VERSION ""

NS_ :

BS_:

BU_: BCMB_AUXM FCIM MRCMA_RSCM SCMJ BCMB_ALCM SCMB_PSM SCMD SCMC HVAC_RCCM MRCMB MRCMA DASM GFM_FTRM BCMB_CAPM DCMH SFMB SFMA SOBDMD_AHCM_FOH TRM GWM _delete BCMB_ABM SODL SCMF RTM RHVAC PDM DCMG DCMF DCME SCMH SCMG HSWM RSM SODR DDM RBM RGTM DSM SCME GENERIC TSTR

BO_ 839 FuelOpHeater_Stat: 8 SOBDMD_AHCM_FOH
 SG_ FohStop_B_Stat : 49|2@0+ (1,0) [0|3] "SED"  GWM
 SG_ FohMsgTxt_D_Rq : 4|3@0+ (1,0) [0|7] "SED"  GWM
 SG_ FohKeyOff_B_Rq : 6|1@0+ (1,0) [0|1] "SED"  GWM
 SG_ FohEnbl_B_Rq : 7|1@0+ (1,0) [0|1] "SED"  GWM
 SG_ FohTAllEnable_B_Stat : 17|2@0+ (1,0) [0|3] "SED"  GWM
 SG_ FohT2Mnte_T_Stat : 55|6@0+ (1,0) [0|63] "minute"  GWM
 SG_ FohT2Hr_T_Stat : 47|5@0+ (1,0) [0|31] "hour"  GWM
 SG_ FohT2Enable_B_Stat : 63|1@0+ (1,0) [0|1] "SED"  GWM
 SG_ FohT1Mnte_T_Stat : 39|6@0+ (1,0) [0|63] "minute"  GWM
 SG_ FohT1Hr_T_Stat : 31|5@0+ (1,0) [0|31] "hour"  GWM
 SG_ FohT1Enable_B_Stat : 0|1@0+ (1,0) [0|1] "SED"  GWM
 SG_ FohStrtMnte_T_Stat : 23|6@0+ (1,0) [0|63] "minute"  GWM
 SG_ FohStrtHr_T_Stat : 15|5@0+ (1,0) [0|31] "hour"  GWM
 SG_ FohStrtEnable_B_Stat : 1|1@0+ (1,0) [0|1] "SED"  GWM
 SG_ FohContOn_B_Stat : 33|2@0+ (1,0) [0|3] "SED"  GWM
 SG_ FohStrtDay_T_Stat : 10|3@0+ (1,0) [0|7] "SED"  GWM
 SG_ FohT2Wednesday_T_Stat : 56|1@0+ (1,0) [0|1] "SED"  GWM
 SG_ FohT2Tuesday_T_Stat : 57|1@0+ (1,0) [0|1] "SED"  GWM
 SG_ FohT2Thursday_T_Stat : 58|1@0+ (1,0) [0|1] "SED"  GWM
 SG_ FohT2Sunday_T_Stat : 59|1@0+ (1,0) [0|1] "SED"  GWM
 SG_ FohT2Saturday_T_Stat : 60|1@0+ (1,0) [0|1] "SED"  GWM
 SG_ FohT2Monday_T_Stat : 61|1@0+ (1,0) [0|1] "SED"  GWM
 SG_ FohT2Friday_T_Stat : 62|1@0+ (1,0) [0|1] "SED"  GWM
 SG_ FohT1Wednesday_T_Stat : 40|1@0+ (1,0) [0|1] "SED"  GWM
 SG_ FohT1Tuesday_T_Stat : 41|1@0+ (1,0) [0|1] "SED"  GWM
 SG_ FohT1Thursday_T_Stat : 42|1@0+ (1,0) [0|1] "SED"  GWM
 SG_ FohT1Sunday_T_Stat : 24|1@0+ (1,0) [0|1] "SED"  GWM
 SG_ FohT1Saturday_T_Stat : 25|1@0+ (1,0) [0|1] "SED"  GWM
 SG_ FohT1Monday_T_Stat : 26|1@0+ (1,0) [0|1] "SED"  GWM
 SG_ FohT1Friday_T_Stat : 5|1@0+ (1,0) [0|1] "SED"  GWM

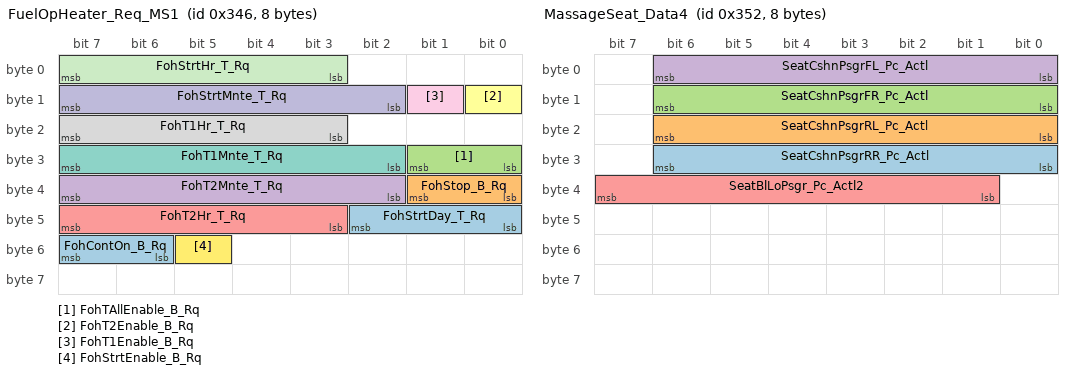
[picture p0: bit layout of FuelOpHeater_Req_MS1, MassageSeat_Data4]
BO_ 838 FuelOpHeater_Req_MS1: 8 GWM
 SG_ FohStrtDay_T_Rq : 42|3@0+ (1,0) [0|7] "SED"  SOBDMD_AHCM_FOH
 SG_ FohStop_B_Rq : 33|2@0+ (1,0) [0|3] "SED"  SOBDMD_AHCM_FOH
 SG_ FohTAllEnable_B_Rq : 25|2@0+ (1,0) [0|3] "SED"  SOBDMD_AHCM_FOH
 SG_ FohT2Mnte_T_Rq : 39|6@0+ (1,0) [0|63] "minute"  SOBDMD_AHCM_FOH
 SG_ FohT2Hr_T_Rq : 47|5@0+ (1,0) [0|31] "hour"  SOBDMD_AHCM_FOH
 SG_ FohT2Enable_B_Rq : 8|1@0+ (1,0) [0|1] "SED"  SOBDMD_AHCM_FOH
 SG_ FohT1Mnte_T_Rq : 31|6@0+ (1,0) [0|63] "minute"  SOBDMD_AHCM_FOH
 SG_ FohT1Hr_T_Rq : 23|5@0+ (1,0) [0|31] "hour"  SOBDMD_AHCM_FOH
 SG_ FohT1Enable_B_Rq : 9|1@0+ (1,0) [0|1] "SED"  SOBDMD_AHCM_FOH
 SG_ FohStrtMnte_T_Rq : 15|6@0+ (1,0) [0|63] "minute"  SOBDMD_AHCM_FOH
 SG_ FohStrtHr_T_Rq : 7|5@0+ (1,0) [0|31] "hour"  SOBDMD_AHCM_FOH
 SG_ FohStrtEnable_B_Rq : 53|1@0+ (1,0) [0|1] "SED"  SOBDMD_AHCM_FOH
 SG_ FohContOn_B_Rq : 55|2@0+ (1,0) [0|3] "SED"  SOBDMD_AHCM_FOH

BO_ 850 MassageSeat_Data4: 8 SCMH
 SG_ SeatCshnPsgrRR_Pc_Actl : 30|7@0+ (1,0) [0|126] "Percent"  GWM
 SG_ SeatCshnPsgrRL_Pc_Actl : 22|7@0+ (1,0) [0|126] "Percent"  GWM
 SG_ SeatCshnPsgrFR_Pc_Actl : 14|7@0+ (1,0) [0|126] "Percent"  GWM
 SG_ SeatCshnPsgrFL_Pc_Actl : 6|7@0+ (1,0) [0|126] "Percent"  GWM
 SG_ SeatBlLoPsgr_Pc_Actl2 : 39|7@0+ (1,0) [0|126] "Percent"  GWM

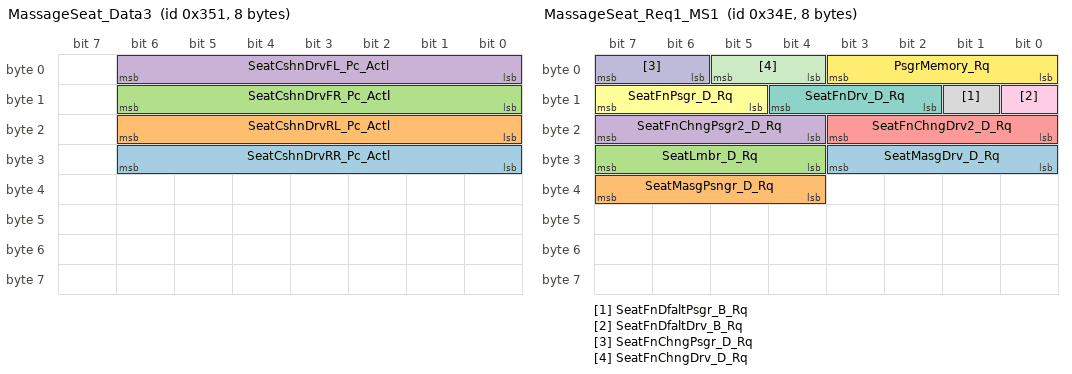
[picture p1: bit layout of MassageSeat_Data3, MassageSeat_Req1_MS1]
BO_ 849 MassageSeat_Data3: 8 SCMG
 SG_ SeatCshnDrvRR_Pc_Actl : 30|7@0+ (1,0) [0|126] "Percent"  GWM
 SG_ SeatCshnDrvRL_Pc_Actl : 22|7@0+ (1,0) [0|126] "Percent"  GWM
 SG_ SeatCshnDrvFR_Pc_Actl : 14|7@0+ (1,0) [0|126] "Percent"  GWM
 SG_ SeatCshnDrvFL_Pc_Actl : 6|7@0+ (1,0) [0|126] "Percent"  GWM

BO_ 846 MassageSeat_Req1_MS1: 8 GWM
 SG_ SeatMasgDrv_D_Rq : 27|4@0+ (1,0) [0|15] "SED"  SCMG
 SG_ SeatMasgPsngr_D_Rq : 39|4@0+ (1,0) [0|15] "SED"  SCMH
 SG_ SeatLmbr_D_Rq : 31|4@0+ (1,0) [0|15] "SED"  DSM,SCMB_PSM
 SG_ SeatFnChngPsgr2_D_Rq : 23|4@0+ (1,0) [0|15] "SED"  SCMG,SCMH
 SG_ SeatFnChngDrv2_D_Rq : 19|4@0+ (1,0) [0|15] "SED"  SCMG,SCMH
 SG_ SeatFnPsgr_D_Rq : 15|3@0+ (1,0) [0|7] "SED"  SCMH,SCMG
 SG_ SeatFnDrv_D_Rq : 12|3@0+ (1,0) [0|7] "SED"  SCMH,SCMG
 SG_ SeatFnDfaltPsgr_B_Rq : 9|1@0+ (1,0) [0|1] "SED"  SCMH,SCMG
 SG_ SeatFnDfaltDrv_B_Rq : 8|1@0+ (1,0) [0|1] "SED"  SCMH,SCMG
 SG_ SeatFnChngPsgr_D_Rq : 7|2@0+ (1,0) [0|3] "SED"  SCMH,SCMG
 SG_ SeatFnChngDrv_D_Rq : 5|2@0+ (1,0) [0|3] "SED"  SCMH,SCMG
 SG_ PsgrMemory_Rq : 3|4@0+ (1,0) [0|15] "SED"  SCMH,SCMG

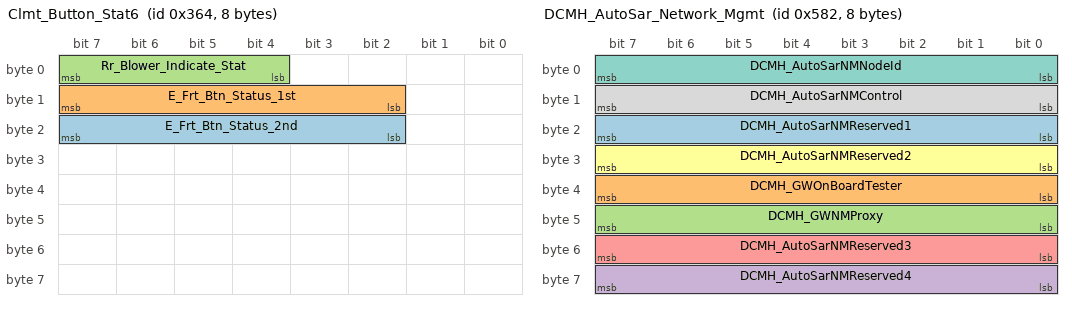
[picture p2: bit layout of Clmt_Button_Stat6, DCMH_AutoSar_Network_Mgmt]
BO_ 868 Clmt_Button_Stat6: 8 HVAC_RCCM
 SG_ E_Frt_Btn_Status_2nd : 23|6@0+ (1,0) [0|63] "SED"  GWM
 SG_ E_Frt_Btn_Status_1st : 15|6@0+ (1,0) [0|63] "SED"  GWM
 SG_ Rr_Blower_Indicate_Stat : 7|4@0+ (1,0) [0|15] "SED"  RHVAC

BO_ 1962 TesterPhysicalResDCME: 8 DCME
 SG_ TesterPhysicalResDCME : 7|64@0+ (1,0) [0|1.84467E+019] "unitless"  TSTR

BO_ 1410 DCMH_AutoSar_Network_Mgmt: 8 DCMH
 SG_ DCMH_AutoSarNMReserved1 : 23|8@0+ (1,0) [0|255] "unitless"  GWM
 SG_ DCMH_GWOnBoardTester : 39|8@0+ (1,0) [0|255] "unitless"  GWM
 SG_ DCMH_GWNMProxy : 47|8@0+ (1,0) [0|255] "unitless"  GWM
 SG_ DCMH_AutoSarNMReserved4 : 63|8@0+ (1,0) [0|255] "unitless"  GWM
 SG_ DCMH_AutoSarNMReserved3 : 55|8@0+ (1,0) [0|255] "unitless"  GWM
 SG_ DCMH_AutoSarNMReserved2 : 31|8@0+ (1,0) [0|255] "unitless"  GWM
 SG_ DCMH_AutoSarNMNodeId : 7|8@0+ (1,0) [0|255] "unitless"  GWM
 SG_ DCMH_AutoSarNMControl : 15|8@0+ (1,0) [0|255] "unitless"  GWM

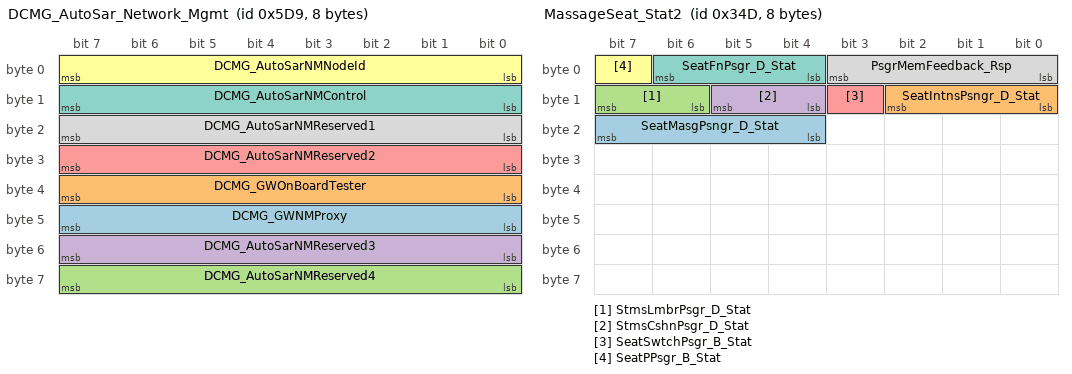
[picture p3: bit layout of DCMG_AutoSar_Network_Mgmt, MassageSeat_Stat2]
BO_ 1497 DCMG_AutoSar_Network_Mgmt: 8 DCMG
 SG_ DCMG_GWNMProxy : 47|8@0+ (1,0) [0|255] "unitless"  GWM
 SG_ DCMG_GWOnBoardTester : 39|8@0+ (1,0) [0|255] "unitless"  GWM
 SG_ DCMG_AutoSarNMReserved4 : 63|8@0+ (1,0) [0|255] "unitless"  GWM
 SG_ DCMG_AutoSarNMReserved3 : 55|8@0+ (1,0) [0|255] "unitless"  GWM
 SG_ DCMG_AutoSarNMReserved2 : 31|8@0+ (1,0) [0|255] "unitless"  GWM
 SG_ DCMG_AutoSarNMNodeId : 7|8@0+ (1,0) [0|255] "unitless"  GWM
 SG_ DCMG_AutoSarNMControl : 15|8@0+ (1,0) [0|255] "unitless"  GWM
 SG_ DCMG_AutoSarNMReserved1 : 23|8@0+ (1,0) [0|255] "unitless"  GWM

BO_ 1805 TesterPhysicalResSFMB: 8 SFMB
 SG_ TesterPhysicalResSFMB : 7|64@0+ (1,0) [0|1.84467E+019] "unitless"  TSTR

BO_ 845 MassageSeat_Stat2: 8 SCMH
 SG_ SeatMasgPsngr_D_Stat : 23|4@0+ (1,0) [0|15] "SED"  GWM
 SG_ SeatIntnsPsngr_D_Stat : 10|3@0+ (1,0) [0|7] "SED"  GWM
 SG_ StmsLmbrPsgr_D_Stat : 15|2@0+ (1,0) [0|3] "SED"  GWM
 SG_ StmsCshnPsgr_D_Stat : 13|2@0+ (1,0) [0|3] "SED"  GWM
 SG_ SeatSwtchPsgr_B_Stat : 11|1@0+ (1,0) [0|1] "SED"  GWM
 SG_ SeatPPsgr_B_Stat : 7|1@0+ (1,0) [0|1] "SED"  GWM
 SG_ SeatFnPsgr_D_Stat : 6|3@0+ (1,0) [0|7] "SED"  GWM
 SG_ PsgrMemFeedback_Rsp : 3|4@0+ (1,0) [0|15] "SED"  GWM

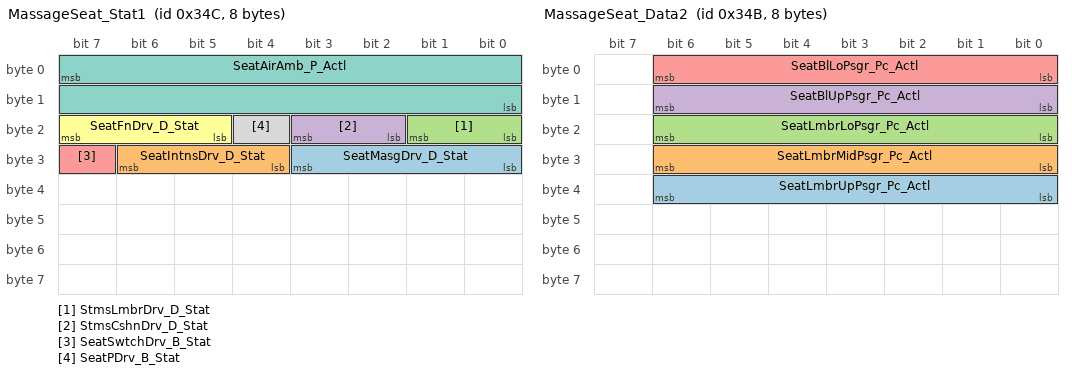
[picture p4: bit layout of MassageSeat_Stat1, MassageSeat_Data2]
BO_ 844 MassageSeat_Stat1: 8 SCMG
 SG_ SeatMasgDrv_D_Stat : 27|4@0+ (1,0) [0|15] "SED"  GWM
 SG_ SeatIntnsDrv_D_Stat : 30|3@0+ (1,0) [0|7] "SED"  GWM
 SG_ StmsLmbrDrv_D_Stat : 17|2@0+ (1,0) [0|3] "SED"  GWM
 SG_ StmsCshnDrv_D_Stat : 19|2@0+ (1,0) [0|3] "SED"  GWM
 SG_ SeatSwtchDrv_B_Stat : 31|1@0+ (1,0) [0|1] "SED"  GWM
 SG_ SeatFnDrv_D_Stat : 23|3@0+ (1,0) [0|7] "SED"  GWM
 SG_ SeatAirAmb_P_Actl : 7|16@0+ (0.01,0) [0|655.35] "KiloPascal"  GWM,SCMH
 SG_ SeatPDrv_B_Stat : 20|1@0+ (1,0) [0|1] "SED"  GWM

BO_ 843 MassageSeat_Data2: 8 SCMH
 SG_ SeatLmbrUpPsgr_Pc_Actl : 38|7@0+ (1,0) [0|127] "Percent"  GWM
 SG_ SeatLmbrMidPsgr_Pc_Actl : 30|7@0+ (1,0) [0|127] "Percent"  GWM
 SG_ SeatLmbrLoPsgr_Pc_Actl : 22|7@0+ (1,0) [0|127] "Percent"  GWM
 SG_ SeatBlUpPsgr_Pc_Actl : 14|7@0+ (1,0) [0|126] "Percent"  GWM
 SG_ SeatBlLoPsgr_Pc_Actl : 6|7@0+ (1,0) [0|126] "Percent"  GWM

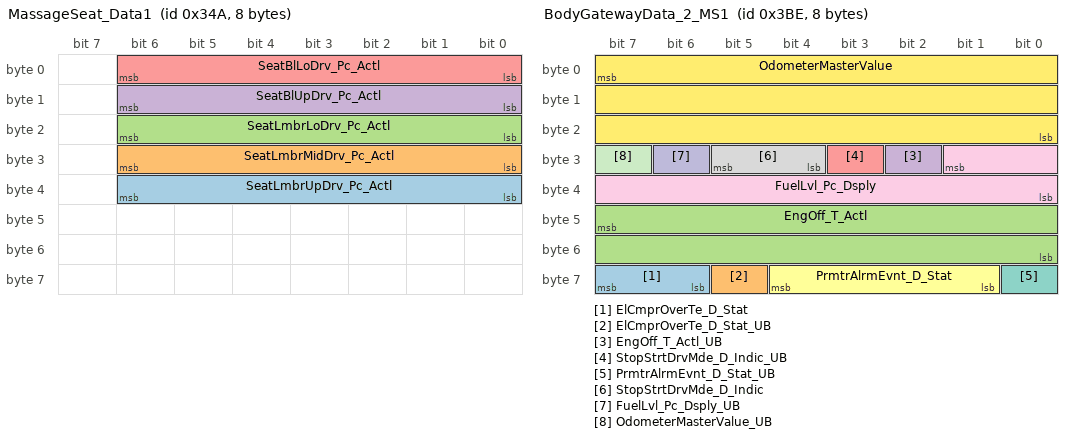
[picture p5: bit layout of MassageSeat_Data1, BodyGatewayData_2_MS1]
BO_ 842 MassageSeat_Data1: 8 SCMG
 SG_ SeatLmbrUpDrv_Pc_Actl : 38|7@0+ (1,0) [0|127] "Percent"  GWM
 SG_ SeatLmbrMidDrv_Pc_Actl : 30|7@0+ (1,0) [0|127] "Percent"  GWM
 SG_ SeatLmbrLoDrv_Pc_Actl : 22|7@0+ (1,0) [0|127] "Percent"  GWM
 SG_ SeatBlUpDrv_Pc_Actl : 14|7@0+ (1,0) [0|126] "Percent"  GWM
 SG_ SeatBlLoDrv_Pc_Actl : 6|7@0+ (1,0) [0|126] "Percent"  GWM

BO_ 1994 TesterPhysicalResRSM: 8 RSM
 SG_ TesterPhysicalResRSM : 7|64@0+ (1,0) [0|1.84467E+019] "unitless"  TSTR

BO_ 1986 TesterPhysicalReqRSM: 8 TSTR
 SG_ TesterPhysicalReqRSM : 7|64@0+ (1,0) [0|1.84467E+019] "unitless"  RSM

BO_ 958 BodyGatewayData_2_MS1: 8 GWM
 SG_ ElCmprOverTe_D_Stat : 63|2@0+ (1,0) [0|3] "SED"  FCIM,HVAC_RCCM
 SG_ ElCmprOverTe_D_Stat_UB : 61|1@0+ (1,0) [0|1] "SED"  FCIM,HVAC_RCCM
 SG_ EngOff_T_Actl : 47|16@0+ (1,0) [0|65534] "second^0.5"  FCIM,HVAC_RCCM
 SG_ EngOff_T_Actl_UB : 26|1@0+ (1,0) [0|1] "SED"  FCIM,HVAC_RCCM
 SG_ StopStrtDrvMde_D_Indic_UB : 27|1@0+ (1,0) [0|1] "SED"  FCIM,HVAC_RCCM
 SG_ PrmtrAlrmEvnt_D_Stat : 60|4@0+ (1,0) [0|15] "SED"  RSM
 SG_ PrmtrAlrmEvnt_D_Stat_UB : 56|1@0+ (1,0) [0|1] "SED"  RSM
 SG_ StopStrtDrvMde_D_Indic : 29|2@0+ (1,0) [0|3] "SED"  FCIM,HVAC_RCCM
 SG_ FuelLvl_Pc_Dsply : 25|10@0+ (0.108696,-5.217408) [-5.217408|105.9786] "Percent"  SOBDMD_AHCM_FOH
 SG_ FuelLvl_Pc_Dsply_UB : 30|1@0+ (1,0) [0|1] "SED"  SOBDMD_AHCM_FOH
 SG_ OdometerMasterValue_UB : 31|1@0+ (1,0) [0|1] "SED"  FCIM,DCMG,DCMH,HVAC_RCCM,SOBDMD_AHCM_FOH,RGTM
 SG_ OdometerMasterValue : 7|24@0+ (1,0) [0|16777214] "km"  FCIM,DCMG,DCMH,HVAC_RCCM,SOBDMD_AHCM_FOH,RGTM

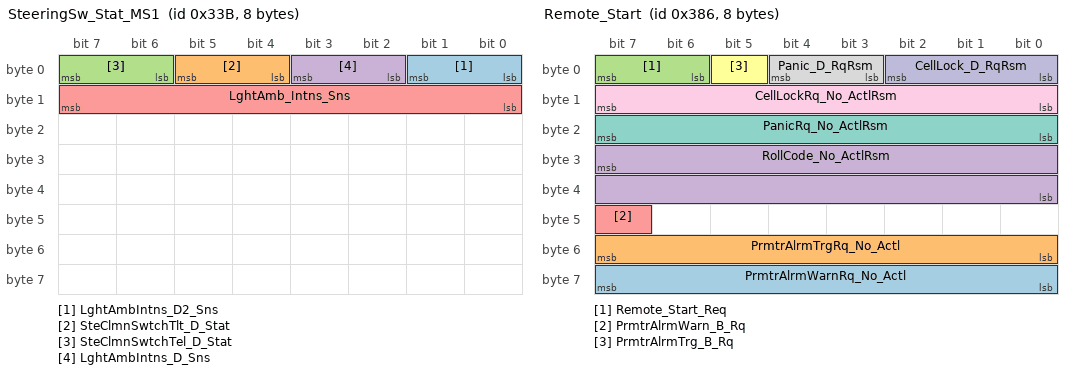
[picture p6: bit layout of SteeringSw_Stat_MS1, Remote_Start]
BO_ 827 SteeringSw_Stat_MS1: 8 GWM
 SG_ LghtAmbIntns_D2_Sns : 1|2@0+ (1,0) [0|3] "SED"  GENERIC
 SG_ SteClmnSwtchTlt_D_Stat : 5|2@0+ (1,0) [0|3] "SED"  BCMB_CAPM,DSM
 SG_ SteClmnSwtchTel_D_Stat : 7|2@0+ (1,0) [0|3] "SED"  BCMB_CAPM,DSM
 SG_ LghtAmbIntns_D_Sns : 3|2@0+ (1,0) [0|3] "SED"  GENERIC
 SG_ LghtAmb_Intns_Sns : 15|8@0+ (1,0) [0|255] "unitless"  GENERIC

BO_ 902 Remote_Start: 8 RSM
 SG_ PrmtrAlrmWarnRq_No_Actl : 63|8@0+ (1,0) [0|255] "unitless"  GWM
 SG_ PrmtrAlrmTrgRq_No_Actl : 55|8@0+ (1,0) [0|255] "unitless"  GWM
 SG_ Remote_Start_Req : 7|2@0+ (1,0) [0|3] "SED"  GWM
 SG_ RollCode_No_ActlRsm : 31|16@0+ (1,0) [0|65535] "unitless"  GWM
 SG_ PrmtrAlrmWarn_B_Rq : 47|1@0+ (1,0) [0|1] "SED"  GWM
 SG_ PrmtrAlrmTrg_B_Rq : 5|1@0+ (1,0) [0|1] "SED"  GWM
 SG_ PanicRq_No_ActlRsm : 23|8@0+ (1,0) [0|255] "unitless"  GWM
 SG_ Panic_D_RqRsm : 4|2@0+ (1,0) [0|3] "SED"  GWM
 SG_ CellLockRq_No_ActlRsm : 15|8@0+ (1,0) [0|255] "unitless"  GWM
 SG_ CellLock_D_RqRsm : 2|3@0+ (1,0) [0|7] "SED"  GWM

BO_ 765 GatewayData_MS1: 8 GWM
 SG_ CcStat_D_Actl_UB : 48|1@0+ (1,0) [0|1] "SED"  FCIM,HVAC_RCCM
 SG_ CcStat_D_Actl : 51|3@0+ (1,0) [0|7] "SED"  FCIM,HVAC_RCCM
 SG_ PrplTqMnSat_B_Actl_UB : 52|1@0+ (1,0) [0|1] "SED"  FCIM,HVAC_RCCM
 SG_ PrplTqMnSat_B_Actl : 53|1@0+ (1,0) [0|1] "SED"  FCIM,HVAC_RCCM
 SG_ ClimtBlwrLim_B_Rq : 61|1@0+ (1,0) [0|1] "SED"  FCIM,HVAC_RCCM
 SG_ ClimtBlwrLim_B_Rq_UB : 60|1@0+ (1,0) [0|1] "SED"  FCIM,HVAC_RCCM
 SG_ TrlrBrkActCnnct_B_Actl_UB : 62|1@0+ (1,0) [0|1] "SED"  SODR,SODL
 SG_ TrlrBrkActCnnct_B_Actl : 63|1@0+ (1,0) [0|1] "SED"  SODR,SODL
 SG_ EmPrflButtnAssoc_D_Rq : 17|2@0+ (1,0) [0|3] "SED"  DSM
 SG_ EmPrflButtnAssoc_D_Rq_UB : 56|1@0+ (1,0) [0|1] "SED"  DSM
 SG_ CamraFrntStat_D_Stat_UB : 32|1@0+ (1,0) [0|1] "SED"  FCIM,HVAC_RCCM
 SG_ CamraFrntStat_D_Stat : 34|2@0+ (1,0) [0|3] "SED"  FCIM,HVAC_RCCM
 SG_ AutoHoldSwMde_B_Ind_UB : 46|1@0+ (1,0) [0|1] "SED"  FCIM,HVAC_RCCM
 SG_ AutoHoldSwMde_B_Ind : 47|1@0+ (1,0) [0|1] "SED"  FCIM,HVAC_RCCM
 SG_ ValetMode_D_Stat_UB : 35|1@0+ (1,0) [0|1] "SED"  DSM
 SG_ ValetMode_D_Stat : 25|2@0+ (1,0) [0|3] "SED"  DSM
 SG_ SteWhlHeat_D_Stat : 39|4@0+ (1,0) [0|15] "SED"  FCIM,HVAC_RCCM
 SG_ Running_Board_Cmd_UB : 27|1@0+ (1,0) [0|1] "SED"  DSM,RBM
 SG_ Running_Board_Cmd : 29|2@0+ (1,0) [0|3] "SED"  DSM,RBM
 SG_ Bezel_Beeps_Rq_UB : 18|1@0+ (1,0) [0|1] "SED"  FCIM,HVAC_RCCM
 SG_ Bezel_Beeps_Rq : 20|2@0+ (1,0) [0|3] "SED"  FCIM,HVAC_RCCM
 SG_ Diagnostic_Operation_Rq_UB : 21|1@0+ (1,0) [0|1] "SED"  FCIM,HVAC_RCCM
 SG_ Bezel_Diag_State_Rq_UB : 23|1@0+ (1,0) [0|1] "SED"  FCIM,HVAC_RCCM
 SG_ Bezel_Diag_Module_Rq_UB : 22|1@0+ (1,0) [0|1] "SED"  FCIM,HVAC_RCCM
 SG_ Diagnostic_Operation_Rq : 11|4@0+ (1,0) [0|15] "SED"  FCIM,HVAC_RCCM
 SG_ Bezel_Diag_State_Rq : 1|2@0+ (1,0) [0|3] "SED"  FCIM,HVAC_RCCM
 SG_ Bezel_Diag_Module_Rq : 15|4@0+ (1,0) [0|15] "SED"  FCIM,HVAC_RCCM
 SG_ HMI_HMIMode_St_UB : 2|1@0+ (1,0) [0|1] "SED"  FCIM,DDM,PDM,DCME,DCMF,DCMG,DCMH,HVAC_RCCM,RGTM
 SG_ HMI_HMIMode_St : 5|3@0+ (1,0) [0|7] "SED"  FCIM,DDM,PDM,DCME,DCMF,DCMG,DCMH,HVAC_RCCM,RGTM
 SG_ Mc_VehUnitTempUsrSel_St_UB : 6|1@0+ (1,0) [0|1] "SED"  FCIM,HVAC_RCCM
 SG_ Mc_VehUnitTempUsrSel_St : 7|1@0+ (1,0) [0|1] "SED"  FCIM,HVAC_RCCM
 SG_ PsngrFrntDetct_D_Actl_UB : 40|1@0+ (1,0) [0|1] "SED"  FCIM,HVAC_RCCM
 SG_ PsngrFrntDetct_D_Actl : 55|2@0+ (1,0) [0|3] "SED"  FCIM,HVAC_RCCM
 SG_ SteWhlHeat_D_Stat_UB : 26|1@0+ (1,0) [0|1] "SED"  FCIM,HVAC_RCCM
 SG_ PrkAidLamp_D_Rq : 43|2@0+ (1,0) [0|3] "SED"  GENERIC
 SG_ PrkAidLamp_D_Rq_UB : 41|1@0+ (1,0) [0|1] "SED"  GENERIC
 SG_ ParkDetect_Stat_UB : 30|1@0+ (1,0) [0|1] "SED"  RSM
 SG_ ParkDetect_Stat : 31|1@0+ (1,0) [0|1] "SED"  RSM
 SG_ Voice_Blower_Limit : 45|1@0+ (1,0) [0|1] "SED"  FCIM,GENERIC,HVAC_RCCM
 SG_ Voice_Blower_Limit_UB : 44|1@0+ (1,0) [0|1] "SED"  FCIM,GENERIC,HVAC_RCCM
 SG_ PwStep_D_DrvInhbt_UB : 57|1@0+ (1,0) [0|1] "SED"  DSM,RBM
 SG_ PwStep_D_DrvInhbt : 59|2@0+ (1,0) [0|3] "SED"  DSM,RBM

BO_ 710 BEZEL_RDISP_WORD_Tx: 8 HVAC_RCCM
 SG_ BEZEL_RDISP_WORD_Tx : 7|64@0+ (1,0) [0|1.84467440737096E+019] "unitless"  GWM

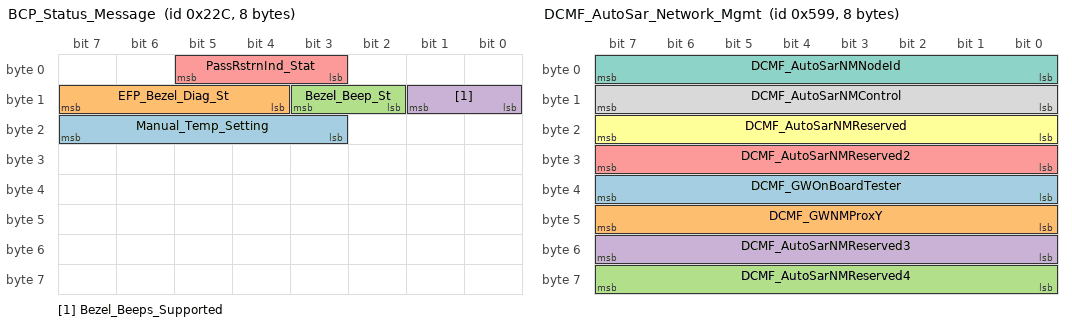
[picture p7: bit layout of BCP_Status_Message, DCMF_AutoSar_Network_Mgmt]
BO_ 556 BCP_Status_Message: 8 FCIM
 SG_ Manual_Temp_Setting : 23|5@0+ (1,0) [0|31] "SED"  GWM
 SG_ EFP_Bezel_Diag_St : 15|4@0+ (1,0) [0|15] "SED"  GWM
 SG_ Bezel_Beep_St : 11|2@0+ (1,0) [0|3] "SED"  GWM
 SG_ Bezel_Beeps_Supported : 9|2@0+ (1,0) [0|3] "SED"  GWM
 SG_ PassRstrnInd_Stat : 5|3@0+ (1,0) [0|7] "SED"  GWM

BO_ 1815 TesterPhysicalReqRLCMA: 8 TSTR
 SG_ TesterPhysicalReqRLCMA : 7|64@0+ (1,0) [0|1.84467E+019] "unitless"  GENERIC

BO_ 1433 DCMF_AutoSar_Network_Mgmt: 8 DCMF
 SG_ DCMF_GWOnBoardTester : 39|8@0+ (1,0) [0|255] "unitless"  GWM
 SG_ DCMF_GWNMProxY : 47|8@0+ (1,0) [0|255] "unitless"  GWM
 SG_ DCMF_AutoSarNMReserved4 : 63|8@0+ (1,0) [0|255] "unitless"  GWM
 SG_ DCMF_AutoSarNMReserved3 : 55|8@0+ (1,0) [0|255] "unitless"  GWM
 SG_ DCMF_AutoSarNMReserved2 : 31|8@0+ (1,0) [0|255] "unitless"  GWM
 SG_ DCMF_AutoSarNMReserved : 23|8@0+ (1,0) [0|255] "unitless"  GWM
 SG_ DCMF_AutoSarNMNodeId : 7|8@0+ (1,0) [0|255] "unitless"  GWM
 SG_ DCMF_AutoSarNMControl : 15|8@0+ (1,0) [0|255] "unitless"  GWM

BO_ 1983 TesterPhysicalResBCMB: 8 BCMB_ABM
 SG_ TesterPhysicalResBCMB : 7|64@0+ (1,0) [0|1.84467E+019] "unitless"  TSTR

BO_ 1975 TesterPhysicalReqBCMB: 8 TSTR
 SG_ TesterPhysicalReqBCMB : 7|64@0+ (1,0) [0|1.84467E+019] "unitless"  BCMB_AUXM,BCMB_CAPM,BCMB_ALCM,BCMB_ABM

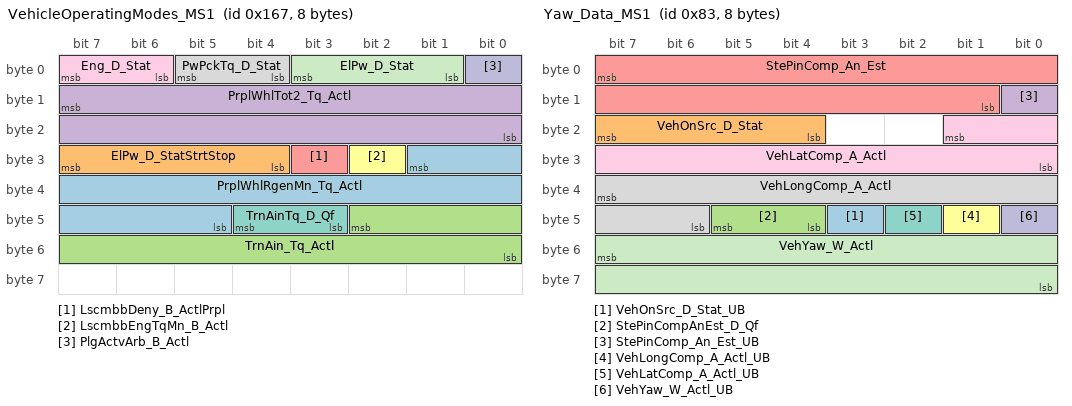
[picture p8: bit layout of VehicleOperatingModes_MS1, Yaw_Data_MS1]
BO_ 359 VehicleOperatingModes_MS1: 8 GWM
 SG_ PrplWhlRgenMn_Tq_Actl : 25|13@0+ (4,-16380) [-16380|16380] "Nm"  GENERIC
 SG_ ElPw_D_StatStrtStop : 31|4@0+ (1,0) [0|15] "SED"  GENERIC
 SG_ TrnAin_Tq_Actl : 42|11@0+ (1,-500) [-500|1547] "Nm"  GENERIC
 SG_ PrplWhlTot2_Tq_Actl : 15|16@0+ (4,-131072) [-131072|131060] "Nm"  GENERIC
 SG_ LscmbbDeny_B_ActlPrpl : 27|1@0+ (1,0) [0|1] "SED"  GENERIC
 SG_ LscmbbEngTqMn_B_Actl : 26|1@0+ (1,0) [0|1] "SED"  GENERIC
 SG_ TrnAinTq_D_Qf : 44|2@0+ (1,0) [0|3] "SED"  GENERIC
 SG_ PwPckTq_D_Stat : 5|2@0+ (1,0) [0|3] "SED"  FCIM,GFM_FTRM,MRCMA_RSCM,SCMB_PSM,SCME,HVAC_RCCM,MRCMA,MRCMB,DCME,DCMF,DCMG,DCMH,RSM,RHVAC,BCMB_CAPM,HSWM,TRM,SCMH,SCMG,SCMF,RTM,RGTM,RBM,PDM,DSM,DDM,SOBDMD_AHCM_FOH
 SG_ Eng_D_Stat : 7|2@0+ (1,0) [0|3] "SED"  TRM,FCIM,HVAC_RCCM,SOBDMD_AHCM_FOH
 SG_ PlgActvArb_B_Actl : 0|1@0+ (1,0) [0|1] "SED"  GENERIC
 SG_ ElPw_D_Stat : 3|3@0+ (1,0) [0|7] "SED"  FCIM,GFM_FTRM,SODR,MRCMA_RSCM,SODL,SCMB_PSM,SCME,HVAC_RCCM,MRCMA,MRCMB,DCME,DCMF,DCMG,DCMH,RHVAC,BCMB_CAPM,SCMG,SCMH,TRM,SOBDMD_AHCM_FOH,DDM,DSM,PDM,RBM,RGTM,RTM,SCMF

BO_ 131 Yaw_Data_MS1: 8 GWM
 SG_ VehOnSrc_D_Stat_UB : 43|1@0+ (1,0) [0|1] "SED"  GFM_FTRM,DSM,HVAC_RCCM,DDM,PDM
 SG_ VehOnSrc_D_Stat : 23|4@0+ (1,0) [0|15] "SED"  GFM_FTRM,DSM,HVAC_RCCM,DDM,PDM
 SG_ StePinCompAnEst_D_Qf : 45|2@0+ (1,0) [0|3] "SED"  GENERIC,SODR,SODL
 SG_ StePinComp_An_Est_UB : 8|1@0+ (1,0) [0|1] "SED"  GENERIC,SODR,SODL
 SG_ StePinComp_An_Est : 7|15@0+ (0.1,-1600) [-1600|1676.7] "degrees"  SODR,GENERIC,SODL
 SG_ VehLongComp_A_Actl_UB : 41|1@0+ (1,0) [0|1] "SED"  DCMG,DCMH,RGTM
 SG_ VehLatComp_A_Actl_UB : 42|1@0+ (1,0) [0|1] "SED"  RGTM
 SG_ VehLongComp_A_Actl : 39|10@0+ (0.035,-17.9) [-17.9|17.835] "m/s^2"  DCMG,DCMH,RGTM
 SG_ VehLatComp_A_Actl : 17|10@0+ (0.035,-17.9) [-17.9|17.835] "m/s^2"  RGTM
 SG_ VehYaw_W_Actl_UB : 40|1@0+ (1,0) [0|1] "SED"  GENERIC,SODR,SODL
 SG_ VehYaw_W_Actl : 55|16@0+ (0.0002,-6.5) [-6.5|6.6066] "rad/s"  GENERIC,SODR,SODL

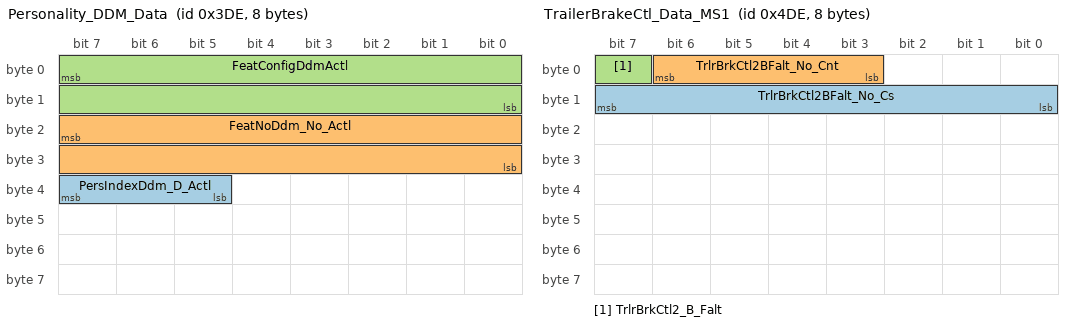
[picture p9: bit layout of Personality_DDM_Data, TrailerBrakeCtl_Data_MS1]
BO_ 990 Personality_DDM_Data: 8 DDM
 SG_ PersIndexDdm_D_Actl : 39|3@0+ (1,0) [0|7] "SED"  GWM
 SG_ FeatNoDdm_No_Actl : 23|16@0+ (1,0) [0|65535] "Number"  GWM
 SG_ FeatConfigDdmActl : 7|16@0+ (1,0) [0|65535] "Undefined"  GWM

BO_ 1246 TrailerBrakeCtl_Data_MS1: 8 TRM
 SG_ TrlrBrkCtl2BFalt_No_Cs : 15|8@0+ (1,0) [0|255] "Unitless"  GWM
 SG_ TrlrBrkCtl2BFalt_No_Cnt : 6|4@0+ (1,0) [0|15] "Unitless"  GWM
 SG_ TrlrBrkCtl2_B_Falt : 7|1@0+ (1,0) [0|1] "SED"  GWM

BO_ 1363 MRCMA_Network_MgmtM: 8 MRCMA
 SG_ MRCMA_Network_Mgmt : 7|64@0+ (1,0) [0|1.84467440737096E+019] "unitless"  GENERIC

BO_ 1899 TesterPhysicalResSCMD: 8 SCMD
 SG_ TesterPhysicalResSCMD : 7|64@0+ (1,0) [0|1.84467E+019] "unitless"  TSTR

BO_ 1003 Personality_BCM2_Data_MS1: 8 GWM
 SG_ TailLghtLoadMde_D_Stat : 60|3@0+ (1,0) [0|7] "SED"  GENERIC
 SG_ Pers4Key_D_Stat : 49|2@0+ (1,0) [0|3] "SED"  GENERIC
 SG_ Pers3Key_D_Stat : 41|2@0+ (1,0) [0|3] "SED"  GENERIC
 SG_ Pers2Key_D_Stat : 43|2@0+ (1,0) [0|3] "SED"  GENERIC
 SG_ Pers1Key_D_Stat : 12|2@0+ (1,0) [0|3] "SED"  GENERIC
 SG_ EmPrflNo_D_Stat : 52|3@0+ (1,0) [0|7] "SED"  GENERIC
 SG_ EmPrflKeyAssoc_D_Stat : 55|3@0+ (1,0) [0|7] "SED"  GENERIC
 SG_ PersRecallSrc_D_Actl : 63|3@0+ (1,0) [0|7] "SED"  BCMB_CAPM,DSM
 SG_ VehKeyActv_D_Stat : 47|4@0+ (1,0) [0|15] "SED"  GENERIC
 SG_ PersSetupRestr_D_Actl : 21|2@0+ (1,0) [0|3] "SED"  FCIM,GENERIC,HVAC_RCCM,PDM,BCMB_CAPM,DDM,DSM
 SG_ PersSetupAccessCtrl : 19|1@0+ (1,0) [0|1] "SED"  FCIM,GENERIC,HVAC_RCCM,BCMB_CAPM,DDM,DSM
 SG_ PersSetup_No_Actl : 31|16@0+ (1,0) [0|65535] "Number"  FCIM,GENERIC,HVAC_RCCM,PDM,BCMB_CAPM,DDM,DSM
 SG_ PersConflict_D_Actl : 22|1@0+ (1,0) [0|1] "SED"  GENERIC
 SG_ AssocConfirm_D_Actl : 15|3@0+ (1,0) [0|7] "SED"  GENERIC
 SG_ RecallEvent_No_Cnt : 7|8@0+ (1,0) [0|255] "Counts"  FCIM,GENERIC,HVAC_RCCM,BCMB_CAPM,SCMG,SCMH,DDM,DSM
 SG_ PersNo_D_Actl : 10|3@0+ (1,0) [0|7] "SED"  FCIM,GENERIC,HVAC_RCCM,BCMB_CAPM,DDM,DSM,SCMG,SCMH
 SG_ PersNoPos_D_Actl : 18|3@0+ (1,0) [0|7] "SED"  GENERIC,BCMB_CAPM,SCMG,SCMH,DSM

BO_ 1945 TesterPhysicalResTRM: 8 TRM
 SG_ TesterPhysicalResTRM : 7|64@0+ (1,0) [0|1.84467E+019] "unitless"  TSTR

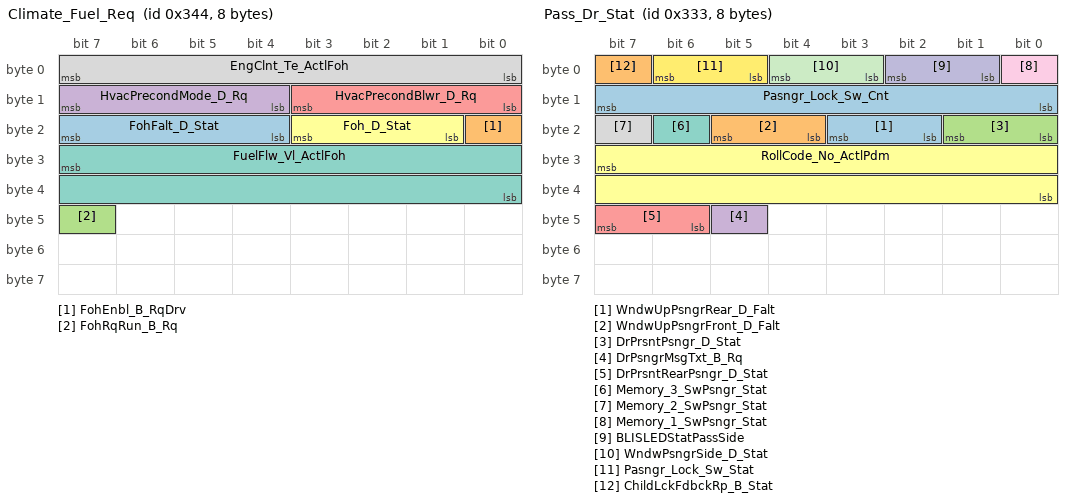
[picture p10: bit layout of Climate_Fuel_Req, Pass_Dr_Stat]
BO_ 836 Climate_Fuel_Req: 8 SOBDMD_AHCM_FOH
 SG_ FohFalt_D_Stat : 23|4@0+ (1,0) [0|15] "SED"  GWM
 SG_ FohEnbl_B_RqDrv : 16|1@0+ (1,0) [0|1] "SED"  GWM
 SG_ FohRqRun_B_Rq : 47|1@0+ (1,0) [0|1] "SED"  GWM
 SG_ HvacPrecondMode_D_Rq : 15|4@0+ (1,0) [0|15] "SED"  FCIM,HVAC_RCCM,GWM
 SG_ HvacPrecondBlwr_D_Rq : 11|4@0+ (1,0) [0|15] "SED"  FCIM,HVAC_RCCM,GWM
 SG_ Foh_D_Stat : 19|3@0+ (1,0) [0|7] "SED"  FCIM,HVAC_RCCM,GWM
 SG_ FuelFlw_Vl_ActlFoh : 31|16@0+ (25,0) [0|1638375] "microlitre"  GWM
 SG_ EngClnt_Te_ActlFoh : 7|8@0+ (1,-50) [-50|204] "degC"  FCIM,HVAC_RCCM,GWM

BO_ 819 Pass_Dr_Stat: 8 PDM
 SG_ WndwUpPsngrRear_D_Falt : 19|2@0+ (1,0) [0|3] "SED"  GWM,SODR,SODL
 SG_ WndwUpPsngrFront_D_Falt : 21|2@0+ (1,0) [0|3] "SED"  GWM,SODR,SODL
 SG_ DrPrsntPsngr_D_Stat : 17|2@0+ (1,0) [0|3] "SED"  GWM
 SG_ DrPsngrMsgTxt_B_Rq : 45|1@0+ (1,0) [0|1] "SED"  GWM
 SG_ DrPrsntRearPsngr_D_Stat : 47|2@0+ (1,0) [0|3] "SED"  GWM
 SG_ RollCode_No_ActlPdm : 31|16@0+ (1,0) [0|65535] "Unitless"  GWM
 SG_ Memory_3_SwPsngr_Stat : 22|1@0+ (1,0) [0|1] "SED"  SCMB_PSM,GWM
 SG_ Memory_2_SwPsngr_Stat : 23|1@0+ (1,0) [0|1] "SED"  SCMB_PSM,GWM
 SG_ Memory_1_SwPsngr_Stat : 0|1@0+ (1,0) [0|1] "SED"  SCMB_PSM,GWM
 SG_ BLISLEDStatPassSide : 2|2@0+ (1,0) [0|3] "SED"  SODR,SODL,GWM
 SG_ WndwPsngrSide_D_Stat : 4|2@0+ (1,0) [0|3] "SED"  GWM
 SG_ Pasngr_Lock_Sw_Stat : 6|2@0+ (1,0) [0|3] "SED"  GWM
 SG_ Pasngr_Lock_Sw_Cnt : 15|8@0+ (1,0) [0|255] "Cnt"  GWM
 SG_ ChildLckFdbckRp_B_Stat : 7|1@0+ (1,0) [0|1] "SED"  GWM

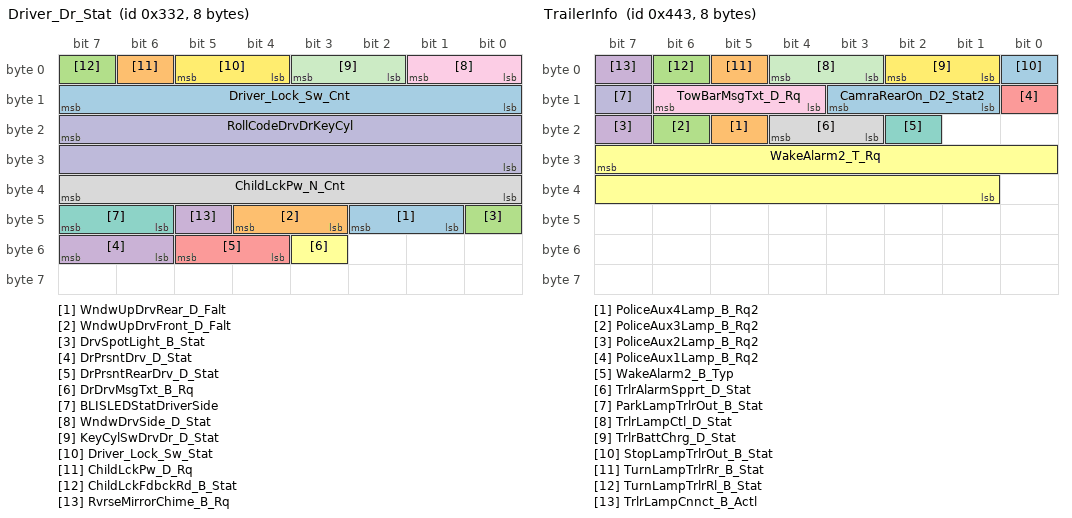
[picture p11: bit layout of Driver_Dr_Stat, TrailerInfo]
BO_ 818 Driver_Dr_Stat: 8 DDM
 SG_ WndwUpDrvRear_D_Falt : 42|2@0+ (1,0) [0|3] "SED"  GWM,SODR,SODL
 SG_ WndwUpDrvFront_D_Falt : 44|2@0+ (1,0) [0|3] "SED"  GWM,SODR,SODL
 SG_ DrvSpotLight_B_Stat : 40|1@0+ (1,0) [0|1] "SED"  PDM,GWM
 SG_ DrPrsntDrv_D_Stat : 55|2@0+ (1,0) [0|3] "SED"  GWM
 SG_ DrPrsntRearDrv_D_Stat : 53|2@0+ (1,0) [0|3] "SED"  GWM
 SG_ DrDrvMsgTxt_B_Rq : 51|1@0+ (1,0) [0|1] "SED"  GWM
 SG_ BLISLEDStatDriverSide : 47|2@0+ (1,0) [0|3] "SED"  SODR,GWM,SODL
 SG_ ChildLckPw_N_Cnt : 39|8@0+ (1,0) [0|255] "unitless"  GWM
 SG_ WndwDrvSide_D_Stat : 1|2@0+ (1,0) [0|3] "SED"  GWM
 SG_ RollCodeDrvDrKeyCyl : 23|16@0+ (1,0) [0|65535] "Unitless"  GWM
 SG_ KeyCylSwDrvDr_D_Stat : 3|2@0+ (1,0) [0|3] "SED"  GWM
 SG_ Driver_Lock_Sw_Stat : 5|2@0+ (1,0) [0|3] "SED"  GWM
 SG_ Driver_Lock_Sw_Cnt : 15|8@0+ (1,0) [0|255] "Cnt"  GWM
 SG_ ChildLckPw_D_Rq : 6|1@0+ (1,0) [0|1] "SED"  GWM
 SG_ ChildLckFdbckRd_B_Stat : 7|1@0+ (1,0) [0|1] "SED"  GWM
 SG_ RvrseMirrorChime_B_Rq : 45|1@0+ (1,0) [0|1] "SED"  DSM,GWM

BO_ 817 Locking_Systems_2_MS1: 8 GWM
 SG_ ChildLckMde_B_Stat : 56|1@0+ (1,0) [0|1] "SED"  DCME,DCMF,DCMG,DCMH
 SG_ VehLckInd_D_Rq : 58|2@0+ (1,0) [0|3] "SED"  DDM,PDM,DCME,DCMF,DCMG,DCMH
 SG_ DrTgateOpen_B_Rq : 59|1@0+ (1,0) [0|1] "SED"  RGTM
 SG_ DrTgateExtSwMde_B_Stat : 32|1@0+ (1,0) [0|1] "SED"  RGTM
 SG_ Remote_Device_Feedback : 50|3@0+ (1,0) [0|7] "SED"  RSM,RTM
 SG_ R_Pwr_Sliding_Dr_Rqst : 36|1@0+ (1,0) [0|1] "SED"  DCMG,DCMH,GENERIC
 SG_ Power_Liftgate_Rqst : 0|1@0+ (1,0) [0|1] "SED"  MRCMA_RSCM,RGTM
 SG_ Power_Decklid_Rqst : 1|1@0+ (1,0) [0|1] "SED"  RGTM
 SG_ L_Pwr_Sliding_Dr_Rqst : 3|1@0+ (1,0) [0|1] "SED"  DCMG,DCMH,GENERIC
 SG_ Keyfob_Pad_Msg_Count : 15|8@0+ (1,0) [0|255] "Counts"  DCMG,DCMH,MRCMA_RSCM,RGTM
 SG_ Veh_Lock_Requestor : 55|5@0+ (1,0) [0|31] "SED"  FCIM,DSM,HVAC_RCCM,DCME,DCMF,DCMG,DCMH,RSM,DDM,PDM
 SG_ Veh_Lock_EvNum : 47|8@0+ (1,0) [0|255] "unitless"  FCIM,DSM,HVAC_RCCM,DCME,DCMF,DCMG,DCMH,RSM,DDM,PDM
 SG_ Veh_Lock_Sub_Id : 63|4@0+ (1,0) [0|15] "SED"  RSM,DDM,PDM
 SG_ ChildLck_D_Dsply : 7|2@0+ (1,0) [0|3] "SED"  DCMG,DCMH,DDM
 SG_ WindowLockout_B_Stat : 35|1@0+ (1,0) [0|1] "SED"  SCMG,SCMJ,SCMH,SCMC,SCMD,DCME,DCMF,DCMG,DCMH,SCMB_PSM,DDM
 SG_ RollCodeUnlock : 23|16@0+ (1,0) [0|65535] "Unitless"  DCMG,DCMH,PDM,RSM,DDM
 SG_ Lockmsgtxt_D_Rq : 39|3@0+ (1,0) [0|7] "SED"  GENERIC
 SG_ LockInhibit : 2|1@0+ (1,0) [0|1] "SED"  DCMG,DCMH,RGTM
 SG_ Veh_Lock_Status : 34|2@0+ (1,0) [0|3] "SED"  FCIM,DSM,MRCMA_RSCM,HVAC_RCCM,RBM,DCME,DCMF,DCMG,DCMH,RSM,SCMJ,DDM,PDM,RGTM
 SG_ FobComm_D_Stat : 5|2@0+ (1,0) [0|3] "SED"  GENERIC,RTM

BO_ 1091 TrailerInfo: 8 TRM
 SG_ CamraRearOn_D2_Stat2 : 11|3@0+ (1,0) [0|7] "SED"  GWM
 SG_ PoliceAux4Lamp_B_Rq2 : 21|1@0+ (1,0) [0|1] "SED"  GWM
 SG_ PoliceAux3Lamp_B_Rq2 : 22|1@0+ (1,0) [0|1] "SED"  GWM
 SG_ PoliceAux2Lamp_B_Rq2 : 23|1@0+ (1,0) [0|1] "SED"  GWM
 SG_ PoliceAux1Lamp_B_Rq2 : 8|1@0+ (1,0) [0|1] "SED"  GWM
 SG_ WakeAlarm2_T_Rq : 31|15@0+ (1,0) [0|32767] "minute"  GENERIC
 SG_ WakeAlarm2_B_Typ : 18|1@0+ (1,0) [0|1] "SED"  GENERIC
 SG_ TrlrAlarmSpprt_D_Stat : 20|2@0+ (1,0) [0|3] "SED"  GWM
 SG_ TowBarMsgTxt_D_Rq : 14|3@0+ (1,0) [0|7] "SED"  GWM
 SG_ ParkLampTrlrOut_B_Stat : 15|1@0+ (1,0) [0|1] "SED"  GWM
 SG_ TrlrLampCtl_D_Stat : 4|2@0+ (1,0) [0|3] "SED"  GWM
 SG_ TrlrBattChrg_D_Stat : 2|2@0+ (1,0) [0|3] "SED"  GWM
 SG_ StopLampTrlrOut_B_Stat : 0|1@0+ (1,0) [0|1] "SED"  GWM
 SG_ TurnLampTrlrRr_B_Stat : 5|1@0+ (1,0) [0|1] "SED"  GWM
 SG_ TurnLampTrlrRl_B_Stat : 6|1@0+ (1,0) [0|1] "SED"  GWM
 SG_ TrlrLampCnnct_B_Actl : 7|1@0+ (1,0) [0|1] "SED"  SODR,SODL,GWM

BO_ 1865 TesterPhysicalResPDM: 8 PDM
 SG_ TesterPhysicalResPDM : 7|64@0+ (1,0) [0|1.84467E+019] "unitless"  TSTR

BO_ 1857 TesterPhysicalReqPDM: 8 TSTR
 SG_ TesterPhysicalReqPDM : 7|64@0+ (1,0) [0|1.84467E+019] "unitless"  PDM

BO_ 1819 TesterPhysicalResSCMH: 8 SCMH
 SG_ TesterPhysicalResSCMH : 7|64@0+ (1,0) [0|1.84467E+019] "unitless"  TSTR

BO_ 1818 TesterPhysicalResSCMG: 8 SCMG
 SG_ TesterPhysicalResSCMG : 7|64@0+ (1,0) [0|1.84467E+019] "unitless"  TSTR

BO_ 1811 TesterPhysicalReqSCMH: 8 TSTR
 SG_ TesterPhysicalReqSCMH : 7|64@0+ (1,0) [0|1.84467E+019] "unitless"  SCMH

BO_ 1810 TesterPhysicalReqSCMG: 8 TSTR
 SG_ TesterPhysicalReqSCMG : 7|64@0+ (1,0) [0|1.84467E+019] "unitless"  SCMG

BO_ 1310 GWM_Network_MgmtM_MS1: 8 GWM
 SG_ GWM_Network_Mgmt_MS1 : 7|64@0+ (1,0) [0|1.84467440737096E+019] "unitless"  BCMB_ABM,BCMB_ALCM,BCMB_CAPM,MRCMA,MRCMA_RSCM,MRCMB,RSM,GENERIC,RTM,HVAC_RCCM

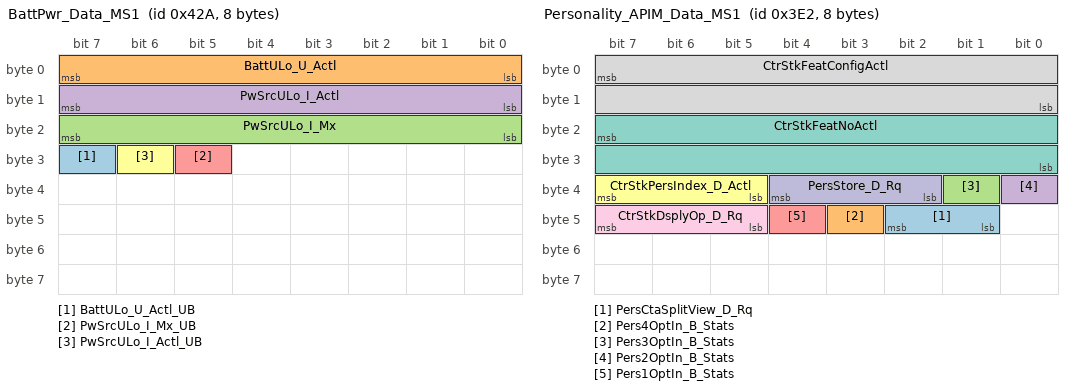
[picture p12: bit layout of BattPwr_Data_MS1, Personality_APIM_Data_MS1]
BO_ 1066 BattPwr_Data_MS1: 8 GWM
 SG_ BattULo_U_Actl_UB : 31|1@0+ (1,0) [0|1] "SED"  FCIM,HVAC_RCCM
 SG_ BattULo_U_Actl : 7|8@0+ (0.0625,0) [0|15.875] "volt"  FCIM,HVAC_RCCM
 SG_ PwSrcULo_I_Mx : 23|8@0+ (1,0) [0|254] "ampere"  FCIM,HVAC_RCCM
 SG_ PwSrcULo_I_Actl : 15|8@0+ (1,0) [0|254] "ampere"  FCIM,HVAC_RCCM
 SG_ PwSrcULo_I_Mx_UB : 29|1@0+ (1,0) [0|1] "SED"  FCIM,HVAC_RCCM
 SG_ PwSrcULo_I_Actl_UB : 30|1@0+ (1,0) [0|1] "SED"  FCIM,HVAC_RCCM

BO_ 994 Personality_APIM_Data_MS1: 8 GWM
 SG_ PersCtaSplitView_D_Rq : 42|2@0+ (1,0) [0|3] "SED"  GENERIC
 SG_ Pers4OptIn_B_Stats : 43|1@0+ (1,0) [0|1] "SED"  GENERIC
 SG_ Pers3OptIn_B_Stats : 33|1@0+ (1,0) [0|1] "SED"  GENERIC
 SG_ Pers2OptIn_B_Stats : 32|1@0+ (1,0) [0|1] "SED"  GENERIC
 SG_ Pers1OptIn_B_Stats : 44|1@0+ (1,0) [0|1] "SED"  GENERIC
 SG_ CtrStkPersIndex_D_Actl : 39|3@0+ (1,0) [0|7] "SED"  FCIM,HVAC_RCCM,PDM,BCMB_CAPM,DDM,DSM,SCMG,SCMH
 SG_ CtrStkFeatNoActl : 23|16@0+ (1,0) [0|65535] "Undefined"  FCIM,HVAC_RCCM,PDM,BCMB_CAPM,DDM,DSM
 SG_ CtrStkFeatConfigActl : 7|16@0+ (1,0) [0|65535] "Undefined"  FCIM,HVAC_RCCM,PDM,BCMB_CAPM,DDM,DSM
 SG_ CtrStkDsplyOp_D_Rq : 47|3@0+ (1,0) [0|7] "SED"  FCIM,HVAC_RCCM,PDM,BCMB_CAPM,DDM,DSM,SCMG,SCMH
 SG_ PersStore_D_Rq : 36|3@0+ (1,0) [0|7] "SED"  DDM,BCMB_CAPM,DSM

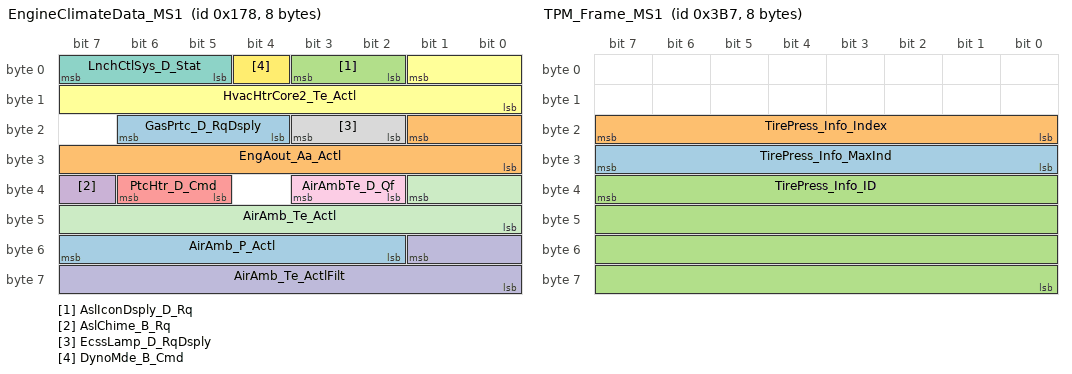
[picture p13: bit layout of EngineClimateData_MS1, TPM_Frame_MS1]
BO_ 376 EngineClimateData_MS1: 8 GWM
 SG_ GasPrtc_D_RqDsply : 22|3@0+ (1,0) [0|7] "SED"  GENERIC
 SG_ EngAout_Aa_Actl : 17|10@0+ (0.05,-25.6) [-25.6|25.55] "rpm/ms"  GENERIC
 SG_ AslIconDsply_D_Rq : 3|2@0+ (1,0) [0|3] "SED"  GENERIC
 SG_ AslChime_B_Rq : 39|1@0+ (1,0) [0|1] "SED"  GENERIC
 SG_ PtcHtr_D_Cmd : 38|2@0+ (1,0) [0|3] "SED"  GENERIC
 SG_ HvacHtrCore2_Te_Actl : 1|10@0+ (0.25,-50) [-50|205.5] "degC"  FCIM,HVAC_RCCM
 SG_ LnchCtlSys_D_Stat : 7|3@0+ (1,0) [0|7] "SED"  GWM
 SG_ EcssLamp_D_RqDsply : 19|2@0+ (1,0) [0|3] "SED"  GENERIC
 SG_ AirAmbTe_D_Qf : 35|2@0+ (1,0) [0|3] "SED"  FCIM,HVAC_RCCM
 SG_ AirAmb_Te_ActlFilt : 49|10@0+ (0.25,-128) [-128|127.75] "deg C"  FCIM,HVAC_RCCM,RGTM
 SG_ AirAmb_Te_Actl : 33|10@0+ (0.25,-128) [-128|127.75] "degC"  FCIM,HVAC_RCCM
 SG_ DynoMde_B_Cmd : 4|1@0+ (1,0) [0|1] "SED"  GENERIC
 SG_ AirAmb_P_Actl : 55|6@0+ (10,500) [500|1110] "mbar"  SOBDMD_AHCM_FOH

BO_ 951 TPM_Frame_MS1: 8 GWM
 SG_ TirePress_Info_MaxInd : 31|8@0+ (1,0) [0|255] "Unitless"  RTM
 SG_ TirePress_Info_Index : 23|8@0+ (1,0) [0|255] "Unitless"  RTM
 SG_ TirePress_Info_ID : 39|32@0+ (1,0) [0|4294967295] "Unitless"  RTM

BO_ 1068 Batt_Mgmt_Data_MS1: 8 GWM
 SG_ HvacAirFullOut_B_Rq_UB : 60|1@0+ (1,0) [0|1] "SED"  FCIM,HVAC_RCCM
 SG_ HvacAirFullOut_B_Rq : 61|1@0+ (1,0) [0|1] "SED"  FCIM,HVAC_RCCM
 SG_ HvacCmprLim_D_Stat_UB : 56|1@0+ (1,0) [0|1] "SED"  HVAC_RCCM,FCIM
 SG_ HvacCmprLim_D_Stat : 59|3@0+ (1,0) [0|7] "SED"  HVAC_RCCM,FCIM
 SG_ HvacAirFlw_B_RqBatt_UB : 62|1@0+ (1,0) [0|1] "SED"  FCIM,HVAC_RCCM
 SG_ HvacAirFlw_B_RqBatt : 63|1@0+ (1,0) [0|1] "SED"  FCIM,HVAC_RCCM
 SG_ HvacRec_D_RqMxBatt_UB : 21|1@0+ (1,0) [0|1] "SED"  FCIM,HVAC_RCCM
 SG_ HvacRec_D_RqMxBatt : 20|4@0+ (1,0) [0|15] "SED"  FCIM,HVAC_RCCM
 SG_ Batt_Lo_SoC_B_UB : 22|1@0+ (1,0) [0|1] "SED"  FCIM,HVAC_RCCM,TRM,SCMF
 SG_ Batt_Lo_SoC_B : 23|1@0+ (1,0) [0|1] "SED"  FCIM,HVAC_RCCM,TRM,SCMF
 SG_ Batt_Crit_SoC_B_UB : 14|1@0+ (1,0) [0|1] "SED"  FCIM,HVAC_RCCM,TRM,SCMF
 SG_ Batt_Crit_SoC_B : 15|1@0+ (1,0) [0|1] "SED"  FCIM,HVAC_RCCM,TRM,SCMF
 SG_ Shed_T_Eng_Off_B_UB : 12|1@0+ (1,0) [0|1] "SED"  FCIM,HVAC_RCCM,RHVAC,SCMF,TRM
 SG_ Shed_T_Eng_Off_B : 13|1@0+ (1,0) [0|1] "SED"  FCIM,HVAC_RCCM,RHVAC,TRM,SCMF
 SG_ Shed_Level_Req_UB : 8|1@0+ (1,0) [0|1] "SED"  FCIM,HVAC_RCCM,RHVAC,DDM,PDM,TRM
 SG_ Shed_Level_Req : 11|3@0+ (1,0) [0|7] "SED"  FCIM,HVAC_RCCM,RHVAC,DDM,PDM,TRM
 SG_ Shed_Feature_Group_ID_UB : 2|1@0+ (1,0) [0|1] "SED"  FCIM,HVAC_RCCM,RHVAC,TRM
 SG_ Shed_Feature_Group_ID : 7|5@0+ (1,0) [0|31] "SED"  FCIM,HVAC_RCCM,RHVAC,TRM
 SG_ Shed_Drain_Eng_Off_B_UB : 0|1@0+ (1,0) [0|1] "SED"  FCIM,HVAC_RCCM,RHVAC,TRM,SCMF
 SG_ Shed_Drain_Eng_Off_B : 1|1@0+ (1,0) [0|1] "SED"  FCIM,HVAC_RCCM,RHVAC,TRM,SCMF
 SG_ HvacAir_Flw_EstBatt_UB : 16|1@0+ (1,0) [0|1] "SED"  FCIM,HVAC_RCCM
 SG_ HvacAir_Flw_EstBatt : 31|8@0+ (0.5,0) [0|127] "liter/second"  FCIM,HVAC_RCCM
 SG_ AirCondRec_B_Rq_UB : 44|1@0+ (1,0) [0|1] "SED"  FCIM,HVAC_RCCM
 SG_ AirCondFluidHi_P_Actl_UB : 45|1@0+ (1,0) [0|1] "SED"  FCIM,HVAC_RCCM
 SG_ AirCondClutch_B_Stats_UB : 43|1@0+ (1,0) [0|1] "SED"  FCIM,HVAC_RCCM
 SG_ AirCondRec_B_Rq : 47|1@0+ (1,0) [0|1] "SED"  FCIM,HVAC_RCCM
 SG_ AirCondFluidHi_P_Actl : 39|8@0+ (0.125,0) [0|31.625] "bar"  FCIM,HVAC_RCCM
 SG_ AirCondClutch_B_Stats : 46|1@0+ (1,0) [0|1] "SED"  FCIM,HVAC_RCCM

BO_ 963 BCM_Lamp_Stat_MS1: 8 GWM
 SG_ Illuminated_Entry_Stat : 63|2@0+ (1,0) [0|3] "SED"  BCMB_ABM,BCMB_ALCM
 SG_ Dr_Courtesy_Light_Stat : 49|2@0+ (1,0) [0|3] "SED"  BCMB_ABM,BCMB_ALCM
 SG_ ImpactEvntFdbck_D_Stat : 53|2@0+ (1,0) [0|3] "SED"  GENERIC
 SG_ DrTgateLck_D_Stat : 61|2@0+ (1,0) [0|3] "SED"  GENERIC
 SG_ PudLampPsngr_D_Rq : 57|2@0+ (1,0) [0|3] "SED"  DSM,PDM,RBM
 SG_ HeadLampLoOut_B_Stat : 32|1@0+ (1,0) [0|1] "SED"  GENERIC
 SG_ CrnrLghtRight_Pc_Rq : 47|7@0+ (1,0) [0|100] "percent"  GENERIC
 SG_ CrnrLghtLeft_Pc_Rq : 39|7@0+ (1,0) [0|100] "percent"  GENERIC
 SG_ HeadLghtHiFdbck_D_Stat : 55|2@0+ (1,0) [0|3] "SED"  GENERIC
 SG_ PrkLightChime_B_Rq : 25|1@0+ (1,0) [0|1] "SED"  GENERIC
 SG_ TrnNotInPrkChime_B_Rq : 24|1@0+ (1,0) [0|1] "SED"  GENERIC
 SG_ HomeSafeLtChime_B_Rq : 28|1@0+ (1,0) [0|1] "SED"  GENERIC
 SG_ StopLghtOn_B_Stat : 8|1@0+ (1,0) [0|1] "SED"  RSM,BCMB_ALCM,BCMB_ABM,TRM
 SG_ RvrseLghtOn_B_Stat : 9|1@0+ (1,0) [0|1] "SED"  TRM
 SG_ PrkLght_D_Stat : 13|2@0+ (1,0) [0|3] "SED"  TRM
 SG_ HeadLghtSwtch_D_Stat : 15|2@0+ (1,0) [0|3] "SED"  GENERIC
 SG_ KeyInIgnWarn_B_Cmd : 27|1@0+ (1,0) [0|1] "SED"  GENERIC
 SG_ HeadLampLoFrOn_B_Stat : 2|1@0+ (1,0) [0|1] "SED"  GENERIC
 SG_ HeadLampLoFlOn_B_Stat : 3|1@0+ (1,0) [0|1] "SED"  GENERIC
 SG_ Headlamp_On_Wrning_Cmd : 29|1@0+ (1,0) [0|1] "SED"  GENERIC
 SG_ HeadLampLoActv_B_Stat : 4|1@0+ (1,0) [0|1] "SED"  GENERIC
 SG_ HeadLghtHiOn_B_Stat : 1|1@0+ (1,0) [0|1] "SED"  GENERIC
 SG_ Park_Brake_Chime_Rqst : 26|1@0+ (1,0) [0|1] "SED"  GENERIC
 SG_ BrkWarnInd_B_Rq : 20|1@0+ (1,0) [0|1] "SED"  GENERIC
 SG_ Brk_Fluid_Lvl_Low : 31|2@0+ (1,0) [0|3] "SED"  GENERIC
 SG_ ReducedGuard_D_Stat : 19|2@0+ (1,0) [0|3] "SED"  GENERIC
 SG_ Courtesy_BSave_Stat : 7|2@0+ (1,0) [0|3] "SED"  GFM_FTRM,DSM,DCME,DCMF,DCMG,DCMH,BCMB_ALCM,SCMJ,BCMB_ABM,DDM,PDM
 SG_ DayRnngLampOn_B_Stat : 5|1@0+ (1,0) [0|1] "SED"  GENERIC
 SG_ PerimeterAlarmChimeRq : 0|1@0+ (1,0) [0|1] "SED"  GENERIC
 SG_ PudLampDrv_D_Rq : 59|2@0+ (1,0) [0|3] "SED"  DSM,DDM,RBM
 SG_ Courtesy_Delay_Status : 51|2@0+ (1,0) [0|3] "SED"  BCMB_ABM,BCMB_ALCM
 SG_ Perimeter_Alarm_Status : 17|2@0+ (1,0) [0|3] "SED"  RSM,DCME,DCMF,DCMG,DCMH,TRM
 SG_ WndwGlbl_D_Cmd : 23|3@0+ (1,0) [0|7] "SED"  BCMB_ABM,BCMB_ALCM,DDM,PDM
 SG_ PudLamp_D_Rq : 11|2@0+ (1,0) [0|3] "SED"  DSM,RBM,DDM,PDM

BO_ 964 BodyInfo_MS1: 8 GWM
 SG_ FohEng_D_Rq_UB : 60|1@0+ (1,0) [0|1] "SED"  SOBDMD_AHCM_FOH
 SG_ FohEng_D_Rq : 62|2@0+ (1,0) [0|3] "SED"  SOBDMD_AHCM_FOH
 SG_ EcoMode_B_Stat_UB : 56|1@0+ (1,0) [0|1] "SED"  FCIM,GENERIC
 SG_ Cta_D_Rq_UB : 57|1@0+ (1,0) [0|1] "SED"  SODR,SODL
 SG_ Cta_D_Rq : 59|2@0+ (1,0) [0|3] "SED"  SODR,SODL
 SG_ GearRvrse_D_Actl_UB : 48|1@0+ (1,0) [0|1] "SED"  HVAC_RCCM,SODR,SODL,PDM,DDM
 SG_ GearRvrse_D_Actl : 51|3@0+ (1,0) [0|7] "SED"  HVAC_RCCM,SODR,SODL,PDM,DDM
 SG_ TurnLghtSwtch_D_Stat_UB : 52|1@0+ (1,0) [0|1] "SED"  SODR,SODL
 SG_ TurnLghtSwtch_D_Stat : 54|2@0+ (1,0) [0|3] "SED"  SODR,SODL
 SG_ Power_Liftgate_Mode_Cmd_UB : 6|1@0+ (1,0) [0|1] "SED"  RGTM
 SG_ Power_Liftgate_Mode_Cmd : 7|1@0+ (1,0) [0|1] "SED"  RGTM
 SG_ EcoMode_B_Stat : 20|1@0+ (1,0) [0|1] "SED"  FCIM,GENERIC
 SG_ MetricActvTe_B_Actl_UB : 2|1@0+ (1,0) [0|1] "SED"  FCIM,HVAC_RCCM
 SG_ MetricActvTe_B_Actl : 3|1@0+ (1,0) [0|1] "SED"  FCIM,HVAC_RCCM
 SG_ EngClntTe_D_Qf : 22|2@0+ (1,0) [0|3] "SED"  FCIM,HVAC_RCCM
 SG_ Sod_D_Rq : 1|2@0+ (1,0) [0|3] "SED"  SODR,SODL
 SG_ MetricActv_B_Actl : 5|1@0+ (1,0) [0|1] "SED"  FCIM,HVAC_RCCM
 SG_ EngClnt_Te_Actl : 15|8@0+ (1,-60) [-60|195] "degC"  FCIM,HVAC_RCCM,SOBDMD_AHCM_FOH
 SG_ MetricActv_B_Actl_UB : 4|1@0+ (1,0) [0|1] "SED"  FCIM,HVAC_RCCM
 SG_ EngClnt_Te_Actl_UB : 23|1@0+ (1,0) [0|1] "SED"  FCIM,HVAC_RCCM,SOBDMD_AHCM_FOH
 SG_ OCSSensrDataUpperLim_UB : 28|1@0+ (1,0) [0|1] "SED"  FCIM,HVAC_RCCM,SCMG,SCMH
 SG_ OCSSensrDataUpperLim : 47|8@0+ (1,0) [0|254] "SED"  FCIM,HVAC_RCCM,SCMG,SCMH
 SG_ OCSSensrDataLowerLim_UB : 29|1@0+ (1,0) [0|1] "SED"  FCIM,HVAC_RCCM,SCMG,SCMH
 SG_ PrkAid_D_Falt : 18|3@0+ (1,0) [0|7] "SED"  GENERIC
 SG_ OCSSensrDataLowerLim : 39|8@0+ (1,0) [0|254] "SED"  FCIM,HVAC_RCCM,SCMG,SCMH
 SG_ PrkAid_D_Falt_UB : 63|1@0+ (1,0) [0|1] "SED"  GENERIC
 SG_ WiprFront_D_Stat_UB : 55|1@0+ (1,0) [0|1] "SED"  FCIM,SODR,SODL,HVAC_RCCM
 SG_ WiprFront_D_Stat : 27|4@0+ (1,0) [0|15] "SED"  FCIM,SODR,SODL,HVAC_RCCM
 SG_ CamraDefog_B_Req_UB : 30|1@0+ (1,0) [0|1] "SED"  FCIM,HVAC_RCCM
 SG_ Sod_D_Rq_UB : 19|1@0+ (1,0) [0|1] "SED"  SODR,SODL
 SG_ CamraDefog_B_Req : 31|1@0+ (1,0) [0|1] "SED"  FCIM,HVAC_RCCM

BO_ 1843 TesterPhysicalReqHVAC_RCCM: 8 TSTR
 SG_ TesterPhysicalReqHVAC_RCCM : 7|64@0+ (1,0) [0|1.84467E+019] "unitless"  HVAC_RCCM

BO_ 1851 TesterPhysicalResHVAC_RCCM: 8 HVAC_RCCM
 SG_ TesterPhysicalResHVAC_RCCM : 7|64@0+ (1,0) [0|1.84467E+019] "unitless"  TSTR

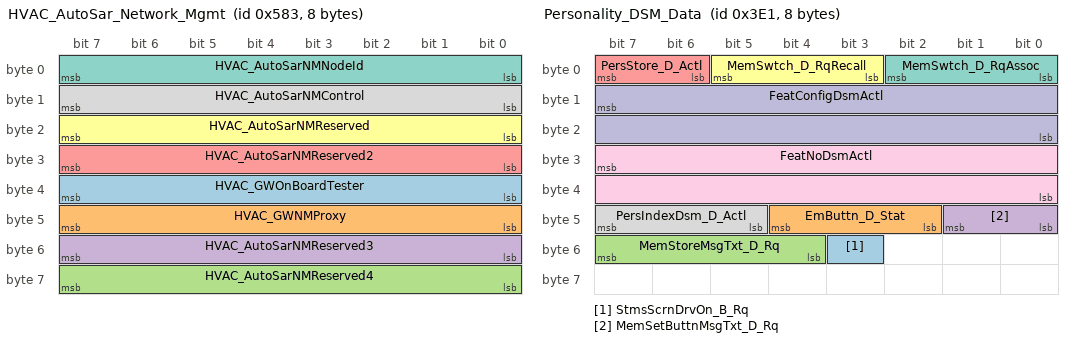
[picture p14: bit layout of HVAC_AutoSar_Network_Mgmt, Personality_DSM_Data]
BO_ 1411 HVAC_AutoSar_Network_Mgmt: 8 HVAC_RCCM
 SG_ HVAC_GWOnBoardTester : 39|8@0+ (1,0) [0|255] "unitless"  GWM
 SG_ HVAC_GWNMProxy : 47|8@0+ (1,0) [0|255] "unitless"  GWM
 SG_ HVAC_AutoSarNMReserved4 : 63|8@0+ (1,0) [0|255] "unitless"  GWM
 SG_ HVAC_AutoSarNMReserved3 : 55|8@0+ (1,0) [0|255] "unitless"  GWM
 SG_ HVAC_AutoSarNMReserved2 : 31|8@0+ (1,0) [0|255] "unitless"  GWM
 SG_ HVAC_AutoSarNMReserved : 23|8@0+ (1,0) [0|255] "unitless"  GWM
 SG_ HVAC_AutoSarNMNodeId : 7|8@0+ (1,0) [0|255] "unitless"  GWM
 SG_ HVAC_AutoSarNMControl : 15|8@0+ (1,0) [0|255] "unitless"  GWM

BO_ 993 Personality_DSM_Data: 8 DSM
 SG_ StmsScrnDrvOn_B_Rq : 51|1@0+ (1,0) [0|1] "SED"  GWM
 SG_ EmButtn_D_Stat : 44|3@0+ (1,0) [0|7] "SED"  DDM,GWM
 SG_ MemStoreMsgTxt_D_Rq : 55|4@0+ (1,0) [0|15] "SED"  GWM
 SG_ MemSetButtnMsgTxt_D_Rq : 41|2@0+ (1,0) [0|3] "SED"  GWM
 SG_ PersStore_D_Actl : 7|2@0+ (1,0) [0|3] "SED"  GWM
 SG_ MemSwtch_D_RqRecall : 5|3@0+ (1,0) [0|7] "SED"  BCMB_CAPM,GWM
 SG_ MemSwtch_D_RqAssoc : 2|3@0+ (1,0) [0|7] "SED"  GWM
 SG_ PersIndexDsm_D_Actl : 47|3@0+ (1,0) [0|7] "SED"  GENERIC,GWM
 SG_ FeatNoDsmActl : 31|16@0+ (1,0) [0|65535] "Number"  GWM
 SG_ FeatConfigDsmActl : 15|16@0+ (1,0) [0|65535] "Undefined"  GWM

BO_ 1881 TesterPhysicalResRTM: 8 RTM
 SG_ TesterPhysicalResRTM : 7|64@0+ (1,0) [0|1.84467E+019] "unitless"  TSTR

BO_ 1873 TesterPhysicalReqRTM: 8 TSTR
 SG_ TesterPhysicalReqRTM : 7|64@0+ (1,0) [0|1.84467E+019] "unitless"  RTM

BO_TX_BU_ 710 : FCIM,HVAC_RCCM;
BO_TX_BU_ 556 : HVAC_RCCM,FCIM;
BO_TX_BU_ 1983 : BCMB_ALCM,BCMB_AUXM,BCMB_CAPM,BCMB_ABM;
BO_TX_BU_ 1091 : GWM,TRM;
CM_ SG_ 839 FohStop_B_Stat "Signal not transmitted on vehicles that do not have the Fuel operated heater feature.";
CM_ SG_ 839 FohMsgTxt_D_Rq "Signal not transmitted on vehicles that do not have the Fuel operated heater feature.";
CM_ SG_ 839 FohKeyOff_B_Rq "Signal not transmitted on vehicles that do not have the Fuel operated heater feature.";
CM_ SG_ 839 FohEnbl_B_Rq "Signal not transmitted on vehicles that do not have the Fuel operated heater feature.";
CM_ SG_ 839 FohTAllEnable_B_Stat "Signal not transmitted on vehicles that do not have the Fuel operated heater feature.";
CM_ SG_ 839 FohT2Mnte_T_Stat "Signal not transmitted on vehicles that do not have the Fuel operated heater feature.";
CM_ SG_ 839 FohT2Hr_T_Stat "Signal not transmitted on vehicles that do not have the Fuel operated heater feature.";
CM_ SG_ 839 FohT2Enable_B_Stat "Signal not transmitted on vehicles that do not have the Fuel operated heater feature.";
CM_ SG_ 839 FohT1Mnte_T_Stat "Signal not transmitted on vehicles that do not have the Fuel operated heater feature.";
CM_ SG_ 839 FohT1Hr_T_Stat "Signal not transmitted on vehicles that do not have the Fuel operated heater feature.";
CM_ SG_ 839 FohT1Enable_B_Stat "Signal not transmitted on vehicles that do not have the Fuel operated heater feature.";
CM_ SG_ 839 FohStrtMnte_T_Stat "Signal not transmitted on vehicles that do not have the Fuel operated heater feature.";
CM_ SG_ 839 FohStrtHr_T_Stat "Signal not transmitted on vehicles that do not have the Fuel operated heater feature.";
CM_ SG_ 839 FohStrtEnable_B_Stat "Signal not transmitted on vehicles that do not have the Fuel operated heater feature.";
CM_ SG_ 839 FohContOn_B_Stat "Signal not transmitted on vehicles that do not have the Fuel operated heater feature.";
CM_ SG_ 839 FohStrtDay_T_Stat "Signal not transmitted on vehicles that do not have the Fuel operated heater feature.";
CM_ SG_ 839 FohT2Wednesday_T_Stat "Signal not transmitted on vehicles that do not have the Fuel operated heater feature.";
CM_ SG_ 839 FohT2Tuesday_T_Stat "Signal not transmitted on vehicles that do not have the Fuel operated heater feature.";
CM_ SG_ 839 FohT2Thursday_T_Stat "Signal not transmitted on vehicles that do not have the Fuel operated heater feature.";
CM_ SG_ 839 FohT2Sunday_T_Stat "Signal not transmitted on vehicles that do not have the Fuel operated heater feature.";
CM_ SG_ 839 FohT2Saturday_T_Stat "Signal not transmitted on vehicles that do not have the Fuel operated heater feature.";
CM_ SG_ 839 FohT2Monday_T_Stat "Signal not transmitted on vehicles that do not have the Fuel operated heater feature.";
CM_ SG_ 839 FohT2Friday_T_Stat "Signal not transmitted on vehicles that do not have the Fuel operated heater feature.";
CM_ SG_ 839 FohT1Wednesday_T_Stat "Signal not transmitted on vehicles that do not have the Fuel operated heater feature.";
CM_ SG_ 839 FohT1Tuesday_T_Stat "Signal not transmitted on vehicles that do not have the Fuel operated heater feature.";
CM_ SG_ 839 FohT1Thursday_T_Stat "Signal not transmitted on vehicles that do not have the Fuel operated heater feature.";
CM_ SG_ 839 FohT1Sunday_T_Stat "Signal not transmitted on vehicles that do not have the Fuel operated heater feature.";
CM_ SG_ 839 FohT1Saturday_T_Stat "Signal not transmitted on vehicles that do not have the Fuel operated heater feature.";
CM_ SG_ 839 FohT1Monday_T_Stat "Signal not transmitted on vehicles that do not have the Fuel operated heater feature.";
CM_ SG_ 839 FohT1Friday_T_Stat "Signal not transmitted on vehicles that do not have the Fuel operated heater feature.";
CM_ SG_ 765 ClimtBlwrLim_B_Rq "NotSupported on FNV2, no transmitter";
CM_ SG_ 765 Bezel_Beeps_Rq "Vehicle Settings";
CM_ SG_ 765 Diagnostic_Operation_Rq "Object:BezelDiagnostics.MFD_Bezel_Diagnostic.St";
CM_ SG_ 765 Bezel_Diag_State_Rq "Object:BezelDiagnostics.MFD_Bezel_Diagnostic.Rq";
CM_ SG_ 765 Bezel_Diag_Module_Rq "Object:BezelDiagnostics.MFD_Bezel_Diagnostic.St";
CM_ SG_ 765 HMI_HMIMode_St "Object ACU System Master.HMIMode
OR
Object NAV System Master.HMIMode

Refer Method HMIAudioMode in the SPSS";
CM_ SG_ 765 Mc_VehUnitTempUsrSel_St "Object.VehicleSettings.Disp_Temperature.Rq";
CM_ BO_ 710 "TP message(Transport Protocol), Rx's HS3 APIM & MFD, transmitted immediately";
CM_ SG_ 556 EFP_Bezel_Diag_St "Object:BezelDiagnostics.EFP_Bezel_Diag.St";
CM_ SG_ 556 Bezel_Beep_St "Object:VehicleSettings.Bezel_Beeps.St.Status";
CM_ SG_ 556 Bezel_Beeps_Supported "Object: Vehicle Settings. Bezel_Beeps_Supported.St";
CM_ SG_ 359 TrnAin_Tq_Actl "Signal not transmitted on HEV variances.";
CM_ SG_ 359 TrnAinTq_D_Qf "Signal not transmitted on HEV variances.";
CM_ SG_ 359 PlgActvArb_B_Actl "Only supported on PHEV programs.  PlgActvArb_B_Actl HPCM will Tx on Powersplit PHEV’s,  On MHT PHEVs the PCM_HEV will Tx and HPCM will Rx. 
";
CM_ SG_ 836 FohFalt_D_Stat "Signal not transmitted on vehicles that do not have the Fuel operated heater feature.";
CM_ SG_ 836 FohEnbl_B_RqDrv "Signal not transmitted on vehicles that do not have the Fuel operated heater feature.";
CM_ SG_ 836 FohRqRun_B_Rq "Signal not transmitted on vehicles that do not have the Fuel operated heater feature.";
CM_ SG_ 836 HvacPrecondMode_D_Rq "Signal not transmitted on vehicles that do not have the Fuel operated heater feature.";
CM_ SG_ 836 HvacPrecondBlwr_D_Rq "Signal not transmitted on vehicles that do not have the Fuel operated heater feature.";
CM_ SG_ 836 Foh_D_Stat "Signal not transmitted on vehicles that do not have the Fuel operated heater feature.";
CM_ SG_ 836 FuelFlw_Vl_ActlFoh "Signal not transmitted on vehicles that do not have the Fuel operated heater feature.";
CM_ SG_ 836 EngClnt_Te_ActlFoh "Signal not transmitted on vehicles that do not have the Fuel operated heater feature.";
CM_ SG_ 1091 PoliceAux4Lamp_B_Rq2 "Signal not transmitted on programs that do not have AWD.";
CM_ SG_ 1091 PoliceAux3Lamp_B_Rq2 "Signal not transmitted on programs that do not have AWD.";
CM_ SG_ 1091 PoliceAux2Lamp_B_Rq2 "Signal not transmitted on programs that do not have AWD.";
CM_ SG_ 1091 PoliceAux1Lamp_B_Rq2 "Signal not transmitted on programs that do not have AWD.";
CM_ SG_ 376 EngAout_Aa_Actl "Signal not transmitted on HEV variants.";
CM_ SG_ 1068 AirCondRec_B_Rq "Signal not transmitted on diesel variants.";
CM_ SG_ 1068 AirCondClutch_B_Stats "Signal not transmitted on diesel variants.";
CM_ SG_ 964 FohEng_D_Rq "Signal not transmitted on vehicles that do not have the fuel operated heater feature.";
CM_ SG_ 964 GearRvrse_D_Actl "Do not implement GearRvrse_D_Actl  until eTracker 8804151 is approved, 11/24/09";
CM_ SG_ 964 MetricActv_B_Actl "0 =Inactive(English), 1=Active(Metric)";
BA_DEF_ BO_  "FrameRouting" STRING ;
BA_DEF_ BO_  "FrameGatewayNetwork" STRING ;
BA_DEF_ BO_  "NetworkInitialization" ENUM  "No","Yes";
BA_DEF_ BO_  "FrameGatewayId" HEX 0 1407;
BA_DEF_ BO_  "EventRateOfChange" INT 10 10000;
BA_DEF_ BO_  "GenMsgStartDelayTime" INT 0 10000;
BA_DEF_ BO_  "GenMsgNrOfRepetition" INT 0 100;
BA_DEF_ BO_  "GenMsgDelayTime" INT 0 1000;
BA_DEF_ BO_  "GenMsgCycleTime" INT 0 100000;
BA_DEF_ BO_  "GenMsgSendType" ENUM  "FixedPeriodic","Event","EnabledPeriodic","NotUsed","NotUsed","EventPeriodic","NotUsed","NotUsed","NoMsgSendType";
BA_DEF_ SG_  "U_CD764_MY2022_Tx" ENUM  "No","Yes";
BA_DEF_ SG_  "U_U55X_MY2022_Tx" ENUM  "No","Yes";
BA_DEF_ SG_  "U_CD542_MY2021_Tx" ENUM  "No","Yes";
BA_DEF_ SG_  "ECGUsedTxSignal" ENUM  "No","Yes";
BA_DEF_ SG_  "U_T6_MCA_MY2020_Tx" ENUM  "No","Yes";
BA_DEF_ SG_  "U_P702_MY2021_Tx" ENUM  "No","Yes";
BA_DEF_ SG_  "U_CX727_MY2021_Tx" ENUM  "No","Yes";
BA_DEF_ SG_  "U_CD764_MY2022_Rx" ENUM  "No","Yes";
BA_DEF_ SG_  "U_U55X_MY2022_Rx" ENUM  "No","Yes";
BA_DEF_ SG_  "U_CD542_MY2021_Rx" ENUM  "No","Yes";
BA_DEF_ SG_  "ECGUsedRxSignal" ENUM  "No","Yes";
BA_DEF_ SG_  "U_T6_MCA_MY2020_Rx" ENUM  "No","Yes";
BA_DEF_ SG_  "U_P702_MY2021_Rx" ENUM  "No","Yes";
BA_DEF_ SG_  "U_CX727_MY2021_Rx" ENUM  "No","Yes";
BA_DEF_ SG_  "GenSigStartValue" HEX 0 268435455;
BA_DEF_ SG_  "MetaData" ENUM  "No","Yes";
BA_DEF_ SG_  "ContentDependant" ENUM  "No","Yes";
BA_DEF_ SG_  "GenSigStartValueInteger" INT 0 1000000000;
BA_DEF_ SG_  "UsedOnPgmDBC" ENUM  "No","Yes";
BA_DEF_ SG_  "WakeupSignal" ENUM  "No","Yes";
BA_DEF_ SG_  "GenSigInactiveValue" INT 0 100000;
BA_DEF_ SG_  "GenSigSendType" ENUM  "Cyclic","OnWrite","vector_leerstring","OnChange","vector_leerstring","IfActive","vector_leerstring","NoSigSendType";
BA_DEF_ BO_  "OvtpPushApplication" ENUM  "FALSE","TRUE";
BA_DEF_ BO_  "SCP_FreshnessValueLength" INT 0 512;
BA_DEF_ BO_  "SCP_FreshnessValueTxLength" INT 0 512;
BA_DEF_ BO_  "SCP_AuthInfoTxLength" INT 0 512;
BA_DEF_ BO_  "GenMsgRoutingTimeoutTime" INT 0 5000;
BA_DEF_ BO_  "MessageGateway" ENUM  "No","Yes";
BA_DEF_ BO_  "NmAsrMessage" ENUM  "No","Yes";
BA_DEF_ BO_  "DiagState" ENUM  "No","Yes";
BA_DEF_ BO_  "TpTxIndex" INT 0 536870911;
BA_DEF_ BO_  "DiagRequest" ENUM  "No","Yes";
BA_DEF_ BO_  "DiagResponse" ENUM  "No","Yes";
BA_DEF_ BO_  "NmMessage" ENUM  "No","Yes";
BA_DEF_ BO_  "GenMsgILSupport" ENUM  "No","Yes";
BA_DEF_DEF_  "FrameRouting" "";
BA_DEF_DEF_  "FrameGatewayNetwork" "NONE";
BA_DEF_DEF_  "NetworkInitialization" "Yes";
BA_DEF_DEF_  "FrameGatewayId" 0;
BA_DEF_DEF_  "EventRateOfChange" 10000;
BA_DEF_DEF_  "GenMsgStartDelayTime" 0;
BA_DEF_DEF_  "GenMsgNrOfRepetition" 1;
BA_DEF_DEF_  "GenMsgDelayTime" 20;
BA_DEF_DEF_  "GenMsgCycleTime" 0;
BA_DEF_DEF_  "GenMsgSendType" "NoMsgSendType";
BA_DEF_DEF_  "U_CD764_MY2022_Tx" "No";
BA_DEF_DEF_  "U_U55X_MY2022_Tx" "No";
BA_DEF_DEF_  "U_CD542_MY2021_Tx" "No";
BA_DEF_DEF_  "ECGUsedTxSignal" "No";
BA_DEF_DEF_  "U_T6_MCA_MY2020_Tx" "No";
BA_DEF_DEF_  "U_P702_MY2021_Tx" "No";
BA_DEF_DEF_  "U_CX727_MY2021_Tx" "No";
BA_DEF_DEF_  "U_CD764_MY2022_Rx" "No";
BA_DEF_DEF_  "U_U55X_MY2022_Rx" "No";
BA_DEF_DEF_  "U_CD542_MY2021_Rx" "No";
BA_DEF_DEF_  "ECGUsedRxSignal" "No";
BA_DEF_DEF_  "U_T6_MCA_MY2020_Rx" "No";
BA_DEF_DEF_  "U_P702_MY2021_Rx" "No";
BA_DEF_DEF_  "U_CX727_MY2021_Rx" "No";
BA_DEF_DEF_  "GenSigStartValue" 0;
BA_DEF_DEF_  "MetaData" "No";
BA_DEF_DEF_  "ContentDependant" "No";
BA_DEF_DEF_  "GenSigStartValueInteger" 0;
BA_DEF_DEF_  "UsedOnPgmDBC" "Yes";
BA_DEF_DEF_  "WakeupSignal" "No";
BA_DEF_DEF_  "GenSigInactiveValue" 0;
BA_DEF_DEF_  "GenSigSendType" "NoSigSendType";
BA_DEF_DEF_  "OvtpPushApplication" "FALSE";
BA_DEF_DEF_  "SCP_FreshnessValueLength" 64;
BA_DEF_DEF_  "SCP_FreshnessValueTxLength" 11;
BA_DEF_DEF_  "SCP_AuthInfoTxLength" 53;
BA_DEF_DEF_  "GenMsgRoutingTimeoutTime" 0;
BA_DEF_DEF_  "MessageGateway" "No";
BA_DEF_DEF_  "NmAsrMessage" "No";
BA_DEF_DEF_  "DiagState" "No";
BA_DEF_DEF_  "TpTxIndex" 0;
BA_DEF_DEF_  "DiagRequest" "No";
BA_DEF_DEF_  "DiagResponse" "No";
BA_DEF_DEF_  "NmMessage" "No";
BA_DEF_DEF_  "GenMsgILSupport" "Yes";
BA_ "GenMsgCycleTime" BO_ 839 100;
BA_ "GenMsgSendType" BO_ 839 0;
BA_ "FrameRouting" BO_ 838 "HS3_CAN,0x346;";
BA_ "FrameGatewayNetwork" BO_ 838 "HS3_CAN";
BA_ "FrameGatewayId" BO_ 838 838;
BA_ "GenMsgCycleTime" BO_ 850 500;
BA_ "GenMsgSendType" BO_ 850 0;
BA_ "GenMsgCycleTime" BO_ 849 500;
BA_ "GenMsgSendType" BO_ 849 0;
BA_ "FrameRouting" BO_ 846 "HS3_CAN,0x34E;";
BA_ "FrameGatewayNetwork" BO_ 846 "HS3_CAN";
BA_ "FrameGatewayId" BO_ 846 846;
BA_ "GenMsgCycleTime" BO_ 868 1000;
BA_ "GenMsgSendType" BO_ 868 5;
BA_ "NetworkInitialization" BO_ 1962 0;
BA_ "GenMsgDelayTime" BO_ 1962 0;
BA_ "GenMsgSendType" BO_ 1962 1;
BA_ "DiagResponse" BO_ 1962 1;
BA_ "GenMsgILSupport" BO_ 1962 0;
BA_ "NetworkInitialization" BO_ 1410 0;
BA_ "GenMsgCycleTime" BO_ 1410 1000;
BA_ "GenMsgSendType" BO_ 1410 0;
BA_ "NmAsrMessage" BO_ 1410 1;
BA_ "GenMsgILSupport" BO_ 1410 0;
BA_ "NetworkInitialization" BO_ 1497 0;
BA_ "GenMsgCycleTime" BO_ 1497 1000;
BA_ "GenMsgSendType" BO_ 1497 0;
BA_ "NmAsrMessage" BO_ 1497 1;
BA_ "GenMsgILSupport" BO_ 1497 0;
BA_ "NetworkInitialization" BO_ 1805 0;
BA_ "GenMsgDelayTime" BO_ 1805 0;
BA_ "GenMsgSendType" BO_ 1805 1;
BA_ "DiagResponse" BO_ 1805 1;
BA_ "GenMsgILSupport" BO_ 1805 0;
BA_ "GenMsgCycleTime" BO_ 845 1000;
BA_ "GenMsgSendType" BO_ 845 5;
BA_ "GenMsgCycleTime" BO_ 844 1000;
BA_ "GenMsgSendType" BO_ 844 5;
BA_ "GenMsgCycleTime" BO_ 843 1000;
BA_ "GenMsgSendType" BO_ 843 5;
BA_ "GenMsgCycleTime" BO_ 842 1000;
BA_ "GenMsgSendType" BO_ 842 5;
BA_ "NetworkInitialization" BO_ 1994 0;
BA_ "GenMsgDelayTime" BO_ 1994 0;
BA_ "GenMsgSendType" BO_ 1994 1;
BA_ "DiagResponse" BO_ 1994 1;
BA_ "GenMsgILSupport" BO_ 1994 0;
BA_ "NetworkInitialization" BO_ 1986 0;
BA_ "GenMsgDelayTime" BO_ 1986 0;
BA_ "GenMsgSendType" BO_ 1986 1;
BA_ "DiagRequest" BO_ 1986 1;
BA_ "GenMsgILSupport" BO_ 1986 0;
BA_ "GenMsgCycleTime" BO_ 958 100;
BA_ "GenMsgSendType" BO_ 958 5;
BA_ "GenMsgCycleTime" BO_ 827 1000;
BA_ "GenMsgSendType" BO_ 827 5;
BA_ "GenMsgRoutingTimeoutTime" BO_ 827 180;
BA_ "MessageGateway" BO_ 827 1;
BA_ "GenMsgCycleTime" BO_ 902 1000;
BA_ "GenMsgSendType" BO_ 902 5;
BA_ "GenMsgCycleTime" BO_ 765 1000;
BA_ "GenMsgSendType" BO_ 765 5;
BA_ "TpTxIndex" BO_ 710 26;
BA_ "GenMsgCycleTime" BO_ 556 1000;
BA_ "GenMsgSendType" BO_ 556 5;
BA_ "NetworkInitialization" BO_ 1815 0;
BA_ "GenMsgDelayTime" BO_ 1815 0;
BA_ "GenMsgSendType" BO_ 1815 1;
BA_ "DiagRequest" BO_ 1815 1;
BA_ "GenMsgILSupport" BO_ 1815 0;
BA_ "NetworkInitialization" BO_ 1433 0;
BA_ "GenMsgCycleTime" BO_ 1433 1000;
BA_ "GenMsgSendType" BO_ 1433 0;
BA_ "NmAsrMessage" BO_ 1433 1;
BA_ "GenMsgILSupport" BO_ 1433 0;
BA_ "NetworkInitialization" BO_ 1983 0;
BA_ "GenMsgDelayTime" BO_ 1983 0;
BA_ "GenMsgSendType" BO_ 1983 1;
BA_ "DiagResponse" BO_ 1983 1;
BA_ "GenMsgILSupport" BO_ 1983 0;
BA_ "NetworkInitialization" BO_ 1975 0;
BA_ "GenMsgDelayTime" BO_ 1975 0;
BA_ "GenMsgSendType" BO_ 1975 1;
BA_ "DiagRequest" BO_ 1975 1;
BA_ "GenMsgILSupport" BO_ 1975 0;
BA_ "GenMsgCycleTime" BO_ 359 1000;
BA_ "GenMsgSendType" BO_ 359 5;
BA_ "GenMsgRoutingTimeoutTime" BO_ 359 30;
BA_ "MessageGateway" BO_ 359 1;
BA_ "GenMsgCycleTime" BO_ 131 100;
BA_ "GenMsgSendType" BO_ 131 0;
BA_ "GenMsgCycleTime" BO_ 990 1000;
BA_ "GenMsgSendType" BO_ 990 5;
BA_ "GenMsgCycleTime" BO_ 1246 100;
BA_ "GenMsgSendType" BO_ 1246 5;
BA_ "GenMsgSendType" BO_ 1363 1;
BA_ "NmMessage" BO_ 1363 1;
BA_ "GenMsgILSupport" BO_ 1363 0;
BA_ "NetworkInitialization" BO_ 1899 0;
BA_ "GenMsgDelayTime" BO_ 1899 0;
BA_ "GenMsgSendType" BO_ 1899 1;
BA_ "DiagResponse" BO_ 1899 1;
BA_ "GenMsgILSupport" BO_ 1899 0;
BA_ "FrameRouting" BO_ 1003 "HS1_CAN,0x3EB;";
BA_ "FrameGatewayNetwork" BO_ 1003 "HS1_CAN";
BA_ "FrameGatewayId" BO_ 1003 1003;
BA_ "NetworkInitialization" BO_ 1945 0;
BA_ "GenMsgDelayTime" BO_ 1945 0;
BA_ "GenMsgSendType" BO_ 1945 1;
BA_ "DiagResponse" BO_ 1945 1;
BA_ "GenMsgILSupport" BO_ 1945 0;
BA_ "GenMsgCycleTime" BO_ 836 1000;
BA_ "GenMsgSendType" BO_ 836 0;
BA_ "GenMsgStartDelayTime" BO_ 819 100;
BA_ "GenMsgCycleTime" BO_ 819 100;
BA_ "GenMsgSendType" BO_ 819 5;
BA_ "GenMsgStartDelayTime" BO_ 818 100;
BA_ "GenMsgCycleTime" BO_ 818 100;
BA_ "GenMsgSendType" BO_ 818 5;
BA_ "FrameRouting" BO_ 817 "HS1_CAN,0x331;";
BA_ "FrameGatewayNetwork" BO_ 817 "HS1_CAN";
BA_ "FrameGatewayId" BO_ 817 817;
BA_ "GenMsgCycleTime" BO_ 1091 1000;
BA_ "GenMsgSendType" BO_ 1091 5;
BA_ "NetworkInitialization" BO_ 1865 0;
BA_ "GenMsgDelayTime" BO_ 1865 0;
BA_ "GenMsgSendType" BO_ 1865 1;
BA_ "DiagResponse" BO_ 1865 1;
BA_ "GenMsgILSupport" BO_ 1865 0;
BA_ "NetworkInitialization" BO_ 1857 0;
BA_ "GenMsgDelayTime" BO_ 1857 0;
BA_ "GenMsgSendType" BO_ 1857 1;
BA_ "DiagRequest" BO_ 1857 1;
BA_ "GenMsgILSupport" BO_ 1857 0;
BA_ "NetworkInitialization" BO_ 1819 0;
BA_ "GenMsgDelayTime" BO_ 1819 0;
BA_ "GenMsgSendType" BO_ 1819 1;
BA_ "DiagResponse" BO_ 1819 1;
BA_ "GenMsgILSupport" BO_ 1819 0;
BA_ "NetworkInitialization" BO_ 1818 0;
BA_ "GenMsgDelayTime" BO_ 1818 0;
BA_ "GenMsgSendType" BO_ 1818 1;
BA_ "DiagResponse" BO_ 1818 1;
BA_ "GenMsgILSupport" BO_ 1818 0;
BA_ "NetworkInitialization" BO_ 1811 0;
BA_ "GenMsgDelayTime" BO_ 1811 0;
BA_ "GenMsgSendType" BO_ 1811 1;
BA_ "DiagRequest" BO_ 1811 1;
BA_ "GenMsgILSupport" BO_ 1811 0;
BA_ "NetworkInitialization" BO_ 1810 0;
BA_ "GenMsgDelayTime" BO_ 1810 0;
BA_ "GenMsgSendType" BO_ 1810 1;
BA_ "DiagRequest" BO_ 1810 1;
BA_ "GenMsgILSupport" BO_ 1810 0;
BA_ "GenMsgSendType" BO_ 1310 1;
BA_ "NmMessage" BO_ 1310 1;
BA_ "GenMsgILSupport" BO_ 1310 0;
BA_ "GenMsgCycleTime" BO_ 1066 50;
BA_ "GenMsgSendType" BO_ 1066 0;
BA_ "FrameRouting" BO_ 994 "HS3_CAN,0x3E2;";
BA_ "FrameGatewayNetwork" BO_ 994 "HS3_CAN";
BA_ "FrameGatewayId" BO_ 994 994;
BA_ "FrameRouting" BO_ 376 "FD1_CAN,0x178;";
BA_ "FrameGatewayNetwork" BO_ 376 "FD1_CAN";
BA_ "FrameGatewayId" BO_ 376 376;
BA_ "FrameRouting" BO_ 951 "HS1_CAN,0x3B7;";
BA_ "FrameGatewayNetwork" BO_ 951 "HS1_CAN";
BA_ "FrameGatewayId" BO_ 951 951;
BA_ "GenMsgCycleTime" BO_ 1068 50;
BA_ "GenMsgSendType" BO_ 1068 0;
BA_ "FrameRouting" BO_ 963 "HS1_CAN,0x3C3;";
BA_ "FrameGatewayNetwork" BO_ 963 "HS1_CAN";
BA_ "FrameGatewayId" BO_ 963 963;
BA_ "GenMsgCycleTime" BO_ 964 200;
BA_ "GenMsgSendType" BO_ 964 5;
BA_ "NetworkInitialization" BO_ 1843 0;
BA_ "GenMsgDelayTime" BO_ 1843 0;
BA_ "GenMsgSendType" BO_ 1843 1;
BA_ "DiagRequest" BO_ 1843 1;
BA_ "GenMsgILSupport" BO_ 1843 0;
BA_ "NetworkInitialization" BO_ 1851 0;
BA_ "GenMsgDelayTime" BO_ 1851 0;
BA_ "GenMsgSendType" BO_ 1851 1;
BA_ "DiagResponse" BO_ 1851 1;
BA_ "GenMsgILSupport" BO_ 1851 0;
BA_ "NetworkInitialization" BO_ 1411 0;
BA_ "GenMsgCycleTime" BO_ 1411 1000;
BA_ "GenMsgSendType" BO_ 1411 0;
BA_ "NmAsrMessage" BO_ 1411 1;
BA_ "GenMsgILSupport" BO_ 1411 0;
BA_ "GenMsgStartDelayTime" BO_ 993 100;
BA_ "GenMsgCycleTime" BO_ 993 1000;
BA_ "GenMsgSendType" BO_ 993 5;
BA_ "NetworkInitialization" BO_ 1881 0;
BA_ "GenMsgDelayTime" BO_ 1881 0;
BA_ "GenMsgSendType" BO_ 1881 1;
BA_ "DiagResponse" BO_ 1881 1;
BA_ "GenMsgILSupport" BO_ 1881 0;
BA_ "NetworkInitialization" BO_ 1873 0;
BA_ "GenMsgDelayTime" BO_ 1873 0;
BA_ "GenMsgSendType" BO_ 1873 1;
BA_ "DiagRequest" BO_ 1873 1;
BA_ "GenMsgILSupport" BO_ 1873 0;
BA_ "GenSigStartValue" SG_ 839 FohStop_B_Stat 3;
BA_ "ContentDependant" SG_ 839 FohStop_B_Stat 1;
BA_ "GenSigStartValueInteger" SG_ 839 FohStop_B_Stat 3;
BA_ "WakeupSignal" SG_ 839 FohStop_B_Stat 1;
BA_ "ContentDependant" SG_ 839 FohMsgTxt_D_Rq 1;
BA_ "ContentDependant" SG_ 839 FohKeyOff_B_Rq 1;
BA_ "WakeupSignal" SG_ 839 FohKeyOff_B_Rq 1;
BA_ "ContentDependant" SG_ 839 FohEnbl_B_Rq 1;
BA_ "WakeupSignal" SG_ 839 FohEnbl_B_Rq 1;
BA_ "GenSigStartValue" SG_ 839 FohTAllEnable_B_Stat 3;
BA_ "ContentDependant" SG_ 839 FohTAllEnable_B_Stat 1;
BA_ "GenSigStartValueInteger" SG_ 839 FohTAllEnable_B_Stat 3;
BA_ "ContentDependant" SG_ 839 FohT2Mnte_T_Stat 1;
BA_ "ContentDependant" SG_ 839 FohT2Hr_T_Stat 1;
BA_ "ContentDependant" SG_ 839 FohT2Enable_B_Stat 1;
BA_ "ContentDependant" SG_ 839 FohT1Mnte_T_Stat 1;
BA_ "ContentDependant" SG_ 839 FohT1Hr_T_Stat 1;
BA_ "ContentDependant" SG_ 839 FohT1Enable_B_Stat 1;
BA_ "ContentDependant" SG_ 839 FohStrtMnte_T_Stat 1;
BA_ "ContentDependant" SG_ 839 FohStrtHr_T_Stat 1;
BA_ "ContentDependant" SG_ 839 FohStrtEnable_B_Stat 1;
BA_ "GenSigStartValue" SG_ 839 FohContOn_B_Stat 3;
BA_ "ContentDependant" SG_ 839 FohContOn_B_Stat 1;
BA_ "GenSigStartValueInteger" SG_ 839 FohContOn_B_Stat 3;
BA_ "ContentDependant" SG_ 839 FohStrtDay_T_Stat 1;
BA_ "ContentDependant" SG_ 839 FohT2Wednesday_T_Stat 1;
BA_ "ContentDependant" SG_ 839 FohT2Tuesday_T_Stat 1;
BA_ "ContentDependant" SG_ 839 FohT2Thursday_T_Stat 1;
BA_ "ContentDependant" SG_ 839 FohT2Sunday_T_Stat 1;
BA_ "ContentDependant" SG_ 839 FohT2Saturday_T_Stat 1;
BA_ "ContentDependant" SG_ 839 FohT2Monday_T_Stat 1;
BA_ "ContentDependant" SG_ 839 FohT2Friday_T_Stat 1;
BA_ "ContentDependant" SG_ 839 FohT1Wednesday_T_Stat 1;
BA_ "ContentDependant" SG_ 839 FohT1Tuesday_T_Stat 1;
BA_ "ContentDependant" SG_ 839 FohT1Thursday_T_Stat 1;
BA_ "ContentDependant" SG_ 839 FohT1Sunday_T_Stat 1;
BA_ "ContentDependant" SG_ 839 FohT1Saturday_T_Stat 1;
BA_ "ContentDependant" SG_ 839 FohT1Monday_T_Stat 1;
BA_ "ContentDependant" SG_ 839 FohT1Friday_T_Stat 1;
BA_ "GenSigStartValue" SG_ 838 FohStop_B_Rq 3;
BA_ "GenSigStartValueInteger" SG_ 838 FohStop_B_Rq 3;
BA_ "GenSigStartValue" SG_ 838 FohTAllEnable_B_Rq 3;
BA_ "GenSigStartValueInteger" SG_ 838 FohTAllEnable_B_Rq 3;
BA_ "GenSigStartValue" SG_ 838 FohContOn_B_Rq 3;
BA_ "GenSigStartValueInteger" SG_ 838 FohContOn_B_Rq 3;
BA_ "U_CD764_MY2022_Tx" SG_ 850 SeatCshnPsgrRR_Pc_Actl 1;
BA_ "U_U55X_MY2022_Tx" SG_ 850 SeatCshnPsgrRR_Pc_Actl 1;
BA_ "U_P702_MY2021_Tx" SG_ 850 SeatCshnPsgrRR_Pc_Actl 1;
BA_ "GenSigStartValue" SG_ 850 SeatCshnPsgrRR_Pc_Actl 127;
BA_ "GenSigStartValueInteger" SG_ 850 SeatCshnPsgrRR_Pc_Actl 127;
BA_ "U_CD764_MY2022_Tx" SG_ 850 SeatCshnPsgrRL_Pc_Actl 1;
BA_ "U_U55X_MY2022_Tx" SG_ 850 SeatCshnPsgrRL_Pc_Actl 1;
BA_ "U_P702_MY2021_Tx" SG_ 850 SeatCshnPsgrRL_Pc_Actl 1;
BA_ "GenSigStartValue" SG_ 850 SeatCshnPsgrRL_Pc_Actl 127;
BA_ "GenSigStartValueInteger" SG_ 850 SeatCshnPsgrRL_Pc_Actl 127;
BA_ "U_CD764_MY2022_Tx" SG_ 850 SeatCshnPsgrFR_Pc_Actl 1;
BA_ "U_U55X_MY2022_Tx" SG_ 850 SeatCshnPsgrFR_Pc_Actl 1;
BA_ "U_P702_MY2021_Tx" SG_ 850 SeatCshnPsgrFR_Pc_Actl 1;
BA_ "GenSigStartValue" SG_ 850 SeatCshnPsgrFR_Pc_Actl 127;
BA_ "GenSigStartValueInteger" SG_ 850 SeatCshnPsgrFR_Pc_Actl 127;
BA_ "U_CD764_MY2022_Tx" SG_ 850 SeatCshnPsgrFL_Pc_Actl 1;
BA_ "U_U55X_MY2022_Tx" SG_ 850 SeatCshnPsgrFL_Pc_Actl 1;
BA_ "U_P702_MY2021_Tx" SG_ 850 SeatCshnPsgrFL_Pc_Actl 1;
BA_ "GenSigStartValue" SG_ 850 SeatCshnPsgrFL_Pc_Actl 127;
BA_ "GenSigStartValueInteger" SG_ 850 SeatCshnPsgrFL_Pc_Actl 127;
BA_ "U_CD764_MY2022_Tx" SG_ 850 SeatBlLoPsgr_Pc_Actl2 1;
BA_ "U_U55X_MY2022_Tx" SG_ 850 SeatBlLoPsgr_Pc_Actl2 1;
BA_ "U_P702_MY2021_Tx" SG_ 850 SeatBlLoPsgr_Pc_Actl2 1;
BA_ "GenSigStartValue" SG_ 850 SeatBlLoPsgr_Pc_Actl2 127;
BA_ "GenSigStartValueInteger" SG_ 850 SeatBlLoPsgr_Pc_Actl2 127;
BA_ "U_CD764_MY2022_Tx" SG_ 849 SeatCshnDrvRR_Pc_Actl 1;
BA_ "U_U55X_MY2022_Tx" SG_ 849 SeatCshnDrvRR_Pc_Actl 1;
BA_ "U_P702_MY2021_Tx" SG_ 849 SeatCshnDrvRR_Pc_Actl 1;
BA_ "GenSigStartValue" SG_ 849 SeatCshnDrvRR_Pc_Actl 127;
BA_ "GenSigStartValueInteger" SG_ 849 SeatCshnDrvRR_Pc_Actl 127;
BA_ "U_CD764_MY2022_Tx" SG_ 849 SeatCshnDrvRL_Pc_Actl 1;
BA_ "U_U55X_MY2022_Tx" SG_ 849 SeatCshnDrvRL_Pc_Actl 1;
BA_ "U_P702_MY2021_Tx" SG_ 849 SeatCshnDrvRL_Pc_Actl 1;
BA_ "GenSigStartValue" SG_ 849 SeatCshnDrvRL_Pc_Actl 127;
BA_ "GenSigStartValueInteger" SG_ 849 SeatCshnDrvRL_Pc_Actl 127;
BA_ "U_CD764_MY2022_Tx" SG_ 849 SeatCshnDrvFR_Pc_Actl 1;
BA_ "U_U55X_MY2022_Tx" SG_ 849 SeatCshnDrvFR_Pc_Actl 1;
BA_ "U_P702_MY2021_Tx" SG_ 849 SeatCshnDrvFR_Pc_Actl 1;
BA_ "GenSigStartValue" SG_ 849 SeatCshnDrvFR_Pc_Actl 127;
BA_ "GenSigStartValueInteger" SG_ 849 SeatCshnDrvFR_Pc_Actl 127;
BA_ "U_CD764_MY2022_Tx" SG_ 849 SeatCshnDrvFL_Pc_Actl 1;
BA_ "U_U55X_MY2022_Tx" SG_ 849 SeatCshnDrvFL_Pc_Actl 1;
BA_ "U_P702_MY2021_Tx" SG_ 849 SeatCshnDrvFL_Pc_Actl 1;
BA_ "GenSigStartValue" SG_ 849 SeatCshnDrvFL_Pc_Actl 127;
BA_ "GenSigStartValueInteger" SG_ 849 SeatCshnDrvFL_Pc_Actl 127;
BA_ "U_U55X_MY2022_Rx" SG_ 846 SeatMasgDrv_D_Rq 1;
BA_ "U_P702_MY2021_Rx" SG_ 846 SeatMasgDrv_D_Rq 1;
BA_ "U_U55X_MY2022_Rx" SG_ 846 SeatMasgPsngr_D_Rq 1;
BA_ "U_P702_MY2021_Rx" SG_ 846 SeatMasgPsngr_D_Rq 1;
BA_ "U_CD764_MY2022_Rx" SG_ 846 SeatLmbr_D_Rq 1;
BA_ "U_CD542_MY2021_Rx" SG_ 846 SeatLmbr_D_Rq 1;
BA_ "U_T6_MCA_MY2020_Rx" SG_ 846 SeatLmbr_D_Rq 1;
BA_ "U_P702_MY2021_Rx" SG_ 846 SeatLmbr_D_Rq 1;
BA_ "U_CX727_MY2021_Rx" SG_ 846 SeatLmbr_D_Rq 1;
BA_ "U_U55X_MY2022_Rx" SG_ 846 SeatLmbr_D_Rq 1;
BA_ "U_CD764_MY2022_Rx" SG_ 846 SeatFnChngPsgr2_D_Rq 1;
BA_ "U_U55X_MY2022_Rx" SG_ 846 SeatFnChngPsgr2_D_Rq 1;
BA_ "U_P702_MY2021_Rx" SG_ 846 SeatFnChngPsgr2_D_Rq 1;
BA_ "U_CD764_MY2022_Rx" SG_ 846 SeatFnChngDrv2_D_Rq 1;
BA_ "U_U55X_MY2022_Rx" SG_ 846 SeatFnChngDrv2_D_Rq 1;
BA_ "U_P702_MY2021_Rx" SG_ 846 SeatFnChngDrv2_D_Rq 1;
BA_ "U_CD764_MY2022_Rx" SG_ 846 SeatFnPsgr_D_Rq 1;
BA_ "U_U55X_MY2022_Rx" SG_ 846 SeatFnPsgr_D_Rq 1;
BA_ "U_P702_MY2021_Rx" SG_ 846 SeatFnPsgr_D_Rq 1;
BA_ "U_CD764_MY2022_Rx" SG_ 846 SeatFnDrv_D_Rq 1;
BA_ "U_U55X_MY2022_Rx" SG_ 846 SeatFnDrv_D_Rq 1;
BA_ "U_P702_MY2021_Rx" SG_ 846 SeatFnDrv_D_Rq 1;
BA_ "U_CD764_MY2022_Rx" SG_ 846 SeatFnDfaltPsgr_B_Rq 1;
BA_ "U_U55X_MY2022_Rx" SG_ 846 SeatFnDfaltPsgr_B_Rq 1;
BA_ "U_P702_MY2021_Rx" SG_ 846 SeatFnDfaltPsgr_B_Rq 1;
BA_ "U_CD764_MY2022_Rx" SG_ 846 SeatFnDfaltDrv_B_Rq 1;
BA_ "U_U55X_MY2022_Rx" SG_ 846 SeatFnDfaltDrv_B_Rq 1;
BA_ "U_P702_MY2021_Rx" SG_ 846 SeatFnDfaltDrv_B_Rq 1;
BA_ "U_CD764_MY2022_Rx" SG_ 846 SeatFnChngPsgr_D_Rq 1;
BA_ "U_U55X_MY2022_Rx" SG_ 846 SeatFnChngPsgr_D_Rq 1;
BA_ "U_P702_MY2021_Rx" SG_ 846 SeatFnChngPsgr_D_Rq 1;
BA_ "U_CD764_MY2022_Rx" SG_ 846 SeatFnChngDrv_D_Rq 1;
BA_ "U_U55X_MY2022_Rx" SG_ 846 SeatFnChngDrv_D_Rq 1;
BA_ "U_P702_MY2021_Rx" SG_ 846 SeatFnChngDrv_D_Rq 1;
BA_ "U_CD764_MY2022_Rx" SG_ 846 PsgrMemory_Rq 1;
BA_ "U_U55X_MY2022_Rx" SG_ 846 PsgrMemory_Rq 1;
BA_ "U_P702_MY2021_Rx" SG_ 846 PsgrMemory_Rq 1;
BA_ "U_CD764_MY2022_Rx" SG_ 868 E_Frt_Btn_Status_2nd 1;
BA_ "GenSigSendType" SG_ 868 E_Frt_Btn_Status_2nd 3;
BA_ "U_CD764_MY2022_Rx" SG_ 868 E_Frt_Btn_Status_1st 1;
BA_ "GenSigSendType" SG_ 868 E_Frt_Btn_Status_1st 3;
BA_ "U_U55X_MY2022_Tx" SG_ 868 Rr_Blower_Indicate_Stat 1;
BA_ "U_CD542_MY2021_Tx" SG_ 868 Rr_Blower_Indicate_Stat 1;
BA_ "U_U55X_MY2022_Rx" SG_ 868 Rr_Blower_Indicate_Stat 1;
BA_ "U_T6_MCA_MY2020_Rx" SG_ 868 Rr_Blower_Indicate_Stat 1;
BA_ "GenSigSendType" SG_ 868 Rr_Blower_Indicate_Stat 3;
BA_ "GenSigStartValue" SG_ 868 Rr_Blower_Indicate_Stat 15;
BA_ "GenSigStartValueInteger" SG_ 868 Rr_Blower_Indicate_Stat 15;
BA_ "GenSigSendType" SG_ 1962 TesterPhysicalResDCME 3;
BA_ "GenSigStartValue" SG_ 1410 DCMH_AutoSarNMReserved1 255;
BA_ "ContentDependant" SG_ 1410 DCMH_AutoSarNMReserved1 1;
BA_ "GenSigStartValueInteger" SG_ 1410 DCMH_AutoSarNMReserved1 255;
BA_ "GenSigStartValue" SG_ 1410 DCMH_GWOnBoardTester 255;
BA_ "ContentDependant" SG_ 1410 DCMH_GWOnBoardTester 1;
BA_ "GenSigStartValueInteger" SG_ 1410 DCMH_GWOnBoardTester 255;
BA_ "GenSigStartValue" SG_ 1410 DCMH_GWNMProxy 255;
BA_ "ContentDependant" SG_ 1410 DCMH_GWNMProxy 1;
BA_ "GenSigStartValueInteger" SG_ 1410 DCMH_GWNMProxy 255;
BA_ "GenSigStartValue" SG_ 1410 DCMH_AutoSarNMReserved4 255;
BA_ "ContentDependant" SG_ 1410 DCMH_AutoSarNMReserved4 1;
BA_ "GenSigStartValueInteger" SG_ 1410 DCMH_AutoSarNMReserved4 255;
BA_ "GenSigStartValue" SG_ 1410 DCMH_AutoSarNMReserved3 255;
BA_ "ContentDependant" SG_ 1410 DCMH_AutoSarNMReserved3 1;
BA_ "GenSigStartValueInteger" SG_ 1410 DCMH_AutoSarNMReserved3 255;
BA_ "GenSigStartValue" SG_ 1410 DCMH_AutoSarNMReserved2 255;
BA_ "ContentDependant" SG_ 1410 DCMH_AutoSarNMReserved2 1;
BA_ "GenSigStartValueInteger" SG_ 1410 DCMH_AutoSarNMReserved2 255;
BA_ "GenSigStartValue" SG_ 1410 DCMH_AutoSarNMNodeId 82;
BA_ "ContentDependant" SG_ 1410 DCMH_AutoSarNMNodeId 1;
BA_ "GenSigStartValueInteger" SG_ 1410 DCMH_AutoSarNMNodeId 82;
BA_ "ContentDependant" SG_ 1410 DCMH_AutoSarNMControl 1;
BA_ "GenSigStartValue" SG_ 1497 DCMG_GWNMProxy 255;
BA_ "ContentDependant" SG_ 1497 DCMG_GWNMProxy 1;
BA_ "GenSigStartValueInteger" SG_ 1497 DCMG_GWNMProxy 255;
BA_ "GenSigStartValue" SG_ 1497 DCMG_GWOnBoardTester 255;
BA_ "ContentDependant" SG_ 1497 DCMG_GWOnBoardTester 1;
BA_ "GenSigStartValueInteger" SG_ 1497 DCMG_GWOnBoardTester 255;
BA_ "GenSigStartValue" SG_ 1497 DCMG_AutoSarNMReserved4 255;
BA_ "ContentDependant" SG_ 1497 DCMG_AutoSarNMReserved4 1;
BA_ "GenSigStartValueInteger" SG_ 1497 DCMG_AutoSarNMReserved4 255;
BA_ "GenSigStartValue" SG_ 1497 DCMG_AutoSarNMReserved3 255;
BA_ "ContentDependant" SG_ 1497 DCMG_AutoSarNMReserved3 1;
BA_ "GenSigStartValueInteger" SG_ 1497 DCMG_AutoSarNMReserved3 255;
BA_ "GenSigStartValue" SG_ 1497 DCMG_AutoSarNMReserved2 255;
BA_ "ContentDependant" SG_ 1497 DCMG_AutoSarNMReserved2 1;
BA_ "GenSigStartValueInteger" SG_ 1497 DCMG_AutoSarNMReserved2 255;
BA_ "GenSigStartValue" SG_ 1497 DCMG_AutoSarNMNodeId 217;
BA_ "ContentDependant" SG_ 1497 DCMG_AutoSarNMNodeId 1;
BA_ "GenSigStartValueInteger" SG_ 1497 DCMG_AutoSarNMNodeId 217;
BA_ "ContentDependant" SG_ 1497 DCMG_AutoSarNMControl 1;
BA_ "GenSigStartValue" SG_ 1497 DCMG_AutoSarNMReserved1 255;
BA_ "ContentDependant" SG_ 1497 DCMG_AutoSarNMReserved1 1;
BA_ "GenSigStartValueInteger" SG_ 1497 DCMG_AutoSarNMReserved1 255;
BA_ "GenSigSendType" SG_ 1805 TesterPhysicalResSFMB 3;
BA_ "U_U55X_MY2022_Tx" SG_ 845 SeatMasgPsngr_D_Stat 1;
BA_ "U_P702_MY2021_Tx" SG_ 845 SeatMasgPsngr_D_Stat 1;
BA_ "GenSigSendType" SG_ 845 SeatMasgPsngr_D_Stat 3;
BA_ "U_U55X_MY2022_Tx" SG_ 845 SeatIntnsPsngr_D_Stat 1;
BA_ "U_P702_MY2021_Tx" SG_ 845 SeatIntnsPsngr_D_Stat 1;
BA_ "GenSigSendType" SG_ 845 SeatIntnsPsngr_D_Stat 3;
BA_ "U_CD764_MY2022_Tx" SG_ 845 StmsLmbrPsgr_D_Stat 1;
BA_ "U_U55X_MY2022_Tx" SG_ 845 StmsLmbrPsgr_D_Stat 1;
BA_ "U_P702_MY2021_Tx" SG_ 845 StmsLmbrPsgr_D_Stat 1;
BA_ "GenSigSendType" SG_ 845 StmsLmbrPsgr_D_Stat 3;
BA_ "U_CD764_MY2022_Tx" SG_ 845 StmsCshnPsgr_D_Stat 1;
BA_ "U_U55X_MY2022_Tx" SG_ 845 StmsCshnPsgr_D_Stat 1;
BA_ "U_P702_MY2021_Tx" SG_ 845 StmsCshnPsgr_D_Stat 1;
BA_ "GenSigSendType" SG_ 845 StmsCshnPsgr_D_Stat 3;
BA_ "U_CD764_MY2022_Tx" SG_ 845 SeatSwtchPsgr_B_Stat 1;
BA_ "U_U55X_MY2022_Tx" SG_ 845 SeatSwtchPsgr_B_Stat 1;
BA_ "U_P702_MY2021_Tx" SG_ 845 SeatSwtchPsgr_B_Stat 1;
BA_ "GenSigSendType" SG_ 845 SeatSwtchPsgr_B_Stat 3;
BA_ "U_CD764_MY2022_Tx" SG_ 845 SeatPPsgr_B_Stat 1;
BA_ "U_U55X_MY2022_Tx" SG_ 845 SeatPPsgr_B_Stat 1;
BA_ "U_P702_MY2021_Tx" SG_ 845 SeatPPsgr_B_Stat 1;
BA_ "GenSigSendType" SG_ 845 SeatPPsgr_B_Stat 3;
BA_ "U_CD764_MY2022_Tx" SG_ 845 SeatFnPsgr_D_Stat 1;
BA_ "U_U55X_MY2022_Tx" SG_ 845 SeatFnPsgr_D_Stat 1;
BA_ "U_P702_MY2021_Tx" SG_ 845 SeatFnPsgr_D_Stat 1;
BA_ "GenSigSendType" SG_ 845 SeatFnPsgr_D_Stat 3;
BA_ "U_CD764_MY2022_Tx" SG_ 845 PsgrMemFeedback_Rsp 1;
BA_ "U_U55X_MY2022_Tx" SG_ 845 PsgrMemFeedback_Rsp 1;
BA_ "U_P702_MY2021_Tx" SG_ 845 PsgrMemFeedback_Rsp 1;
BA_ "GenSigSendType" SG_ 845 PsgrMemFeedback_Rsp 3;
BA_ "U_U55X_MY2022_Tx" SG_ 844 SeatMasgDrv_D_Stat 1;
BA_ "U_P702_MY2021_Tx" SG_ 844 SeatMasgDrv_D_Stat 1;
BA_ "GenSigSendType" SG_ 844 SeatMasgDrv_D_Stat 3;
BA_ "U_U55X_MY2022_Tx" SG_ 844 SeatIntnsDrv_D_Stat 1;
BA_ "U_P702_MY2021_Tx" SG_ 844 SeatIntnsDrv_D_Stat 1;
BA_ "GenSigSendType" SG_ 844 SeatIntnsDrv_D_Stat 3;
BA_ "U_CD764_MY2022_Tx" SG_ 844 StmsLmbrDrv_D_Stat 1;
BA_ "U_U55X_MY2022_Tx" SG_ 844 StmsLmbrDrv_D_Stat 1;
BA_ "U_P702_MY2021_Tx" SG_ 844 StmsLmbrDrv_D_Stat 1;
BA_ "GenSigSendType" SG_ 844 StmsLmbrDrv_D_Stat 3;
BA_ "U_CD764_MY2022_Tx" SG_ 844 StmsCshnDrv_D_Stat 1;
BA_ "U_U55X_MY2022_Tx" SG_ 844 StmsCshnDrv_D_Stat 1;
BA_ "U_P702_MY2021_Tx" SG_ 844 StmsCshnDrv_D_Stat 1;
BA_ "GenSigSendType" SG_ 844 StmsCshnDrv_D_Stat 3;
BA_ "U_CD764_MY2022_Tx" SG_ 844 SeatSwtchDrv_B_Stat 1;
BA_ "U_U55X_MY2022_Tx" SG_ 844 SeatSwtchDrv_B_Stat 1;
BA_ "U_P702_MY2021_Tx" SG_ 844 SeatSwtchDrv_B_Stat 1;
BA_ "GenSigSendType" SG_ 844 SeatSwtchDrv_B_Stat 3;
BA_ "U_CD764_MY2022_Tx" SG_ 844 SeatFnDrv_D_Stat 1;
BA_ "U_U55X_MY2022_Tx" SG_ 844 SeatFnDrv_D_Stat 1;
BA_ "U_P702_MY2021_Tx" SG_ 844 SeatFnDrv_D_Stat 1;
BA_ "GenSigSendType" SG_ 844 SeatFnDrv_D_Stat 3;
BA_ "U_CD764_MY2022_Tx" SG_ 844 SeatAirAmb_P_Actl 1;
BA_ "U_U55X_MY2022_Tx" SG_ 844 SeatAirAmb_P_Actl 1;
BA_ "U_P702_MY2021_Tx" SG_ 844 SeatAirAmb_P_Actl 1;
BA_ "U_CD764_MY2022_Rx" SG_ 844 SeatAirAmb_P_Actl 1;
BA_ "U_U55X_MY2022_Rx" SG_ 844 SeatAirAmb_P_Actl 1;
BA_ "U_P702_MY2021_Rx" SG_ 844 SeatAirAmb_P_Actl 1;
BA_ "U_CD764_MY2022_Tx" SG_ 844 SeatPDrv_B_Stat 1;
BA_ "U_U55X_MY2022_Tx" SG_ 844 SeatPDrv_B_Stat 1;
BA_ "U_P702_MY2021_Tx" SG_ 844 SeatPDrv_B_Stat 1;
BA_ "GenSigSendType" SG_ 844 SeatPDrv_B_Stat 3;
BA_ "U_CD764_MY2022_Tx" SG_ 843 SeatLmbrUpPsgr_Pc_Actl 1;
BA_ "U_U55X_MY2022_Tx" SG_ 843 SeatLmbrUpPsgr_Pc_Actl 1;
BA_ "U_P702_MY2021_Tx" SG_ 843 SeatLmbrUpPsgr_Pc_Actl 1;
BA_ "GenSigSendType" SG_ 843 SeatLmbrUpPsgr_Pc_Actl 3;
BA_ "GenSigStartValue" SG_ 843 SeatLmbrUpPsgr_Pc_Actl 127;
BA_ "GenSigStartValueInteger" SG_ 843 SeatLmbrUpPsgr_Pc_Actl 127;
BA_ "U_CD764_MY2022_Tx" SG_ 843 SeatLmbrMidPsgr_Pc_Actl 1;
BA_ "U_U55X_MY2022_Tx" SG_ 843 SeatLmbrMidPsgr_Pc_Actl 1;
BA_ "U_P702_MY2021_Tx" SG_ 843 SeatLmbrMidPsgr_Pc_Actl 1;
BA_ "GenSigSendType" SG_ 843 SeatLmbrMidPsgr_Pc_Actl 3;
BA_ "GenSigStartValue" SG_ 843 SeatLmbrMidPsgr_Pc_Actl 127;
BA_ "GenSigStartValueInteger" SG_ 843 SeatLmbrMidPsgr_Pc_Actl 127;
BA_ "U_CD764_MY2022_Tx" SG_ 843 SeatLmbrLoPsgr_Pc_Actl 1;
BA_ "U_U55X_MY2022_Tx" SG_ 843 SeatLmbrLoPsgr_Pc_Actl 1;
BA_ "U_P702_MY2021_Tx" SG_ 843 SeatLmbrLoPsgr_Pc_Actl 1;
BA_ "GenSigSendType" SG_ 843 SeatLmbrLoPsgr_Pc_Actl 3;
BA_ "GenSigStartValue" SG_ 843 SeatLmbrLoPsgr_Pc_Actl 127;
BA_ "GenSigStartValueInteger" SG_ 843 SeatLmbrLoPsgr_Pc_Actl 127;
BA_ "U_CD764_MY2022_Tx" SG_ 843 SeatBlUpPsgr_Pc_Actl 1;
BA_ "U_U55X_MY2022_Tx" SG_ 843 SeatBlUpPsgr_Pc_Actl 1;
BA_ "U_P702_MY2021_Tx" SG_ 843 SeatBlUpPsgr_Pc_Actl 1;
BA_ "GenSigSendType" SG_ 843 SeatBlUpPsgr_Pc_Actl 3;
BA_ "GenSigStartValue" SG_ 843 SeatBlUpPsgr_Pc_Actl 127;
BA_ "GenSigStartValueInteger" SG_ 843 SeatBlUpPsgr_Pc_Actl 127;
BA_ "U_CD764_MY2022_Tx" SG_ 843 SeatBlLoPsgr_Pc_Actl 1;
BA_ "U_U55X_MY2022_Tx" SG_ 843 SeatBlLoPsgr_Pc_Actl 1;
BA_ "U_P702_MY2021_Tx" SG_ 843 SeatBlLoPsgr_Pc_Actl 1;
BA_ "GenSigSendType" SG_ 843 SeatBlLoPsgr_Pc_Actl 3;
BA_ "GenSigStartValue" SG_ 843 SeatBlLoPsgr_Pc_Actl 127;
BA_ "GenSigStartValueInteger" SG_ 843 SeatBlLoPsgr_Pc_Actl 127;
BA_ "U_CD764_MY2022_Tx" SG_ 842 SeatLmbrUpDrv_Pc_Actl 1;
BA_ "U_U55X_MY2022_Tx" SG_ 842 SeatLmbrUpDrv_Pc_Actl 1;
BA_ "U_P702_MY2021_Tx" SG_ 842 SeatLmbrUpDrv_Pc_Actl 1;
BA_ "GenSigSendType" SG_ 842 SeatLmbrUpDrv_Pc_Actl 3;
BA_ "GenSigStartValue" SG_ 842 SeatLmbrUpDrv_Pc_Actl 127;
BA_ "GenSigStartValueInteger" SG_ 842 SeatLmbrUpDrv_Pc_Actl 127;
BA_ "U_CD764_MY2022_Tx" SG_ 842 SeatLmbrMidDrv_Pc_Actl 1;
BA_ "U_U55X_MY2022_Tx" SG_ 842 SeatLmbrMidDrv_Pc_Actl 1;
BA_ "U_P702_MY2021_Tx" SG_ 842 SeatLmbrMidDrv_Pc_Actl 1;
BA_ "GenSigSendType" SG_ 842 SeatLmbrMidDrv_Pc_Actl 3;
BA_ "GenSigStartValue" SG_ 842 SeatLmbrMidDrv_Pc_Actl 127;
BA_ "GenSigStartValueInteger" SG_ 842 SeatLmbrMidDrv_Pc_Actl 127;
BA_ "U_CD764_MY2022_Tx" SG_ 842 SeatLmbrLoDrv_Pc_Actl 1;
BA_ "U_U55X_MY2022_Tx" SG_ 842 SeatLmbrLoDrv_Pc_Actl 1;
BA_ "U_P702_MY2021_Tx" SG_ 842 SeatLmbrLoDrv_Pc_Actl 1;
BA_ "GenSigSendType" SG_ 842 SeatLmbrLoDrv_Pc_Actl 3;
BA_ "GenSigStartValue" SG_ 842 SeatLmbrLoDrv_Pc_Actl 127;
BA_ "GenSigStartValueInteger" SG_ 842 SeatLmbrLoDrv_Pc_Actl 127;
BA_ "U_CD764_MY2022_Tx" SG_ 842 SeatBlUpDrv_Pc_Actl 1;
BA_ "U_U55X_MY2022_Tx" SG_ 842 SeatBlUpDrv_Pc_Actl 1;
BA_ "U_P702_MY2021_Tx" SG_ 842 SeatBlUpDrv_Pc_Actl 1;
BA_ "GenSigSendType" SG_ 842 SeatBlUpDrv_Pc_Actl 3;
BA_ "GenSigStartValue" SG_ 842 SeatBlUpDrv_Pc_Actl 127;
BA_ "GenSigStartValueInteger" SG_ 842 SeatBlUpDrv_Pc_Actl 127;
BA_ "U_CD764_MY2022_Tx" SG_ 842 SeatBlLoDrv_Pc_Actl 1;
BA_ "U_U55X_MY2022_Tx" SG_ 842 SeatBlLoDrv_Pc_Actl 1;
BA_ "U_P702_MY2021_Tx" SG_ 842 SeatBlLoDrv_Pc_Actl 1;
BA_ "GenSigSendType" SG_ 842 SeatBlLoDrv_Pc_Actl 3;
BA_ "GenSigStartValue" SG_ 842 SeatBlLoDrv_Pc_Actl 127;
BA_ "GenSigStartValueInteger" SG_ 842 SeatBlLoDrv_Pc_Actl 127;
BA_ "U_U55X_MY2022_Tx" SG_ 1994 TesterPhysicalResRSM 1;
BA_ "U_T6_MCA_MY2020_Tx" SG_ 1994 TesterPhysicalResRSM 1;
BA_ "U_P702_MY2021_Tx" SG_ 1994 TesterPhysicalResRSM 1;
BA_ "U_CX727_MY2021_Tx" SG_ 1994 TesterPhysicalResRSM 1;
BA_ "GenSigSendType" SG_ 1994 TesterPhysicalResRSM 3;
BA_ "U_U55X_MY2022_Rx" SG_ 1986 TesterPhysicalReqRSM 1;
BA_ "U_T6_MCA_MY2020_Rx" SG_ 1986 TesterPhysicalReqRSM 1;
BA_ "U_P702_MY2021_Rx" SG_ 1986 TesterPhysicalReqRSM 1;
BA_ "U_CX727_MY2021_Rx" SG_ 1986 TesterPhysicalReqRSM 1;
BA_ "GenSigSendType" SG_ 1986 TesterPhysicalReqRSM 3;
BA_ "U_CD764_MY2022_Rx" SG_ 958 ElCmprOverTe_D_Stat 1;
BA_ "U_U55X_MY2022_Rx" SG_ 958 ElCmprOverTe_D_Stat 1;
BA_ "U_CD542_MY2021_Rx" SG_ 958 ElCmprOverTe_D_Stat 1;
BA_ "U_T6_MCA_MY2020_Rx" SG_ 958 ElCmprOverTe_D_Stat 1;
BA_ "U_P702_MY2021_Rx" SG_ 958 ElCmprOverTe_D_Stat 1;
BA_ "U_CX727_MY2021_Rx" SG_ 958 ElCmprOverTe_D_Stat 1;
BA_ "GenSigSendType" SG_ 958 ElCmprOverTe_D_Stat 3;
BA_ "U_CD764_MY2022_Rx" SG_ 958 ElCmprOverTe_D_Stat_UB 1;
BA_ "U_U55X_MY2022_Rx" SG_ 958 ElCmprOverTe_D_Stat_UB 1;
BA_ "U_CD542_MY2021_Rx" SG_ 958 ElCmprOverTe_D_Stat_UB 1;
BA_ "U_T6_MCA_MY2020_Rx" SG_ 958 ElCmprOverTe_D_Stat_UB 1;
BA_ "U_P702_MY2021_Rx" SG_ 958 ElCmprOverTe_D_Stat_UB 1;
BA_ "U_CX727_MY2021_Rx" SG_ 958 ElCmprOverTe_D_Stat_UB 1;
BA_ "U_CD764_MY2022_Rx" SG_ 958 EngOff_T_Actl 1;
BA_ "U_U55X_MY2022_Rx" SG_ 958 EngOff_T_Actl 1;
BA_ "U_CD542_MY2021_Rx" SG_ 958 EngOff_T_Actl 1;
BA_ "U_T6_MCA_MY2020_Rx" SG_ 958 EngOff_T_Actl 1;
BA_ "U_P702_MY2021_Rx" SG_ 958 EngOff_T_Actl 1;
BA_ "U_CX727_MY2021_Rx" SG_ 958 EngOff_T_Actl 1;
BA_ "GenSigSendType" SG_ 958 EngOff_T_Actl 3;
BA_ "U_CD764_MY2022_Rx" SG_ 958 EngOff_T_Actl_UB 1;
BA_ "U_U55X_MY2022_Rx" SG_ 958 EngOff_T_Actl_UB 1;
BA_ "U_CD542_MY2021_Rx" SG_ 958 EngOff_T_Actl_UB 1;
BA_ "U_T6_MCA_MY2020_Rx" SG_ 958 EngOff_T_Actl_UB 1;
BA_ "U_P702_MY2021_Rx" SG_ 958 EngOff_T_Actl_UB 1;
BA_ "U_CX727_MY2021_Rx" SG_ 958 EngOff_T_Actl_UB 1;
BA_ "U_T6_MCA_MY2020_Rx" SG_ 958 StopStrtDrvMde_D_Indic_UB 1;
BA_ "U_CD764_MY2022_Rx" SG_ 958 StopStrtDrvMde_D_Indic_UB 1;
BA_ "U_U55X_MY2022_Rx" SG_ 958 StopStrtDrvMde_D_Indic_UB 1;
BA_ "U_CD542_MY2021_Rx" SG_ 958 StopStrtDrvMde_D_Indic_UB 1;
BA_ "U_CX727_MY2021_Rx" SG_ 958 StopStrtDrvMde_D_Indic_UB 1;
BA_ "U_U55X_MY2022_Rx" SG_ 958 PrmtrAlrmEvnt_D_Stat 1;
BA_ "U_T6_MCA_MY2020_Rx" SG_ 958 PrmtrAlrmEvnt_D_Stat 1;
BA_ "U_P702_MY2021_Rx" SG_ 958 PrmtrAlrmEvnt_D_Stat 1;
BA_ "U_CX727_MY2021_Rx" SG_ 958 PrmtrAlrmEvnt_D_Stat 1;
BA_ "GenSigSendType" SG_ 958 PrmtrAlrmEvnt_D_Stat 3;
BA_ "U_U55X_MY2022_Rx" SG_ 958 PrmtrAlrmEvnt_D_Stat_UB 1;
BA_ "U_T6_MCA_MY2020_Rx" SG_ 958 PrmtrAlrmEvnt_D_Stat_UB 1;
BA_ "U_P702_MY2021_Rx" SG_ 958 PrmtrAlrmEvnt_D_Stat_UB 1;
BA_ "U_CX727_MY2021_Rx" SG_ 958 PrmtrAlrmEvnt_D_Stat_UB 1;
BA_ "U_T6_MCA_MY2020_Rx" SG_ 958 StopStrtDrvMde_D_Indic 1;
BA_ "U_CD764_MY2022_Rx" SG_ 958 StopStrtDrvMde_D_Indic 1;
BA_ "U_U55X_MY2022_Rx" SG_ 958 StopStrtDrvMde_D_Indic 1;
BA_ "U_CD542_MY2021_Rx" SG_ 958 StopStrtDrvMde_D_Indic 1;
BA_ "U_CX727_MY2021_Rx" SG_ 958 StopStrtDrvMde_D_Indic 1;
BA_ "GenSigSendType" SG_ 958 StopStrtDrvMde_D_Indic 3;
BA_ "GenSigSendType" SG_ 958 FuelLvl_Pc_Dsply 3;
BA_ "U_CD764_MY2022_Rx" SG_ 958 OdometerMasterValue_UB 1;
BA_ "U_P702_MY2021_Rx" SG_ 958 OdometerMasterValue_UB 1;
BA_ "U_U55X_MY2022_Rx" SG_ 958 OdometerMasterValue_UB 1;
BA_ "U_CD542_MY2021_Rx" SG_ 958 OdometerMasterValue_UB 1;
BA_ "U_CX727_MY2021_Rx" SG_ 958 OdometerMasterValue_UB 1;
BA_ "U_CD764_MY2022_Rx" SG_ 958 OdometerMasterValue 1;
BA_ "U_P702_MY2021_Rx" SG_ 958 OdometerMasterValue 1;
BA_ "U_U55X_MY2022_Rx" SG_ 958 OdometerMasterValue 1;
BA_ "U_CD542_MY2021_Rx" SG_ 958 OdometerMasterValue 1;
BA_ "U_CX727_MY2021_Rx" SG_ 958 OdometerMasterValue 1;
BA_ "GenSigSendType" SG_ 958 OdometerMasterValue 3;
BA_ "GenSigSendType" SG_ 827 LghtAmbIntns_D2_Sns 3;
BA_ "GenSigStartValue" SG_ 827 LghtAmbIntns_D2_Sns 3;
BA_ "U_CD764_MY2022_Rx" SG_ 827 SteClmnSwtchTlt_D_Stat 1;
BA_ "U_U55X_MY2022_Rx" SG_ 827 SteClmnSwtchTlt_D_Stat 1;
BA_ "U_CD542_MY2021_Rx" SG_ 827 SteClmnSwtchTlt_D_Stat 1;
BA_ "U_T6_MCA_MY2020_Rx" SG_ 827 SteClmnSwtchTlt_D_Stat 1;
BA_ "U_P702_MY2021_Rx" SG_ 827 SteClmnSwtchTlt_D_Stat 1;
BA_ "U_CX727_MY2021_Rx" SG_ 827 SteClmnSwtchTlt_D_Stat 1;
BA_ "GenSigSendType" SG_ 827 SteClmnSwtchTlt_D_Stat 3;
BA_ "WakeupSignal" SG_ 827 SteClmnSwtchTlt_D_Stat 1;
BA_ "U_CD764_MY2022_Rx" SG_ 827 SteClmnSwtchTel_D_Stat 1;
BA_ "U_U55X_MY2022_Rx" SG_ 827 SteClmnSwtchTel_D_Stat 1;
BA_ "U_CD542_MY2021_Rx" SG_ 827 SteClmnSwtchTel_D_Stat 1;
BA_ "U_T6_MCA_MY2020_Rx" SG_ 827 SteClmnSwtchTel_D_Stat 1;
BA_ "U_P702_MY2021_Rx" SG_ 827 SteClmnSwtchTel_D_Stat 1;
BA_ "U_CX727_MY2021_Rx" SG_ 827 SteClmnSwtchTel_D_Stat 1;
BA_ "GenSigSendType" SG_ 827 SteClmnSwtchTel_D_Stat 3;
BA_ "WakeupSignal" SG_ 827 SteClmnSwtchTel_D_Stat 1;
BA_ "GenSigSendType" SG_ 827 LghtAmbIntns_D_Sns 3;
BA_ "U_U55X_MY2022_Tx" SG_ 902 PrmtrAlrmWarnRq_No_Actl 1;
BA_ "U_T6_MCA_MY2020_Tx" SG_ 902 PrmtrAlrmWarnRq_No_Actl 1;
BA_ "U_P702_MY2021_Tx" SG_ 902 PrmtrAlrmWarnRq_No_Actl 1;
BA_ "U_CX727_MY2021_Tx" SG_ 902 PrmtrAlrmWarnRq_No_Actl 1;
BA_ "GenSigSendType" SG_ 902 PrmtrAlrmWarnRq_No_Actl 3;
BA_ "WakeupSignal" SG_ 902 PrmtrAlrmWarnRq_No_Actl 1;
BA_ "U_U55X_MY2022_Tx" SG_ 902 PrmtrAlrmTrgRq_No_Actl 1;
BA_ "U_T6_MCA_MY2020_Tx" SG_ 902 PrmtrAlrmTrgRq_No_Actl 1;
BA_ "U_P702_MY2021_Tx" SG_ 902 PrmtrAlrmTrgRq_No_Actl 1;
BA_ "U_CX727_MY2021_Tx" SG_ 902 PrmtrAlrmTrgRq_No_Actl 1;
BA_ "GenSigSendType" SG_ 902 PrmtrAlrmTrgRq_No_Actl 3;
BA_ "WakeupSignal" SG_ 902 PrmtrAlrmTrgRq_No_Actl 1;
BA_ "U_U55X_MY2022_Tx" SG_ 902 Remote_Start_Req 1;
BA_ "U_T6_MCA_MY2020_Tx" SG_ 902 Remote_Start_Req 1;
BA_ "U_P702_MY2021_Tx" SG_ 902 Remote_Start_Req 1;
BA_ "U_CX727_MY2021_Tx" SG_ 902 Remote_Start_Req 1;
BA_ "GenSigSendType" SG_ 902 Remote_Start_Req 3;
BA_ "WakeupSignal" SG_ 902 Remote_Start_Req 1;
BA_ "U_U55X_MY2022_Tx" SG_ 902 RollCode_No_ActlRsm 1;
BA_ "U_T6_MCA_MY2020_Tx" SG_ 902 RollCode_No_ActlRsm 1;
BA_ "U_P702_MY2021_Tx" SG_ 902 RollCode_No_ActlRsm 1;
BA_ "U_CX727_MY2021_Tx" SG_ 902 RollCode_No_ActlRsm 1;
BA_ "GenSigSendType" SG_ 902 RollCode_No_ActlRsm 3;
BA_ "WakeupSignal" SG_ 902 RollCode_No_ActlRsm 1;
BA_ "U_U55X_MY2022_Tx" SG_ 902 PrmtrAlrmWarn_B_Rq 1;
BA_ "U_T6_MCA_MY2020_Tx" SG_ 902 PrmtrAlrmWarn_B_Rq 1;
BA_ "U_P702_MY2021_Tx" SG_ 902 PrmtrAlrmWarn_B_Rq 1;
BA_ "U_CX727_MY2021_Tx" SG_ 902 PrmtrAlrmWarn_B_Rq 1;
BA_ "GenSigSendType" SG_ 902 PrmtrAlrmWarn_B_Rq 3;
BA_ "WakeupSignal" SG_ 902 PrmtrAlrmWarn_B_Rq 1;
BA_ "U_U55X_MY2022_Tx" SG_ 902 PrmtrAlrmTrg_B_Rq 1;
BA_ "U_T6_MCA_MY2020_Tx" SG_ 902 PrmtrAlrmTrg_B_Rq 1;
BA_ "U_P702_MY2021_Tx" SG_ 902 PrmtrAlrmTrg_B_Rq 1;
BA_ "U_CX727_MY2021_Tx" SG_ 902 PrmtrAlrmTrg_B_Rq 1;
BA_ "GenSigSendType" SG_ 902 PrmtrAlrmTrg_B_Rq 3;
BA_ "WakeupSignal" SG_ 902 PrmtrAlrmTrg_B_Rq 1;
BA_ "U_U55X_MY2022_Tx" SG_ 902 PanicRq_No_ActlRsm 1;
BA_ "U_T6_MCA_MY2020_Tx" SG_ 902 PanicRq_No_ActlRsm 1;
BA_ "U_P702_MY2021_Tx" SG_ 902 PanicRq_No_ActlRsm 1;
BA_ "U_CX727_MY2021_Tx" SG_ 902 PanicRq_No_ActlRsm 1;
BA_ "GenSigSendType" SG_ 902 PanicRq_No_ActlRsm 3;
BA_ "WakeupSignal" SG_ 902 PanicRq_No_ActlRsm 1;
BA_ "U_U55X_MY2022_Tx" SG_ 902 Panic_D_RqRsm 1;
BA_ "U_T6_MCA_MY2020_Tx" SG_ 902 Panic_D_RqRsm 1;
BA_ "U_P702_MY2021_Tx" SG_ 902 Panic_D_RqRsm 1;
BA_ "U_CX727_MY2021_Tx" SG_ 902 Panic_D_RqRsm 1;
BA_ "GenSigSendType" SG_ 902 Panic_D_RqRsm 3;
BA_ "WakeupSignal" SG_ 902 Panic_D_RqRsm 1;
BA_ "U_U55X_MY2022_Tx" SG_ 902 CellLockRq_No_ActlRsm 1;
BA_ "U_T6_MCA_MY2020_Tx" SG_ 902 CellLockRq_No_ActlRsm 1;
BA_ "U_P702_MY2021_Tx" SG_ 902 CellLockRq_No_ActlRsm 1;
BA_ "U_CX727_MY2021_Tx" SG_ 902 CellLockRq_No_ActlRsm 1;
BA_ "GenSigSendType" SG_ 902 CellLockRq_No_ActlRsm 3;
BA_ "WakeupSignal" SG_ 902 CellLockRq_No_ActlRsm 1;
BA_ "U_U55X_MY2022_Tx" SG_ 902 CellLock_D_RqRsm 1;
BA_ "U_T6_MCA_MY2020_Tx" SG_ 902 CellLock_D_RqRsm 1;
BA_ "U_P702_MY2021_Tx" SG_ 902 CellLock_D_RqRsm 1;
BA_ "U_CX727_MY2021_Tx" SG_ 902 CellLock_D_RqRsm 1;
BA_ "GenSigSendType" SG_ 902 CellLock_D_RqRsm 3;
BA_ "WakeupSignal" SG_ 902 CellLock_D_RqRsm 1;
BA_ "U_CD764_MY2022_Rx" SG_ 765 CcStat_D_Actl_UB 1;
BA_ "U_U55X_MY2022_Rx" SG_ 765 CcStat_D_Actl_UB 1;
BA_ "U_CD542_MY2021_Rx" SG_ 765 CcStat_D_Actl_UB 1;
BA_ "U_T6_MCA_MY2020_Rx" SG_ 765 CcStat_D_Actl_UB 1;
BA_ "U_CD764_MY2022_Rx" SG_ 765 CcStat_D_Actl 1;
BA_ "U_U55X_MY2022_Rx" SG_ 765 CcStat_D_Actl 1;
BA_ "U_CD542_MY2021_Rx" SG_ 765 CcStat_D_Actl 1;
BA_ "U_T6_MCA_MY2020_Rx" SG_ 765 CcStat_D_Actl 1;
BA_ "U_CD764_MY2022_Rx" SG_ 765 PrplTqMnSat_B_Actl_UB 1;
BA_ "U_U55X_MY2022_Rx" SG_ 765 PrplTqMnSat_B_Actl_UB 1;
BA_ "U_CD542_MY2021_Rx" SG_ 765 PrplTqMnSat_B_Actl_UB 1;
BA_ "U_T6_MCA_MY2020_Rx" SG_ 765 PrplTqMnSat_B_Actl_UB 1;
BA_ "U_CD764_MY2022_Rx" SG_ 765 PrplTqMnSat_B_Actl 1;
BA_ "U_U55X_MY2022_Rx" SG_ 765 PrplTqMnSat_B_Actl 1;
BA_ "U_CD542_MY2021_Rx" SG_ 765 PrplTqMnSat_B_Actl 1;
BA_ "U_T6_MCA_MY2020_Rx" SG_ 765 PrplTqMnSat_B_Actl 1;
BA_ "U_CD764_MY2022_Rx" SG_ 765 ClimtBlwrLim_B_Rq 1;
BA_ "U_U55X_MY2022_Rx" SG_ 765 ClimtBlwrLim_B_Rq 1;
BA_ "U_CD542_MY2021_Rx" SG_ 765 ClimtBlwrLim_B_Rq 1;
BA_ "U_T6_MCA_MY2020_Rx" SG_ 765 ClimtBlwrLim_B_Rq 1;
BA_ "GenSigSendType" SG_ 765 ClimtBlwrLim_B_Rq 3;
BA_ "ContentDependant" SG_ 765 ClimtBlwrLim_B_Rq 1;
BA_ "U_CD764_MY2022_Rx" SG_ 765 ClimtBlwrLim_B_Rq_UB 1;
BA_ "U_U55X_MY2022_Rx" SG_ 765 ClimtBlwrLim_B_Rq_UB 1;
BA_ "U_CD542_MY2021_Rx" SG_ 765 ClimtBlwrLim_B_Rq_UB 1;
BA_ "U_T6_MCA_MY2020_Rx" SG_ 765 ClimtBlwrLim_B_Rq_UB 1;
BA_ "U_CX727_MY2021_Rx" SG_ 765 ClimtBlwrLim_B_Rq_UB 1;
BA_ "GenSigSendType" SG_ 765 TrlrBrkActCnnct_B_Actl 3;
BA_ "U_CD764_MY2022_Rx" SG_ 765 EmPrflButtnAssoc_D_Rq 1;
BA_ "U_U55X_MY2022_Rx" SG_ 765 EmPrflButtnAssoc_D_Rq 1;
BA_ "U_CD542_MY2021_Rx" SG_ 765 EmPrflButtnAssoc_D_Rq 1;
BA_ "U_T6_MCA_MY2020_Rx" SG_ 765 EmPrflButtnAssoc_D_Rq 1;
BA_ "U_P702_MY2021_Rx" SG_ 765 EmPrflButtnAssoc_D_Rq 1;
BA_ "U_CX727_MY2021_Rx" SG_ 765 EmPrflButtnAssoc_D_Rq 1;
BA_ "GenSigSendType" SG_ 765 EmPrflButtnAssoc_D_Rq 3;
BA_ "U_CD764_MY2022_Rx" SG_ 765 EmPrflButtnAssoc_D_Rq_UB 1;
BA_ "U_U55X_MY2022_Rx" SG_ 765 EmPrflButtnAssoc_D_Rq_UB 1;
BA_ "U_CD542_MY2021_Rx" SG_ 765 EmPrflButtnAssoc_D_Rq_UB 1;
BA_ "U_T6_MCA_MY2020_Rx" SG_ 765 EmPrflButtnAssoc_D_Rq_UB 1;
BA_ "U_P702_MY2021_Rx" SG_ 765 EmPrflButtnAssoc_D_Rq_UB 1;
BA_ "U_CX727_MY2021_Rx" SG_ 765 EmPrflButtnAssoc_D_Rq_UB 1;
BA_ "U_CD764_MY2022_Rx" SG_ 765 CamraFrntStat_D_Stat_UB 1;
BA_ "U_U55X_MY2022_Rx" SG_ 765 CamraFrntStat_D_Stat_UB 1;
BA_ "U_CD542_MY2021_Rx" SG_ 765 CamraFrntStat_D_Stat_UB 1;
BA_ "U_T6_MCA_MY2020_Rx" SG_ 765 CamraFrntStat_D_Stat_UB 1;
BA_ "U_CX727_MY2021_Rx" SG_ 765 CamraFrntStat_D_Stat_UB 1;
BA_ "U_CD764_MY2022_Rx" SG_ 765 CamraFrntStat_D_Stat 1;
BA_ "U_U55X_MY2022_Rx" SG_ 765 CamraFrntStat_D_Stat 1;
BA_ "U_CD542_MY2021_Rx" SG_ 765 CamraFrntStat_D_Stat 1;
BA_ "U_T6_MCA_MY2020_Rx" SG_ 765 CamraFrntStat_D_Stat 1;
BA_ "U_CX727_MY2021_Rx" SG_ 765 CamraFrntStat_D_Stat 1;
BA_ "GenSigSendType" SG_ 765 CamraFrntStat_D_Stat 3;
BA_ "U_U55X_MY2022_Rx" SG_ 765 AutoHoldSwMde_B_Ind_UB 1;
BA_ "U_CD542_MY2021_Rx" SG_ 765 AutoHoldSwMde_B_Ind_UB 1;
BA_ "U_CX727_MY2021_Rx" SG_ 765 AutoHoldSwMde_B_Ind_UB 1;
BA_ "U_U55X_MY2022_Rx" SG_ 765 AutoHoldSwMde_B_Ind 1;
BA_ "U_CD542_MY2021_Rx" SG_ 765 AutoHoldSwMde_B_Ind 1;
BA_ "U_CX727_MY2021_Rx" SG_ 765 AutoHoldSwMde_B_Ind 1;
BA_ "GenSigSendType" SG_ 765 AutoHoldSwMde_B_Ind 3;
BA_ "ContentDependant" SG_ 765 AutoHoldSwMde_B_Ind 1;
BA_ "U_CD764_MY2022_Rx" SG_ 765 ValetMode_D_Stat_UB 1;
BA_ "U_U55X_MY2022_Rx" SG_ 765 ValetMode_D_Stat_UB 1;
BA_ "U_CD542_MY2021_Rx" SG_ 765 ValetMode_D_Stat_UB 1;
BA_ "U_T6_MCA_MY2020_Rx" SG_ 765 ValetMode_D_Stat_UB 1;
BA_ "U_P702_MY2021_Rx" SG_ 765 ValetMode_D_Stat_UB 1;
BA_ "U_CX727_MY2021_Rx" SG_ 765 ValetMode_D_Stat_UB 1;
BA_ "U_CD764_MY2022_Rx" SG_ 765 ValetMode_D_Stat 1;
BA_ "U_U55X_MY2022_Rx" SG_ 765 ValetMode_D_Stat 1;
BA_ "U_CD542_MY2021_Rx" SG_ 765 ValetMode_D_Stat 1;
BA_ "U_T6_MCA_MY2020_Rx" SG_ 765 ValetMode_D_Stat 1;
BA_ "U_P702_MY2021_Rx" SG_ 765 ValetMode_D_Stat 1;
BA_ "U_CX727_MY2021_Rx" SG_ 765 ValetMode_D_Stat 1;
BA_ "GenSigSendType" SG_ 765 ValetMode_D_Stat 3;
BA_ "U_CD764_MY2022_Rx" SG_ 765 SteWhlHeat_D_Stat 1;
BA_ "U_U55X_MY2022_Rx" SG_ 765 SteWhlHeat_D_Stat 1;
BA_ "U_CD542_MY2021_Rx" SG_ 765 SteWhlHeat_D_Stat 1;
BA_ "U_CX727_MY2021_Rx" SG_ 765 SteWhlHeat_D_Stat 1;
BA_ "GenSigSendType" SG_ 765 SteWhlHeat_D_Stat 3;
BA_ "U_U55X_MY2022_Rx" SG_ 765 Running_Board_Cmd_UB 1;
BA_ "U_P702_MY2021_Rx" SG_ 765 Running_Board_Cmd_UB 1;
BA_ "U_U55X_MY2022_Rx" SG_ 765 Running_Board_Cmd 1;
BA_ "U_P702_MY2021_Rx" SG_ 765 Running_Board_Cmd 1;
BA_ "GenSigSendType" SG_ 765 Running_Board_Cmd 3;
BA_ "U_U55X_MY2022_Rx" SG_ 765 Bezel_Beeps_Rq_UB 1;
BA_ "U_T6_MCA_MY2020_Rx" SG_ 765 Bezel_Beeps_Rq_UB 1;
BA_ "U_U55X_MY2022_Rx" SG_ 765 Bezel_Beeps_Rq 1;
BA_ "U_T6_MCA_MY2020_Rx" SG_ 765 Bezel_Beeps_Rq 1;
BA_ "GenSigSendType" SG_ 765 Bezel_Beeps_Rq 3;
BA_ "WakeupSignal" SG_ 765 Bezel_Beeps_Rq 1;
BA_ "U_CD764_MY2022_Rx" SG_ 765 Diagnostic_Operation_Rq_UB 1;
BA_ "U_U55X_MY2022_Rx" SG_ 765 Diagnostic_Operation_Rq_UB 1;
BA_ "U_CD542_MY2021_Rx" SG_ 765 Diagnostic_Operation_Rq_UB 1;
BA_ "U_T6_MCA_MY2020_Rx" SG_ 765 Diagnostic_Operation_Rq_UB 1;
BA_ "U_P702_MY2021_Rx" SG_ 765 Diagnostic_Operation_Rq_UB 1;
BA_ "U_CX727_MY2021_Rx" SG_ 765 Diagnostic_Operation_Rq_UB 1;
BA_ "U_U55X_MY2022_Rx" SG_ 765 Bezel_Diag_State_Rq_UB 1;
BA_ "U_T6_MCA_MY2020_Rx" SG_ 765 Bezel_Diag_State_Rq_UB 1;
BA_ "U_U55X_MY2022_Rx" SG_ 765 Bezel_Diag_Module_Rq_UB 1;
BA_ "U_T6_MCA_MY2020_Rx" SG_ 765 Bezel_Diag_Module_Rq_UB 1;
BA_ "U_CD764_MY2022_Rx" SG_ 765 Diagnostic_Operation_Rq 1;
BA_ "U_U55X_MY2022_Rx" SG_ 765 Diagnostic_Operation_Rq 1;
BA_ "U_CD542_MY2021_Rx" SG_ 765 Diagnostic_Operation_Rq 1;
BA_ "U_T6_MCA_MY2020_Rx" SG_ 765 Diagnostic_Operation_Rq 1;
BA_ "U_P702_MY2021_Rx" SG_ 765 Diagnostic_Operation_Rq 1;
BA_ "U_CX727_MY2021_Rx" SG_ 765 Diagnostic_Operation_Rq 1;
BA_ "GenSigSendType" SG_ 765 Diagnostic_Operation_Rq 3;
BA_ "U_U55X_MY2022_Rx" SG_ 765 Bezel_Diag_State_Rq 1;
BA_ "U_T6_MCA_MY2020_Rx" SG_ 765 Bezel_Diag_State_Rq 1;
BA_ "GenSigSendType" SG_ 765 Bezel_Diag_State_Rq 3;
BA_ "U_U55X_MY2022_Rx" SG_ 765 Bezel_Diag_Module_Rq 1;
BA_ "U_T6_MCA_MY2020_Rx" SG_ 765 Bezel_Diag_Module_Rq 1;
BA_ "GenSigSendType" SG_ 765 Bezel_Diag_Module_Rq 3;
BA_ "U_P702_MY2021_Rx" SG_ 765 HMI_HMIMode_St_UB 1;
BA_ "U_CD764_MY2022_Rx" SG_ 765 HMI_HMIMode_St_UB 1;
BA_ "U_U55X_MY2022_Rx" SG_ 765 HMI_HMIMode_St_UB 1;
BA_ "U_CD542_MY2021_Rx" SG_ 765 HMI_HMIMode_St_UB 1;
BA_ "U_T6_MCA_MY2020_Rx" SG_ 765 HMI_HMIMode_St_UB 1;
BA_ "U_CX727_MY2021_Rx" SG_ 765 HMI_HMIMode_St_UB 1;
BA_ "U_P702_MY2021_Rx" SG_ 765 HMI_HMIMode_St 1;
BA_ "U_CD764_MY2022_Rx" SG_ 765 HMI_HMIMode_St 1;
BA_ "U_U55X_MY2022_Rx" SG_ 765 HMI_HMIMode_St 1;
BA_ "U_CD542_MY2021_Rx" SG_ 765 HMI_HMIMode_St 1;
BA_ "U_T6_MCA_MY2020_Rx" SG_ 765 HMI_HMIMode_St 1;
BA_ "U_CX727_MY2021_Rx" SG_ 765 HMI_HMIMode_St 1;
BA_ "GenSigSendType" SG_ 765 HMI_HMIMode_St 3;
BA_ "WakeupSignal" SG_ 765 HMI_HMIMode_St 1;
BA_ "U_CD764_MY2022_Rx" SG_ 765 Mc_VehUnitTempUsrSel_St_UB 1;
BA_ "U_U55X_MY2022_Rx" SG_ 765 Mc_VehUnitTempUsrSel_St_UB 1;
BA_ "U_CD542_MY2021_Rx" SG_ 765 Mc_VehUnitTempUsrSel_St_UB 1;
BA_ "U_T6_MCA_MY2020_Rx" SG_ 765 Mc_VehUnitTempUsrSel_St_UB 1;
BA_ "U_P702_MY2021_Rx" SG_ 765 Mc_VehUnitTempUsrSel_St_UB 1;
BA_ "U_CX727_MY2021_Rx" SG_ 765 Mc_VehUnitTempUsrSel_St_UB 1;
BA_ "U_CD764_MY2022_Rx" SG_ 765 Mc_VehUnitTempUsrSel_St 1;
BA_ "U_U55X_MY2022_Rx" SG_ 765 Mc_VehUnitTempUsrSel_St 1;
BA_ "U_CD542_MY2021_Rx" SG_ 765 Mc_VehUnitTempUsrSel_St 1;
BA_ "U_T6_MCA_MY2020_Rx" SG_ 765 Mc_VehUnitTempUsrSel_St 1;
BA_ "U_P702_MY2021_Rx" SG_ 765 Mc_VehUnitTempUsrSel_St 1;
BA_ "U_CX727_MY2021_Rx" SG_ 765 Mc_VehUnitTempUsrSel_St 1;
BA_ "GenSigSendType" SG_ 765 Mc_VehUnitTempUsrSel_St 3;
BA_ "U_CD764_MY2022_Rx" SG_ 765 PsngrFrntDetct_D_Actl_UB 1;
BA_ "U_U55X_MY2022_Rx" SG_ 765 PsngrFrntDetct_D_Actl_UB 1;
BA_ "U_CD542_MY2021_Rx" SG_ 765 PsngrFrntDetct_D_Actl_UB 1;
BA_ "U_T6_MCA_MY2020_Rx" SG_ 765 PsngrFrntDetct_D_Actl_UB 1;
BA_ "U_P702_MY2021_Rx" SG_ 765 PsngrFrntDetct_D_Actl_UB 1;
BA_ "U_CX727_MY2021_Rx" SG_ 765 PsngrFrntDetct_D_Actl_UB 1;
BA_ "U_CD764_MY2022_Rx" SG_ 765 PsngrFrntDetct_D_Actl 1;
BA_ "U_U55X_MY2022_Rx" SG_ 765 PsngrFrntDetct_D_Actl 1;
BA_ "U_CD542_MY2021_Rx" SG_ 765 PsngrFrntDetct_D_Actl 1;
BA_ "U_T6_MCA_MY2020_Rx" SG_ 765 PsngrFrntDetct_D_Actl 1;
BA_ "U_P702_MY2021_Rx" SG_ 765 PsngrFrntDetct_D_Actl 1;
BA_ "U_CX727_MY2021_Rx" SG_ 765 PsngrFrntDetct_D_Actl 1;
BA_ "GenSigSendType" SG_ 765 PsngrFrntDetct_D_Actl 3;
BA_ "GenSigStartValue" SG_ 765 PsngrFrntDetct_D_Actl 3;
BA_ "GenSigStartValueInteger" SG_ 765 PsngrFrntDetct_D_Actl 3;
BA_ "U_CD764_MY2022_Rx" SG_ 765 SteWhlHeat_D_Stat_UB 1;
BA_ "U_U55X_MY2022_Rx" SG_ 765 SteWhlHeat_D_Stat_UB 1;
BA_ "U_CD542_MY2021_Rx" SG_ 765 SteWhlHeat_D_Stat_UB 1;
BA_ "U_T6_MCA_MY2020_Rx" SG_ 765 SteWhlHeat_D_Stat_UB 1;
BA_ "U_CX727_MY2021_Rx" SG_ 765 SteWhlHeat_D_Stat_UB 1;
BA_ "GenSigSendType" SG_ 765 PrkAidLamp_D_Rq 3;
BA_ "U_U55X_MY2022_Rx" SG_ 765 ParkDetect_Stat_UB 1;
BA_ "U_T6_MCA_MY2020_Rx" SG_ 765 ParkDetect_Stat_UB 1;
BA_ "U_P702_MY2021_Rx" SG_ 765 ParkDetect_Stat_UB 1;
BA_ "U_CX727_MY2021_Rx" SG_ 765 ParkDetect_Stat_UB 1;
BA_ "U_U55X_MY2022_Rx" SG_ 765 ParkDetect_Stat 1;
BA_ "U_T6_MCA_MY2020_Rx" SG_ 765 ParkDetect_Stat 1;
BA_ "U_P702_MY2021_Rx" SG_ 765 ParkDetect_Stat 1;
BA_ "U_CX727_MY2021_Rx" SG_ 765 ParkDetect_Stat 1;
BA_ "GenSigSendType" SG_ 765 ParkDetect_Stat 3;
BA_ "U_CD764_MY2022_Rx" SG_ 765 Voice_Blower_Limit 1;
BA_ "U_U55X_MY2022_Rx" SG_ 765 Voice_Blower_Limit 1;
BA_ "U_CD542_MY2021_Rx" SG_ 765 Voice_Blower_Limit 1;
BA_ "U_T6_MCA_MY2020_Rx" SG_ 765 Voice_Blower_Limit 1;
BA_ "GenSigSendType" SG_ 765 Voice_Blower_Limit 3;
BA_ "U_CD764_MY2022_Rx" SG_ 765 Voice_Blower_Limit_UB 1;
BA_ "U_U55X_MY2022_Rx" SG_ 765 Voice_Blower_Limit_UB 1;
BA_ "U_CD542_MY2021_Rx" SG_ 765 Voice_Blower_Limit_UB 1;
BA_ "U_T6_MCA_MY2020_Rx" SG_ 765 Voice_Blower_Limit_UB 1;
BA_ "U_CD542_MY2021_Rx" SG_ 765 PwStep_D_DrvInhbt_UB 1;
BA_ "U_T6_MCA_MY2020_Rx" SG_ 765 PwStep_D_DrvInhbt_UB 1;
BA_ "U_P702_MY2021_Rx" SG_ 765 PwStep_D_DrvInhbt_UB 1;
BA_ "U_U55X_MY2022_Rx" SG_ 765 PwStep_D_DrvInhbt_UB 1;
BA_ "U_CD542_MY2021_Rx" SG_ 765 PwStep_D_DrvInhbt 1;
BA_ "U_T6_MCA_MY2020_Rx" SG_ 765 PwStep_D_DrvInhbt 1;
BA_ "U_P702_MY2021_Rx" SG_ 765 PwStep_D_DrvInhbt 1;
BA_ "U_U55X_MY2022_Rx" SG_ 765 PwStep_D_DrvInhbt 1;
BA_ "GenSigSendType" SG_ 765 PwStep_D_DrvInhbt 3;
BA_ "U_U55X_MY2022_Tx" SG_ 710 BEZEL_RDISP_WORD_Tx 1;
BA_ "U_T6_MCA_MY2020_Tx" SG_ 710 BEZEL_RDISP_WORD_Tx 1;
BA_ "U_CD542_MY2021_Tx" SG_ 710 BEZEL_RDISP_WORD_Tx 1;
BA_ "GenSigSendType" SG_ 556 Manual_Temp_Setting 3;
BA_ "U_T6_MCA_MY2020_Tx" SG_ 556 EFP_Bezel_Diag_St 1;
BA_ "GenSigSendType" SG_ 556 EFP_Bezel_Diag_St 3;
BA_ "U_T6_MCA_MY2020_Tx" SG_ 556 Bezel_Beep_St 1;
BA_ "GenSigSendType" SG_ 556 Bezel_Beep_St 3;
BA_ "U_T6_MCA_MY2020_Tx" SG_ 556 Bezel_Beeps_Supported 1;
BA_ "GenSigSendType" SG_ 556 Bezel_Beeps_Supported 3;
BA_ "U_U55X_MY2022_Tx" SG_ 556 PassRstrnInd_Stat 1;
BA_ "U_CD542_MY2021_Tx" SG_ 556 PassRstrnInd_Stat 1;
BA_ "U_T6_MCA_MY2020_Tx" SG_ 556 PassRstrnInd_Stat 1;
BA_ "GenSigSendType" SG_ 556 PassRstrnInd_Stat 3;
BA_ "GenSigSendType" SG_ 1815 TesterPhysicalReqRLCMA 3;
BA_ "GenSigStartValue" SG_ 1433 DCMF_GWOnBoardTester 255;
BA_ "ContentDependant" SG_ 1433 DCMF_GWOnBoardTester 1;
BA_ "GenSigStartValueInteger" SG_ 1433 DCMF_GWOnBoardTester 255;
BA_ "GenSigStartValue" SG_ 1433 DCMF_GWNMProxY 255;
BA_ "ContentDependant" SG_ 1433 DCMF_GWNMProxY 1;
BA_ "GenSigStartValueInteger" SG_ 1433 DCMF_GWNMProxY 255;
BA_ "GenSigStartValue" SG_ 1433 DCMF_AutoSarNMReserved4 255;
BA_ "ContentDependant" SG_ 1433 DCMF_AutoSarNMReserved4 1;
BA_ "GenSigStartValueInteger" SG_ 1433 DCMF_AutoSarNMReserved4 255;
BA_ "GenSigStartValue" SG_ 1433 DCMF_AutoSarNMReserved3 255;
BA_ "ContentDependant" SG_ 1433 DCMF_AutoSarNMReserved3 1;
BA_ "GenSigStartValueInteger" SG_ 1433 DCMF_AutoSarNMReserved3 255;
BA_ "GenSigStartValue" SG_ 1433 DCMF_AutoSarNMReserved2 255;
BA_ "ContentDependant" SG_ 1433 DCMF_AutoSarNMReserved2 1;
BA_ "GenSigStartValueInteger" SG_ 1433 DCMF_AutoSarNMReserved2 255;
BA_ "GenSigStartValue" SG_ 1433 DCMF_AutoSarNMReserved 255;
BA_ "ContentDependant" SG_ 1433 DCMF_AutoSarNMReserved 1;
BA_ "GenSigStartValueInteger" SG_ 1433 DCMF_AutoSarNMReserved 255;
BA_ "GenSigStartValue" SG_ 1433 DCMF_AutoSarNMNodeId 153;
BA_ "ContentDependant" SG_ 1433 DCMF_AutoSarNMNodeId 1;
BA_ "GenSigStartValueInteger" SG_ 1433 DCMF_AutoSarNMNodeId 153;
BA_ "ContentDependant" SG_ 1433 DCMF_AutoSarNMControl 1;
BA_ "U_U55X_MY2022_Tx" SG_ 1983 TesterPhysicalResBCMB 1;
BA_ "GenSigSendType" SG_ 1983 TesterPhysicalResBCMB 3;
BA_ "U_U55X_MY2022_Rx" SG_ 1975 TesterPhysicalReqBCMB 1;
BA_ "GenSigSendType" SG_ 1975 TesterPhysicalReqBCMB 3;
BA_ "GenSigStartValueInteger" SG_ 359 PrplWhlRgenMn_Tq_Actl 4095;
BA_ "ContentDependant" SG_ 359 TrnAin_Tq_Actl 1;
BA_ "MetaData" SG_ 359 TrnAinTq_D_Qf 1;
BA_ "ContentDependant" SG_ 359 TrnAinTq_D_Qf 1;
BA_ "U_CD764_MY2022_Rx" SG_ 359 PwPckTq_D_Stat 1;
BA_ "U_U55X_MY2022_Rx" SG_ 359 PwPckTq_D_Stat 1;
BA_ "U_CD542_MY2021_Rx" SG_ 359 PwPckTq_D_Stat 1;
BA_ "U_T6_MCA_MY2020_Rx" SG_ 359 PwPckTq_D_Stat 1;
BA_ "U_P702_MY2021_Rx" SG_ 359 PwPckTq_D_Stat 1;
BA_ "U_CX727_MY2021_Rx" SG_ 359 PwPckTq_D_Stat 1;
BA_ "GenSigSendType" SG_ 359 PwPckTq_D_Stat 3;
BA_ "U_CD764_MY2022_Rx" SG_ 359 Eng_D_Stat 1;
BA_ "U_U55X_MY2022_Rx" SG_ 359 Eng_D_Stat 1;
BA_ "U_CD542_MY2021_Rx" SG_ 359 Eng_D_Stat 1;
BA_ "U_T6_MCA_MY2020_Rx" SG_ 359 Eng_D_Stat 1;
BA_ "U_P702_MY2021_Rx" SG_ 359 Eng_D_Stat 1;
BA_ "U_CX727_MY2021_Rx" SG_ 359 Eng_D_Stat 1;
BA_ "GenSigSendType" SG_ 359 Eng_D_Stat 3;
BA_ "GenSigStartValue" SG_ 359 PlgActvArb_B_Actl 1;
BA_ "ContentDependant" SG_ 359 PlgActvArb_B_Actl 1;
BA_ "GenSigStartValueInteger" SG_ 359 PlgActvArb_B_Actl 1;
BA_ "U_CD764_MY2022_Rx" SG_ 359 ElPw_D_Stat 1;
BA_ "U_CD542_MY2021_Rx" SG_ 359 ElPw_D_Stat 1;
BA_ "U_T6_MCA_MY2020_Rx" SG_ 359 ElPw_D_Stat 1;
BA_ "U_P702_MY2021_Rx" SG_ 359 ElPw_D_Stat 1;
BA_ "U_CX727_MY2021_Rx" SG_ 359 ElPw_D_Stat 1;
BA_ "U_U55X_MY2022_Rx" SG_ 359 ElPw_D_Stat 1;
BA_ "GenSigSendType" SG_ 359 ElPw_D_Stat 3;
BA_ "U_CD764_MY2022_Rx" SG_ 131 VehOnSrc_D_Stat_UB 1;
BA_ "U_U55X_MY2022_Rx" SG_ 131 VehOnSrc_D_Stat_UB 1;
BA_ "U_CD542_MY2021_Rx" SG_ 131 VehOnSrc_D_Stat_UB 1;
BA_ "U_T6_MCA_MY2020_Rx" SG_ 131 VehOnSrc_D_Stat_UB 1;
BA_ "U_CD764_MY2022_Rx" SG_ 131 VehOnSrc_D_Stat 1;
BA_ "U_U55X_MY2022_Rx" SG_ 131 VehOnSrc_D_Stat 1;
BA_ "U_CD542_MY2021_Rx" SG_ 131 VehOnSrc_D_Stat 1;
BA_ "U_T6_MCA_MY2020_Rx" SG_ 131 VehOnSrc_D_Stat 1;
BA_ "U_T6_MCA_MY2020_Rx" SG_ 131 StePinCompAnEst_D_Qf 1;
BA_ "U_CX727_MY2021_Rx" SG_ 131 StePinCompAnEst_D_Qf 1;
BA_ "GenSigStartValue" SG_ 131 StePinCompAnEst_D_Qf 1;
BA_ "MetaData" SG_ 131 StePinCompAnEst_D_Qf 1;
BA_ "GenSigStartValueInteger" SG_ 131 StePinCompAnEst_D_Qf 1;
BA_ "U_T6_MCA_MY2020_Rx" SG_ 131 StePinComp_An_Est_UB 1;
BA_ "U_CX727_MY2021_Rx" SG_ 131 StePinComp_An_Est_UB 1;
BA_ "U_T6_MCA_MY2020_Rx" SG_ 131 StePinComp_An_Est 1;
BA_ "U_CX727_MY2021_Rx" SG_ 131 StePinComp_An_Est 1;
BA_ "GenSigStartValueInteger" SG_ 131 StePinComp_An_Est 16000;
BA_ "U_U55X_MY2022_Rx" SG_ 131 VehLongComp_A_Actl_UB 1;
BA_ "U_CD542_MY2021_Rx" SG_ 131 VehLongComp_A_Actl_UB 1;
BA_ "U_T6_MCA_MY2020_Rx" SG_ 131 VehLongComp_A_Actl_UB 1;
BA_ "U_CX727_MY2021_Rx" SG_ 131 VehLongComp_A_Actl_UB 1;
BA_ "U_U55X_MY2022_Rx" SG_ 131 VehLatComp_A_Actl_UB 1;
BA_ "U_CD542_MY2021_Rx" SG_ 131 VehLatComp_A_Actl_UB 1;
BA_ "U_T6_MCA_MY2020_Rx" SG_ 131 VehLatComp_A_Actl_UB 1;
BA_ "U_CX727_MY2021_Rx" SG_ 131 VehLatComp_A_Actl_UB 1;
BA_ "U_U55X_MY2022_Rx" SG_ 131 VehLongComp_A_Actl 1;
BA_ "U_CD542_MY2021_Rx" SG_ 131 VehLongComp_A_Actl 1;
BA_ "U_T6_MCA_MY2020_Rx" SG_ 131 VehLongComp_A_Actl 1;
BA_ "U_CX727_MY2021_Rx" SG_ 131 VehLongComp_A_Actl 1;
BA_ "GenSigStartValue" SG_ 131 VehLongComp_A_Actl 1022;
BA_ "GenSigStartValueInteger" SG_ 131 VehLongComp_A_Actl 1022;
BA_ "U_U55X_MY2022_Rx" SG_ 131 VehLatComp_A_Actl 1;
BA_ "U_CD542_MY2021_Rx" SG_ 131 VehLatComp_A_Actl 1;
BA_ "U_T6_MCA_MY2020_Rx" SG_ 131 VehLatComp_A_Actl 1;
BA_ "U_CX727_MY2021_Rx" SG_ 131 VehLatComp_A_Actl 1;
BA_ "GenSigStartValue" SG_ 131 VehLatComp_A_Actl 1022;
BA_ "GenSigStartValueInteger" SG_ 131 VehLatComp_A_Actl 1022;
BA_ "U_T6_MCA_MY2020_Rx" SG_ 131 VehYaw_W_Actl_UB 1;
BA_ "U_CX727_MY2021_Rx" SG_ 131 VehYaw_W_Actl_UB 1;
BA_ "U_T6_MCA_MY2020_Rx" SG_ 131 VehYaw_W_Actl 1;
BA_ "U_CX727_MY2021_Rx" SG_ 131 VehYaw_W_Actl 1;
BA_ "GenSigStartValue" SG_ 131 VehYaw_W_Actl 65534;
BA_ "GenSigStartValueInteger" SG_ 131 VehYaw_W_Actl 65534;
BA_ "U_CD764_MY2022_Tx" SG_ 990 PersIndexDdm_D_Actl 1;
BA_ "U_U55X_MY2022_Tx" SG_ 990 PersIndexDdm_D_Actl 1;
BA_ "U_CD542_MY2021_Tx" SG_ 990 PersIndexDdm_D_Actl 1;
BA_ "U_T6_MCA_MY2020_Tx" SG_ 990 PersIndexDdm_D_Actl 1;
BA_ "U_P702_MY2021_Tx" SG_ 990 PersIndexDdm_D_Actl 1;
BA_ "U_CX727_MY2021_Tx" SG_ 990 PersIndexDdm_D_Actl 1;
BA_ "GenSigSendType" SG_ 990 PersIndexDdm_D_Actl 3;
BA_ "GenSigStartValue" SG_ 990 PersIndexDdm_D_Actl 4;
BA_ "GenSigStartValueInteger" SG_ 990 PersIndexDdm_D_Actl 4;
BA_ "U_CD764_MY2022_Tx" SG_ 990 FeatNoDdm_No_Actl 1;
BA_ "U_U55X_MY2022_Tx" SG_ 990 FeatNoDdm_No_Actl 1;
BA_ "U_CD542_MY2021_Tx" SG_ 990 FeatNoDdm_No_Actl 1;
BA_ "U_T6_MCA_MY2020_Tx" SG_ 990 FeatNoDdm_No_Actl 1;
BA_ "U_P702_MY2021_Tx" SG_ 990 FeatNoDdm_No_Actl 1;
BA_ "U_CX727_MY2021_Tx" SG_ 990 FeatNoDdm_No_Actl 1;
BA_ "GenSigSendType" SG_ 990 FeatNoDdm_No_Actl 3;
BA_ "U_CD764_MY2022_Tx" SG_ 990 FeatConfigDdmActl 1;
BA_ "U_U55X_MY2022_Tx" SG_ 990 FeatConfigDdmActl 1;
BA_ "U_CD542_MY2021_Tx" SG_ 990 FeatConfigDdmActl 1;
BA_ "U_T6_MCA_MY2020_Tx" SG_ 990 FeatConfigDdmActl 1;
BA_ "U_P702_MY2021_Tx" SG_ 990 FeatConfigDdmActl 1;
BA_ "U_CX727_MY2021_Tx" SG_ 990 FeatConfigDdmActl 1;
BA_ "GenSigSendType" SG_ 990 FeatConfigDdmActl 3;
BA_ "MetaData" SG_ 1246 TrlrBrkCtl2BFalt_No_Cs 1;
BA_ "MetaData" SG_ 1246 TrlrBrkCtl2BFalt_No_Cnt 1;
BA_ "GenSigSendType" SG_ 1246 TrlrBrkCtl2_B_Falt 3;
BA_ "GenSigSendType" SG_ 1363 MRCMA_Network_Mgmt 3;
BA_ "U_U55X_MY2022_Tx" SG_ 1899 TesterPhysicalResSCMD 1;
BA_ "GenSigSendType" SG_ 1899 TesterPhysicalResSCMD 3;
BA_ "U_CD764_MY2022_Rx" SG_ 1003 PersRecallSrc_D_Actl 1;
BA_ "U_CD542_MY2021_Rx" SG_ 1003 PersRecallSrc_D_Actl 1;
BA_ "U_T6_MCA_MY2020_Rx" SG_ 1003 PersRecallSrc_D_Actl 1;
BA_ "U_P702_MY2021_Rx" SG_ 1003 PersRecallSrc_D_Actl 1;
BA_ "U_CX727_MY2021_Rx" SG_ 1003 PersRecallSrc_D_Actl 1;
BA_ "U_U55X_MY2022_Rx" SG_ 1003 PersRecallSrc_D_Actl 1;
BA_ "U_CD764_MY2022_Rx" SG_ 1003 PersSetupRestr_D_Actl 1;
BA_ "U_U55X_MY2022_Rx" SG_ 1003 PersSetupRestr_D_Actl 1;
BA_ "U_CD542_MY2021_Rx" SG_ 1003 PersSetupRestr_D_Actl 1;
BA_ "U_T6_MCA_MY2020_Rx" SG_ 1003 PersSetupRestr_D_Actl 1;
BA_ "U_P702_MY2021_Rx" SG_ 1003 PersSetupRestr_D_Actl 1;
BA_ "U_CX727_MY2021_Rx" SG_ 1003 PersSetupRestr_D_Actl 1;
BA_ "U_CD764_MY2022_Rx" SG_ 1003 PersSetupAccessCtrl 1;
BA_ "U_U55X_MY2022_Rx" SG_ 1003 PersSetupAccessCtrl 1;
BA_ "U_CD542_MY2021_Rx" SG_ 1003 PersSetupAccessCtrl 1;
BA_ "U_T6_MCA_MY2020_Rx" SG_ 1003 PersSetupAccessCtrl 1;
BA_ "U_P702_MY2021_Rx" SG_ 1003 PersSetupAccessCtrl 1;
BA_ "U_CX727_MY2021_Rx" SG_ 1003 PersSetupAccessCtrl 1;
BA_ "U_CD764_MY2022_Rx" SG_ 1003 PersSetup_No_Actl 1;
BA_ "U_U55X_MY2022_Rx" SG_ 1003 PersSetup_No_Actl 1;
BA_ "U_CD542_MY2021_Rx" SG_ 1003 PersSetup_No_Actl 1;
BA_ "U_T6_MCA_MY2020_Rx" SG_ 1003 PersSetup_No_Actl 1;
BA_ "U_P702_MY2021_Rx" SG_ 1003 PersSetup_No_Actl 1;
BA_ "U_CX727_MY2021_Rx" SG_ 1003 PersSetup_No_Actl 1;
BA_ "GenSigStartValue" SG_ 1003 PersConflict_D_Actl 1;
BA_ "GenSigStartValueInteger" SG_ 1003 PersConflict_D_Actl 1;
BA_ "U_CD764_MY2022_Rx" SG_ 1003 RecallEvent_No_Cnt 1;
BA_ "U_U55X_MY2022_Rx" SG_ 1003 RecallEvent_No_Cnt 1;
BA_ "U_CD542_MY2021_Rx" SG_ 1003 RecallEvent_No_Cnt 1;
BA_ "U_T6_MCA_MY2020_Rx" SG_ 1003 RecallEvent_No_Cnt 1;
BA_ "U_P702_MY2021_Rx" SG_ 1003 RecallEvent_No_Cnt 1;
BA_ "U_CX727_MY2021_Rx" SG_ 1003 RecallEvent_No_Cnt 1;
BA_ "MetaData" SG_ 1003 RecallEvent_No_Cnt 1;
BA_ "U_CD542_MY2021_Rx" SG_ 1003 PersNo_D_Actl 1;
BA_ "U_T6_MCA_MY2020_Rx" SG_ 1003 PersNo_D_Actl 1;
BA_ "U_CX727_MY2021_Rx" SG_ 1003 PersNo_D_Actl 1;
BA_ "U_CD764_MY2022_Rx" SG_ 1003 PersNo_D_Actl 1;
BA_ "U_U55X_MY2022_Rx" SG_ 1003 PersNo_D_Actl 1;
BA_ "U_P702_MY2021_Rx" SG_ 1003 PersNo_D_Actl 1;
BA_ "GenSigStartValue" SG_ 1003 PersNo_D_Actl 4;
BA_ "GenSigStartValueInteger" SG_ 1003 PersNo_D_Actl 4;
BA_ "U_CD764_MY2022_Rx" SG_ 1003 PersNoPos_D_Actl 1;
BA_ "U_CD542_MY2021_Rx" SG_ 1003 PersNoPos_D_Actl 1;
BA_ "U_T6_MCA_MY2020_Rx" SG_ 1003 PersNoPos_D_Actl 1;
BA_ "U_P702_MY2021_Rx" SG_ 1003 PersNoPos_D_Actl 1;
BA_ "U_CX727_MY2021_Rx" SG_ 1003 PersNoPos_D_Actl 1;
BA_ "GenSigStartValue" SG_ 1003 PersNoPos_D_Actl 4;
BA_ "GenSigStartValueInteger" SG_ 1003 PersNoPos_D_Actl 4;
BA_ "U_CD542_MY2021_Tx" SG_ 1945 TesterPhysicalResTRM 1;
BA_ "U_T6_MCA_MY2020_Tx" SG_ 1945 TesterPhysicalResTRM 1;
BA_ "U_P702_MY2021_Tx" SG_ 1945 TesterPhysicalResTRM 1;
BA_ "GenSigSendType" SG_ 1945 TesterPhysicalResTRM 3;
BA_ "ContentDependant" SG_ 836 FohFalt_D_Stat 1;
BA_ "ContentDependant" SG_ 836 FohEnbl_B_RqDrv 1;
BA_ "ContentDependant" SG_ 836 FohRqRun_B_Rq 1;
BA_ "U_CD764_MY2022_Rx" SG_ 836 HvacPrecondMode_D_Rq 1;
BA_ "U_CX727_MY2021_Rx" SG_ 836 HvacPrecondMode_D_Rq 1;
BA_ "ContentDependant" SG_ 836 HvacPrecondMode_D_Rq 1;
BA_ "WakeupSignal" SG_ 836 HvacPrecondMode_D_Rq 1;
BA_ "U_CD764_MY2022_Rx" SG_ 836 HvacPrecondBlwr_D_Rq 1;
BA_ "U_CX727_MY2021_Rx" SG_ 836 HvacPrecondBlwr_D_Rq 1;
BA_ "ContentDependant" SG_ 836 HvacPrecondBlwr_D_Rq 1;
BA_ "WakeupSignal" SG_ 836 HvacPrecondBlwr_D_Rq 1;
BA_ "U_CD764_MY2022_Rx" SG_ 836 Foh_D_Stat 1;
BA_ "U_CX727_MY2021_Rx" SG_ 836 Foh_D_Stat 1;
BA_ "ContentDependant" SG_ 836 Foh_D_Stat 1;
BA_ "WakeupSignal" SG_ 836 Foh_D_Stat 1;
BA_ "ContentDependant" SG_ 836 FuelFlw_Vl_ActlFoh 1;
BA_ "U_CD764_MY2022_Rx" SG_ 836 EngClnt_Te_ActlFoh 1;
BA_ "U_CX727_MY2021_Rx" SG_ 836 EngClnt_Te_ActlFoh 1;
BA_ "ContentDependant" SG_ 836 EngClnt_Te_ActlFoh 1;
BA_ "GenSigSendType" SG_ 819 WndwUpPsngrRear_D_Falt 3;
BA_ "GenSigSendType" SG_ 819 WndwUpPsngrFront_D_Falt 3;
BA_ "U_CD764_MY2022_Tx" SG_ 819 DrPrsntPsngr_D_Stat 1;
BA_ "U_T6_MCA_MY2020_Tx" SG_ 819 DrPrsntPsngr_D_Stat 1;
BA_ "U_CD764_MY2022_Rx" SG_ 819 DrPrsntPsngr_D_Stat 1;
BA_ "ECGUsedRxSignal" SG_ 819 DrPrsntPsngr_D_Stat 1;
BA_ "GenSigSendType" SG_ 819 DrPrsntPsngr_D_Stat 3;
BA_ "WakeupSignal" SG_ 819 DrPrsntPsngr_D_Stat 1;
BA_ "U_CD764_MY2022_Tx" SG_ 819 DrPsngrMsgTxt_B_Rq 1;
BA_ "U_T6_MCA_MY2020_Tx" SG_ 819 DrPsngrMsgTxt_B_Rq 1;
BA_ "GenSigSendType" SG_ 819 DrPsngrMsgTxt_B_Rq 3;
BA_ "U_CD764_MY2022_Tx" SG_ 819 DrPrsntRearPsngr_D_Stat 1;
BA_ "U_T6_MCA_MY2020_Tx" SG_ 819 DrPrsntRearPsngr_D_Stat 1;
BA_ "U_CD764_MY2022_Rx" SG_ 819 DrPrsntRearPsngr_D_Stat 1;
BA_ "ECGUsedRxSignal" SG_ 819 DrPrsntRearPsngr_D_Stat 1;
BA_ "GenSigSendType" SG_ 819 DrPrsntRearPsngr_D_Stat 3;
BA_ "WakeupSignal" SG_ 819 DrPrsntRearPsngr_D_Stat 1;
BA_ "U_CD764_MY2022_Tx" SG_ 819 RollCode_No_ActlPdm 1;
BA_ "U_U55X_MY2022_Tx" SG_ 819 RollCode_No_ActlPdm 1;
BA_ "U_CD542_MY2021_Tx" SG_ 819 RollCode_No_ActlPdm 1;
BA_ "U_T6_MCA_MY2020_Tx" SG_ 819 RollCode_No_ActlPdm 1;
BA_ "U_P702_MY2021_Tx" SG_ 819 RollCode_No_ActlPdm 1;
BA_ "U_CD764_MY2022_Tx" SG_ 819 Memory_3_SwPsngr_Stat 1;
BA_ "U_U55X_MY2022_Tx" SG_ 819 Memory_3_SwPsngr_Stat 1;
BA_ "U_T6_MCA_MY2020_Tx" SG_ 819 Memory_3_SwPsngr_Stat 1;
BA_ "U_P702_MY2021_Tx" SG_ 819 Memory_3_SwPsngr_Stat 1;
BA_ "U_U55X_MY2022_Rx" SG_ 819 Memory_3_SwPsngr_Stat 1;
BA_ "GenSigSendType" SG_ 819 Memory_3_SwPsngr_Stat 3;
BA_ "WakeupSignal" SG_ 819 Memory_3_SwPsngr_Stat 1;
BA_ "U_CD764_MY2022_Tx" SG_ 819 Memory_2_SwPsngr_Stat 1;
BA_ "U_U55X_MY2022_Tx" SG_ 819 Memory_2_SwPsngr_Stat 1;
BA_ "U_T6_MCA_MY2020_Tx" SG_ 819 Memory_2_SwPsngr_Stat 1;
BA_ "U_P702_MY2021_Tx" SG_ 819 Memory_2_SwPsngr_Stat 1;
BA_ "U_U55X_MY2022_Rx" SG_ 819 Memory_2_SwPsngr_Stat 1;
BA_ "GenSigSendType" SG_ 819 Memory_2_SwPsngr_Stat 3;
BA_ "WakeupSignal" SG_ 819 Memory_2_SwPsngr_Stat 1;
BA_ "U_CD764_MY2022_Tx" SG_ 819 Memory_1_SwPsngr_Stat 1;
BA_ "U_U55X_MY2022_Tx" SG_ 819 Memory_1_SwPsngr_Stat 1;
BA_ "U_T6_MCA_MY2020_Tx" SG_ 819 Memory_1_SwPsngr_Stat 1;
BA_ "U_P702_MY2021_Tx" SG_ 819 Memory_1_SwPsngr_Stat 1;
BA_ "U_U55X_MY2022_Rx" SG_ 819 Memory_1_SwPsngr_Stat 1;
BA_ "GenSigSendType" SG_ 819 Memory_1_SwPsngr_Stat 3;
BA_ "WakeupSignal" SG_ 819 Memory_1_SwPsngr_Stat 1;
BA_ "U_CD764_MY2022_Tx" SG_ 819 BLISLEDStatPassSide 1;
BA_ "U_U55X_MY2022_Tx" SG_ 819 BLISLEDStatPassSide 1;
BA_ "U_CD542_MY2021_Tx" SG_ 819 BLISLEDStatPassSide 1;
BA_ "U_T6_MCA_MY2020_Tx" SG_ 819 BLISLEDStatPassSide 1;
BA_ "U_P702_MY2021_Tx" SG_ 819 BLISLEDStatPassSide 1;
BA_ "U_T6_MCA_MY2020_Rx" SG_ 819 BLISLEDStatPassSide 1;
BA_ "U_CX727_MY2021_Rx" SG_ 819 BLISLEDStatPassSide 1;
BA_ "GenSigSendType" SG_ 819 BLISLEDStatPassSide 3;
BA_ "U_CD764_MY2022_Tx" SG_ 819 WndwPsngrSide_D_Stat 1;
BA_ "U_U55X_MY2022_Tx" SG_ 819 WndwPsngrSide_D_Stat 1;
BA_ "U_CD542_MY2021_Tx" SG_ 819 WndwPsngrSide_D_Stat 1;
BA_ "U_T6_MCA_MY2020_Tx" SG_ 819 WndwPsngrSide_D_Stat 1;
BA_ "U_P702_MY2021_Tx" SG_ 819 WndwPsngrSide_D_Stat 1;
BA_ "GenSigSendType" SG_ 819 WndwPsngrSide_D_Stat 3;
BA_ "U_CD764_MY2022_Tx" SG_ 819 Pasngr_Lock_Sw_Stat 1;
BA_ "U_U55X_MY2022_Tx" SG_ 819 Pasngr_Lock_Sw_Stat 1;
BA_ "U_CD542_MY2021_Tx" SG_ 819 Pasngr_Lock_Sw_Stat 1;
BA_ "U_T6_MCA_MY2020_Tx" SG_ 819 Pasngr_Lock_Sw_Stat 1;
BA_ "U_P702_MY2021_Tx" SG_ 819 Pasngr_Lock_Sw_Stat 1;
BA_ "GenSigSendType" SG_ 819 Pasngr_Lock_Sw_Stat 3;
BA_ "WakeupSignal" SG_ 819 Pasngr_Lock_Sw_Stat 1;
BA_ "U_CD764_MY2022_Tx" SG_ 819 Pasngr_Lock_Sw_Cnt 1;
BA_ "U_U55X_MY2022_Tx" SG_ 819 Pasngr_Lock_Sw_Cnt 1;
BA_ "U_CD542_MY2021_Tx" SG_ 819 Pasngr_Lock_Sw_Cnt 1;
BA_ "U_T6_MCA_MY2020_Tx" SG_ 819 Pasngr_Lock_Sw_Cnt 1;
BA_ "U_P702_MY2021_Tx" SG_ 819 Pasngr_Lock_Sw_Cnt 1;
BA_ "GenSigSendType" SG_ 819 Pasngr_Lock_Sw_Cnt 3;
BA_ "MetaData" SG_ 819 Pasngr_Lock_Sw_Cnt 1;
BA_ "WakeupSignal" SG_ 819 Pasngr_Lock_Sw_Cnt 1;
BA_ "U_CD764_MY2022_Tx" SG_ 819 ChildLckFdbckRp_B_Stat 1;
BA_ "U_U55X_MY2022_Tx" SG_ 819 ChildLckFdbckRp_B_Stat 1;
BA_ "U_CD542_MY2021_Tx" SG_ 819 ChildLckFdbckRp_B_Stat 1;
BA_ "U_T6_MCA_MY2020_Tx" SG_ 819 ChildLckFdbckRp_B_Stat 1;
BA_ "U_P702_MY2021_Tx" SG_ 819 ChildLckFdbckRp_B_Stat 1;
BA_ "GenSigSendType" SG_ 819 ChildLckFdbckRp_B_Stat 3;
BA_ "WakeupSignal" SG_ 819 ChildLckFdbckRp_B_Stat 1;
BA_ "GenSigSendType" SG_ 818 WndwUpDrvRear_D_Falt 3;
BA_ "GenSigSendType" SG_ 818 WndwUpDrvFront_D_Falt 3;
BA_ "U_CD764_MY2022_Tx" SG_ 818 DrvSpotLight_B_Stat 1;
BA_ "U_T6_MCA_MY2020_Tx" SG_ 818 DrvSpotLight_B_Stat 1;
BA_ "U_CD764_MY2022_Rx" SG_ 818 DrvSpotLight_B_Stat 1;
BA_ "U_T6_MCA_MY2020_Rx" SG_ 818 DrvSpotLight_B_Stat 1;
BA_ "GenSigSendType" SG_ 818 DrvSpotLight_B_Stat 3;
BA_ "U_CD764_MY2022_Tx" SG_ 818 DrPrsntDrv_D_Stat 1;
BA_ "U_T6_MCA_MY2020_Tx" SG_ 818 DrPrsntDrv_D_Stat 1;
BA_ "U_CD764_MY2022_Rx" SG_ 818 DrPrsntDrv_D_Stat 1;
BA_ "ECGUsedRxSignal" SG_ 818 DrPrsntDrv_D_Stat 1;
BA_ "GenSigSendType" SG_ 818 DrPrsntDrv_D_Stat 3;
BA_ "WakeupSignal" SG_ 818 DrPrsntDrv_D_Stat 1;
BA_ "U_CD764_MY2022_Tx" SG_ 818 DrPrsntRearDrv_D_Stat 1;
BA_ "U_T6_MCA_MY2020_Tx" SG_ 818 DrPrsntRearDrv_D_Stat 1;
BA_ "U_CD764_MY2022_Rx" SG_ 818 DrPrsntRearDrv_D_Stat 1;
BA_ "ECGUsedRxSignal" SG_ 818 DrPrsntRearDrv_D_Stat 1;
BA_ "GenSigSendType" SG_ 818 DrPrsntRearDrv_D_Stat 3;
BA_ "WakeupSignal" SG_ 818 DrPrsntRearDrv_D_Stat 1;
BA_ "U_CD764_MY2022_Tx" SG_ 818 DrDrvMsgTxt_B_Rq 1;
BA_ "U_T6_MCA_MY2020_Tx" SG_ 818 DrDrvMsgTxt_B_Rq 1;
BA_ "GenSigSendType" SG_ 818 DrDrvMsgTxt_B_Rq 3;
BA_ "U_CD764_MY2022_Tx" SG_ 818 BLISLEDStatDriverSide 1;
BA_ "U_U55X_MY2022_Tx" SG_ 818 BLISLEDStatDriverSide 1;
BA_ "U_CD542_MY2021_Tx" SG_ 818 BLISLEDStatDriverSide 1;
BA_ "U_T6_MCA_MY2020_Tx" SG_ 818 BLISLEDStatDriverSide 1;
BA_ "U_P702_MY2021_Tx" SG_ 818 BLISLEDStatDriverSide 1;
BA_ "U_CX727_MY2021_Tx" SG_ 818 BLISLEDStatDriverSide 1;
BA_ "U_T6_MCA_MY2020_Rx" SG_ 818 BLISLEDStatDriverSide 1;
BA_ "U_CX727_MY2021_Rx" SG_ 818 BLISLEDStatDriverSide 1;
BA_ "GenSigSendType" SG_ 818 BLISLEDStatDriverSide 3;
BA_ "U_CD764_MY2022_Tx" SG_ 818 ChildLckPw_N_Cnt 1;
BA_ "U_U55X_MY2022_Tx" SG_ 818 ChildLckPw_N_Cnt 1;
BA_ "U_CD542_MY2021_Tx" SG_ 818 ChildLckPw_N_Cnt 1;
BA_ "U_T6_MCA_MY2020_Tx" SG_ 818 ChildLckPw_N_Cnt 1;
BA_ "U_P702_MY2021_Tx" SG_ 818 ChildLckPw_N_Cnt 1;
BA_ "U_CX727_MY2021_Tx" SG_ 818 ChildLckPw_N_Cnt 1;
BA_ "GenSigSendType" SG_ 818 ChildLckPw_N_Cnt 3;
BA_ "WakeupSignal" SG_ 818 ChildLckPw_N_Cnt 1;
BA_ "U_CD764_MY2022_Tx" SG_ 818 WndwDrvSide_D_Stat 1;
BA_ "U_U55X_MY2022_Tx" SG_ 818 WndwDrvSide_D_Stat 1;
BA_ "U_CD542_MY2021_Tx" SG_ 818 WndwDrvSide_D_Stat 1;
BA_ "U_T6_MCA_MY2020_Tx" SG_ 818 WndwDrvSide_D_Stat 1;
BA_ "U_P702_MY2021_Tx" SG_ 818 WndwDrvSide_D_Stat 1;
BA_ "U_CX727_MY2021_Tx" SG_ 818 WndwDrvSide_D_Stat 1;
BA_ "GenSigSendType" SG_ 818 WndwDrvSide_D_Stat 3;
BA_ "U_CD764_MY2022_Tx" SG_ 818 RollCodeDrvDrKeyCyl 1;
BA_ "U_U55X_MY2022_Tx" SG_ 818 RollCodeDrvDrKeyCyl 1;
BA_ "U_CD542_MY2021_Tx" SG_ 818 RollCodeDrvDrKeyCyl 1;
BA_ "U_T6_MCA_MY2020_Tx" SG_ 818 RollCodeDrvDrKeyCyl 1;
BA_ "U_P702_MY2021_Tx" SG_ 818 RollCodeDrvDrKeyCyl 1;
BA_ "U_CX727_MY2021_Tx" SG_ 818 RollCodeDrvDrKeyCyl 1;
BA_ "GenSigSendType" SG_ 818 RollCodeDrvDrKeyCyl 3;
BA_ "U_CD764_MY2022_Tx" SG_ 818 KeyCylSwDrvDr_D_Stat 1;
BA_ "U_U55X_MY2022_Tx" SG_ 818 KeyCylSwDrvDr_D_Stat 1;
BA_ "U_CD542_MY2021_Tx" SG_ 818 KeyCylSwDrvDr_D_Stat 1;
BA_ "U_T6_MCA_MY2020_Tx" SG_ 818 KeyCylSwDrvDr_D_Stat 1;
BA_ "U_P702_MY2021_Tx" SG_ 818 KeyCylSwDrvDr_D_Stat 1;
BA_ "U_CX727_MY2021_Tx" SG_ 818 KeyCylSwDrvDr_D_Stat 1;
BA_ "GenSigSendType" SG_ 818 KeyCylSwDrvDr_D_Stat 3;
BA_ "WakeupSignal" SG_ 818 KeyCylSwDrvDr_D_Stat 1;
BA_ "U_CD764_MY2022_Tx" SG_ 818 Driver_Lock_Sw_Stat 1;
BA_ "U_U55X_MY2022_Tx" SG_ 818 Driver_Lock_Sw_Stat 1;
BA_ "U_CD542_MY2021_Tx" SG_ 818 Driver_Lock_Sw_Stat 1;
BA_ "U_T6_MCA_MY2020_Tx" SG_ 818 Driver_Lock_Sw_Stat 1;
BA_ "U_P702_MY2021_Tx" SG_ 818 Driver_Lock_Sw_Stat 1;
BA_ "U_CX727_MY2021_Tx" SG_ 818 Driver_Lock_Sw_Stat 1;
BA_ "GenSigSendType" SG_ 818 Driver_Lock_Sw_Stat 3;
BA_ "WakeupSignal" SG_ 818 Driver_Lock_Sw_Stat 1;
BA_ "U_CD764_MY2022_Tx" SG_ 818 Driver_Lock_Sw_Cnt 1;
BA_ "U_U55X_MY2022_Tx" SG_ 818 Driver_Lock_Sw_Cnt 1;
BA_ "U_CD542_MY2021_Tx" SG_ 818 Driver_Lock_Sw_Cnt 1;
BA_ "U_T6_MCA_MY2020_Tx" SG_ 818 Driver_Lock_Sw_Cnt 1;
BA_ "U_P702_MY2021_Tx" SG_ 818 Driver_Lock_Sw_Cnt 1;
BA_ "U_CX727_MY2021_Tx" SG_ 818 Driver_Lock_Sw_Cnt 1;
BA_ "GenSigSendType" SG_ 818 Driver_Lock_Sw_Cnt 3;
BA_ "MetaData" SG_ 818 Driver_Lock_Sw_Cnt 1;
BA_ "WakeupSignal" SG_ 818 Driver_Lock_Sw_Cnt 1;
BA_ "U_CD764_MY2022_Tx" SG_ 818 ChildLckPw_D_Rq 1;
BA_ "U_U55X_MY2022_Tx" SG_ 818 ChildLckPw_D_Rq 1;
BA_ "U_CD542_MY2021_Tx" SG_ 818 ChildLckPw_D_Rq 1;
BA_ "U_T6_MCA_MY2020_Tx" SG_ 818 ChildLckPw_D_Rq 1;
BA_ "U_P702_MY2021_Tx" SG_ 818 ChildLckPw_D_Rq 1;
BA_ "U_CX727_MY2021_Tx" SG_ 818 ChildLckPw_D_Rq 1;
BA_ "GenSigSendType" SG_ 818 ChildLckPw_D_Rq 3;
BA_ "WakeupSignal" SG_ 818 ChildLckPw_D_Rq 1;
BA_ "U_CD764_MY2022_Tx" SG_ 818 ChildLckFdbckRd_B_Stat 1;
BA_ "U_U55X_MY2022_Tx" SG_ 818 ChildLckFdbckRd_B_Stat 1;
BA_ "U_CD542_MY2021_Tx" SG_ 818 ChildLckFdbckRd_B_Stat 1;
BA_ "U_T6_MCA_MY2020_Tx" SG_ 818 ChildLckFdbckRd_B_Stat 1;
BA_ "U_P702_MY2021_Tx" SG_ 818 ChildLckFdbckRd_B_Stat 1;
BA_ "U_CX727_MY2021_Tx" SG_ 818 ChildLckFdbckRd_B_Stat 1;
BA_ "GenSigSendType" SG_ 818 ChildLckFdbckRd_B_Stat 3;
BA_ "WakeupSignal" SG_ 818 ChildLckFdbckRd_B_Stat 1;
BA_ "U_CD764_MY2022_Tx" SG_ 818 RvrseMirrorChime_B_Rq 1;
BA_ "U_U55X_MY2022_Tx" SG_ 818 RvrseMirrorChime_B_Rq 1;
BA_ "U_CD542_MY2021_Tx" SG_ 818 RvrseMirrorChime_B_Rq 1;
BA_ "U_T6_MCA_MY2020_Tx" SG_ 818 RvrseMirrorChime_B_Rq 1;
BA_ "U_P702_MY2021_Tx" SG_ 818 RvrseMirrorChime_B_Rq 1;
BA_ "U_CX727_MY2021_Tx" SG_ 818 RvrseMirrorChime_B_Rq 1;
BA_ "U_CD764_MY2022_Rx" SG_ 818 RvrseMirrorChime_B_Rq 1;
BA_ "U_U55X_MY2022_Rx" SG_ 818 RvrseMirrorChime_B_Rq 1;
BA_ "U_CD542_MY2021_Rx" SG_ 818 RvrseMirrorChime_B_Rq 1;
BA_ "U_T6_MCA_MY2020_Rx" SG_ 818 RvrseMirrorChime_B_Rq 1;
BA_ "U_P702_MY2021_Rx" SG_ 818 RvrseMirrorChime_B_Rq 1;
BA_ "U_CX727_MY2021_Rx" SG_ 818 RvrseMirrorChime_B_Rq 1;
BA_ "GenSigSendType" SG_ 818 RvrseMirrorChime_B_Rq 3;
BA_ "U_CX727_MY2021_Rx" SG_ 817 VehLckInd_D_Rq 1;
BA_ "U_CD764_MY2022_Rx" SG_ 817 VehLckInd_D_Rq 1;
BA_ "U_U55X_MY2022_Rx" SG_ 817 VehLckInd_D_Rq 1;
BA_ "U_CD542_MY2021_Rx" SG_ 817 VehLckInd_D_Rq 1;
BA_ "U_T6_MCA_MY2020_Rx" SG_ 817 VehLckInd_D_Rq 1;
BA_ "U_P702_MY2021_Rx" SG_ 817 VehLckInd_D_Rq 1;
BA_ "U_U55X_MY2022_Rx" SG_ 817 DrTgateOpen_B_Rq 1;
BA_ "U_CD542_MY2021_Rx" SG_ 817 DrTgateOpen_B_Rq 1;
BA_ "U_T6_MCA_MY2020_Rx" SG_ 817 DrTgateOpen_B_Rq 1;
BA_ "U_CX727_MY2021_Rx" SG_ 817 DrTgateOpen_B_Rq 1;
BA_ "WakeupSignal" SG_ 817 DrTgateOpen_B_Rq 1;
BA_ "U_U55X_MY2022_Rx" SG_ 817 DrTgateExtSwMde_B_Stat 1;
BA_ "U_CD542_MY2021_Rx" SG_ 817 DrTgateExtSwMde_B_Stat 1;
BA_ "U_T6_MCA_MY2020_Rx" SG_ 817 DrTgateExtSwMde_B_Stat 1;
BA_ "U_CX727_MY2021_Rx" SG_ 817 DrTgateExtSwMde_B_Stat 1;
BA_ "WakeupSignal" SG_ 817 DrTgateExtSwMde_B_Stat 1;
BA_ "U_U55X_MY2022_Rx" SG_ 817 Remote_Device_Feedback 1;
BA_ "U_T6_MCA_MY2020_Rx" SG_ 817 Remote_Device_Feedback 1;
BA_ "U_P702_MY2021_Rx" SG_ 817 Remote_Device_Feedback 1;
BA_ "U_CX727_MY2021_Rx" SG_ 817 Remote_Device_Feedback 1;
BA_ "WakeupSignal" SG_ 817 Remote_Device_Feedback 1;
BA_ "WakeupSignal" SG_ 817 R_Pwr_Sliding_Dr_Rqst 1;
BA_ "U_U55X_MY2022_Rx" SG_ 817 Power_Liftgate_Rqst 1;
BA_ "U_CD542_MY2021_Rx" SG_ 817 Power_Liftgate_Rqst 1;
BA_ "U_T6_MCA_MY2020_Rx" SG_ 817 Power_Liftgate_Rqst 1;
BA_ "U_CX727_MY2021_Rx" SG_ 817 Power_Liftgate_Rqst 1;
BA_ "WakeupSignal" SG_ 817 Power_Liftgate_Rqst 1;
BA_ "U_U55X_MY2022_Rx" SG_ 817 Power_Decklid_Rqst 1;
BA_ "U_CD542_MY2021_Rx" SG_ 817 Power_Decklid_Rqst 1;
BA_ "U_T6_MCA_MY2020_Rx" SG_ 817 Power_Decklid_Rqst 1;
BA_ "U_CX727_MY2021_Rx" SG_ 817 Power_Decklid_Rqst 1;
BA_ "WakeupSignal" SG_ 817 Power_Decklid_Rqst 1;
BA_ "WakeupSignal" SG_ 817 L_Pwr_Sliding_Dr_Rqst 1;
BA_ "U_U55X_MY2022_Rx" SG_ 817 Keyfob_Pad_Msg_Count 1;
BA_ "U_CD542_MY2021_Rx" SG_ 817 Keyfob_Pad_Msg_Count 1;
BA_ "U_T6_MCA_MY2020_Rx" SG_ 817 Keyfob_Pad_Msg_Count 1;
BA_ "U_CX727_MY2021_Rx" SG_ 817 Keyfob_Pad_Msg_Count 1;
BA_ "WakeupSignal" SG_ 817 Keyfob_Pad_Msg_Count 1;
BA_ "U_CX727_MY2021_Rx" SG_ 817 Veh_Lock_Requestor 1;
BA_ "U_CD764_MY2022_Rx" SG_ 817 Veh_Lock_Requestor 1;
BA_ "U_U55X_MY2022_Rx" SG_ 817 Veh_Lock_Requestor 1;
BA_ "U_CD542_MY2021_Rx" SG_ 817 Veh_Lock_Requestor 1;
BA_ "U_T6_MCA_MY2020_Rx" SG_ 817 Veh_Lock_Requestor 1;
BA_ "U_P702_MY2021_Rx" SG_ 817 Veh_Lock_Requestor 1;
BA_ "WakeupSignal" SG_ 817 Veh_Lock_Requestor 1;
BA_ "U_CX727_MY2021_Rx" SG_ 817 Veh_Lock_EvNum 1;
BA_ "U_CD764_MY2022_Rx" SG_ 817 Veh_Lock_EvNum 1;
BA_ "U_U55X_MY2022_Rx" SG_ 817 Veh_Lock_EvNum 1;
BA_ "U_CD542_MY2021_Rx" SG_ 817 Veh_Lock_EvNum 1;
BA_ "U_T6_MCA_MY2020_Rx" SG_ 817 Veh_Lock_EvNum 1;
BA_ "U_P702_MY2021_Rx" SG_ 817 Veh_Lock_EvNum 1;
BA_ "WakeupSignal" SG_ 817 Veh_Lock_EvNum 1;
BA_ "U_CX727_MY2021_Rx" SG_ 817 Veh_Lock_Sub_Id 1;
BA_ "U_CD764_MY2022_Rx" SG_ 817 Veh_Lock_Sub_Id 1;
BA_ "U_U55X_MY2022_Rx" SG_ 817 Veh_Lock_Sub_Id 1;
BA_ "U_CD542_MY2021_Rx" SG_ 817 Veh_Lock_Sub_Id 1;
BA_ "U_T6_MCA_MY2020_Rx" SG_ 817 Veh_Lock_Sub_Id 1;
BA_ "U_P702_MY2021_Rx" SG_ 817 Veh_Lock_Sub_Id 1;
BA_ "U_CD764_MY2022_Rx" SG_ 817 ChildLck_D_Dsply 1;
BA_ "U_U55X_MY2022_Rx" SG_ 817 ChildLck_D_Dsply 1;
BA_ "U_CD542_MY2021_Rx" SG_ 817 ChildLck_D_Dsply 1;
BA_ "U_T6_MCA_MY2020_Rx" SG_ 817 ChildLck_D_Dsply 1;
BA_ "U_P702_MY2021_Rx" SG_ 817 ChildLck_D_Dsply 1;
BA_ "U_CX727_MY2021_Rx" SG_ 817 ChildLck_D_Dsply 1;
BA_ "GenSigStartValue" SG_ 817 ChildLck_D_Dsply 1;
BA_ "GenSigStartValueInteger" SG_ 817 ChildLck_D_Dsply 1;
BA_ "WakeupSignal" SG_ 817 ChildLck_D_Dsply 1;
BA_ "U_CD764_MY2022_Rx" SG_ 817 WindowLockout_B_Stat 1;
BA_ "U_U55X_MY2022_Rx" SG_ 817 WindowLockout_B_Stat 1;
BA_ "U_CD542_MY2021_Rx" SG_ 817 WindowLockout_B_Stat 1;
BA_ "U_T6_MCA_MY2020_Rx" SG_ 817 WindowLockout_B_Stat 1;
BA_ "U_P702_MY2021_Rx" SG_ 817 WindowLockout_B_Stat 1;
BA_ "U_CX727_MY2021_Rx" SG_ 817 WindowLockout_B_Stat 1;
BA_ "U_CD764_MY2022_Rx" SG_ 817 RollCodeUnlock 1;
BA_ "U_U55X_MY2022_Rx" SG_ 817 RollCodeUnlock 1;
BA_ "U_CD542_MY2021_Rx" SG_ 817 RollCodeUnlock 1;
BA_ "U_T6_MCA_MY2020_Rx" SG_ 817 RollCodeUnlock 1;
BA_ "U_P702_MY2021_Rx" SG_ 817 RollCodeUnlock 1;
BA_ "U_CX727_MY2021_Rx" SG_ 817 RollCodeUnlock 1;
BA_ "WakeupSignal" SG_ 817 Lockmsgtxt_D_Rq 1;
BA_ "U_U55X_MY2022_Rx" SG_ 817 LockInhibit 1;
BA_ "U_CD542_MY2021_Rx" SG_ 817 LockInhibit 1;
BA_ "U_T6_MCA_MY2020_Rx" SG_ 817 LockInhibit 1;
BA_ "U_CX727_MY2021_Rx" SG_ 817 LockInhibit 1;
BA_ "WakeupSignal" SG_ 817 LockInhibit 1;
BA_ "U_CX727_MY2021_Rx" SG_ 817 Veh_Lock_Status 1;
BA_ "U_CD764_MY2022_Rx" SG_ 817 Veh_Lock_Status 1;
BA_ "U_U55X_MY2022_Rx" SG_ 817 Veh_Lock_Status 1;
BA_ "U_CD542_MY2021_Rx" SG_ 817 Veh_Lock_Status 1;
BA_ "U_T6_MCA_MY2020_Rx" SG_ 817 Veh_Lock_Status 1;
BA_ "U_P702_MY2021_Rx" SG_ 817 Veh_Lock_Status 1;
BA_ "GenSigStartValue" SG_ 817 Veh_Lock_Status 1;
BA_ "GenSigStartValueInteger" SG_ 817 Veh_Lock_Status 1;
BA_ "WakeupSignal" SG_ 817 Veh_Lock_Status 1;
BA_ "U_U55X_MY2022_Rx" SG_ 817 FobComm_D_Stat 1;
BA_ "U_T6_MCA_MY2020_Rx" SG_ 817 FobComm_D_Stat 1;
BA_ "U_P702_MY2021_Rx" SG_ 817 FobComm_D_Stat 1;
BA_ "U_CX727_MY2021_Rx" SG_ 817 FobComm_D_Stat 1;
BA_ "GenSigSendType" SG_ 1091 CamraRearOn_D2_Stat2 3;
BA_ "GenSigSendType" SG_ 1091 PoliceAux4Lamp_B_Rq2 3;
BA_ "ContentDependant" SG_ 1091 PoliceAux4Lamp_B_Rq2 1;
BA_ "GenSigSendType" SG_ 1091 PoliceAux3Lamp_B_Rq2 3;
BA_ "ContentDependant" SG_ 1091 PoliceAux3Lamp_B_Rq2 1;
BA_ "GenSigSendType" SG_ 1091 PoliceAux2Lamp_B_Rq2 3;
BA_ "ContentDependant" SG_ 1091 PoliceAux2Lamp_B_Rq2 1;
BA_ "GenSigSendType" SG_ 1091 PoliceAux1Lamp_B_Rq2 3;
BA_ "ContentDependant" SG_ 1091 PoliceAux1Lamp_B_Rq2 1;
BA_ "GenSigSendType" SG_ 1091 WakeAlarm2_T_Rq 3;
BA_ "GenSigStartValue" SG_ 1091 WakeAlarm2_T_Rq 32767;
BA_ "GenSigStartValueInteger" SG_ 1091 WakeAlarm2_T_Rq 32767;
BA_ "GenSigSendType" SG_ 1091 WakeAlarm2_B_Typ 3;
BA_ "U_T6_MCA_MY2020_Tx" SG_ 1091 TrlrAlarmSpprt_D_Stat 1;
BA_ "GenSigSendType" SG_ 1091 TrlrAlarmSpprt_D_Stat 3;
BA_ "U_CD542_MY2021_Tx" SG_ 1091 TowBarMsgTxt_D_Rq 1;
BA_ "U_T6_MCA_MY2020_Tx" SG_ 1091 TowBarMsgTxt_D_Rq 1;
BA_ "GenSigSendType" SG_ 1091 TowBarMsgTxt_D_Rq 3;
BA_ "U_CD542_MY2021_Tx" SG_ 1091 ParkLampTrlrOut_B_Stat 1;
BA_ "U_T6_MCA_MY2020_Tx" SG_ 1091 ParkLampTrlrOut_B_Stat 1;
BA_ "U_P702_MY2021_Tx" SG_ 1091 ParkLampTrlrOut_B_Stat 1;
BA_ "GenSigSendType" SG_ 1091 ParkLampTrlrOut_B_Stat 3;
BA_ "U_CD542_MY2021_Tx" SG_ 1091 TrlrLampCtl_D_Stat 1;
BA_ "U_T6_MCA_MY2020_Tx" SG_ 1091 TrlrLampCtl_D_Stat 1;
BA_ "U_P702_MY2021_Tx" SG_ 1091 TrlrLampCtl_D_Stat 1;
BA_ "GenSigSendType" SG_ 1091 TrlrLampCtl_D_Stat 3;
BA_ "U_CD542_MY2021_Tx" SG_ 1091 TrlrBattChrg_D_Stat 1;
BA_ "U_T6_MCA_MY2020_Tx" SG_ 1091 TrlrBattChrg_D_Stat 1;
BA_ "U_P702_MY2021_Tx" SG_ 1091 TrlrBattChrg_D_Stat 1;
BA_ "GenSigSendType" SG_ 1091 TrlrBattChrg_D_Stat 3;
BA_ "U_CD542_MY2021_Tx" SG_ 1091 StopLampTrlrOut_B_Stat 1;
BA_ "U_T6_MCA_MY2020_Tx" SG_ 1091 StopLampTrlrOut_B_Stat 1;
BA_ "U_P702_MY2021_Tx" SG_ 1091 StopLampTrlrOut_B_Stat 1;
BA_ "GenSigSendType" SG_ 1091 StopLampTrlrOut_B_Stat 3;
BA_ "U_CD542_MY2021_Tx" SG_ 1091 TurnLampTrlrRr_B_Stat 1;
BA_ "U_T6_MCA_MY2020_Tx" SG_ 1091 TurnLampTrlrRr_B_Stat 1;
BA_ "U_P702_MY2021_Tx" SG_ 1091 TurnLampTrlrRr_B_Stat 1;
BA_ "GenSigSendType" SG_ 1091 TurnLampTrlrRr_B_Stat 3;
BA_ "U_CD542_MY2021_Tx" SG_ 1091 TurnLampTrlrRl_B_Stat 1;
BA_ "U_T6_MCA_MY2020_Tx" SG_ 1091 TurnLampTrlrRl_B_Stat 1;
BA_ "U_P702_MY2021_Tx" SG_ 1091 TurnLampTrlrRl_B_Stat 1;
BA_ "GenSigSendType" SG_ 1091 TurnLampTrlrRl_B_Stat 3;
BA_ "U_CD542_MY2021_Tx" SG_ 1091 TrlrLampCnnct_B_Actl 1;
BA_ "U_T6_MCA_MY2020_Tx" SG_ 1091 TrlrLampCnnct_B_Actl 1;
BA_ "U_P702_MY2021_Tx" SG_ 1091 TrlrLampCnnct_B_Actl 1;
BA_ "U_CX727_MY2021_Rx" SG_ 1091 TrlrLampCnnct_B_Actl 1;
BA_ "GenSigSendType" SG_ 1091 TrlrLampCnnct_B_Actl 3;
BA_ "U_CD764_MY2022_Tx" SG_ 1865 TesterPhysicalResPDM 1;
BA_ "U_U55X_MY2022_Tx" SG_ 1865 TesterPhysicalResPDM 1;
BA_ "U_CD542_MY2021_Tx" SG_ 1865 TesterPhysicalResPDM 1;
BA_ "U_T6_MCA_MY2020_Tx" SG_ 1865 TesterPhysicalResPDM 1;
BA_ "U_P702_MY2021_Tx" SG_ 1865 TesterPhysicalResPDM 1;
BA_ "GenSigSendType" SG_ 1865 TesterPhysicalResPDM 3;
BA_ "U_CD764_MY2022_Rx" SG_ 1857 TesterPhysicalReqPDM 1;
BA_ "U_U55X_MY2022_Rx" SG_ 1857 TesterPhysicalReqPDM 1;
BA_ "U_CD542_MY2021_Rx" SG_ 1857 TesterPhysicalReqPDM 1;
BA_ "U_T6_MCA_MY2020_Rx" SG_ 1857 TesterPhysicalReqPDM 1;
BA_ "U_P702_MY2021_Rx" SG_ 1857 TesterPhysicalReqPDM 1;
BA_ "GenSigSendType" SG_ 1857 TesterPhysicalReqPDM 3;
BA_ "U_CD764_MY2022_Tx" SG_ 1819 TesterPhysicalResSCMH 1;
BA_ "U_U55X_MY2022_Tx" SG_ 1819 TesterPhysicalResSCMH 1;
BA_ "U_P702_MY2021_Tx" SG_ 1819 TesterPhysicalResSCMH 1;
BA_ "GenSigSendType" SG_ 1819 TesterPhysicalResSCMH 3;
BA_ "U_CD764_MY2022_Tx" SG_ 1818 TesterPhysicalResSCMG 1;
BA_ "U_U55X_MY2022_Tx" SG_ 1818 TesterPhysicalResSCMG 1;
BA_ "U_P702_MY2021_Tx" SG_ 1818 TesterPhysicalResSCMG 1;
BA_ "GenSigSendType" SG_ 1818 TesterPhysicalResSCMG 3;
BA_ "U_CD764_MY2022_Rx" SG_ 1811 TesterPhysicalReqSCMH 1;
BA_ "U_U55X_MY2022_Rx" SG_ 1811 TesterPhysicalReqSCMH 1;
BA_ "U_P702_MY2021_Rx" SG_ 1811 TesterPhysicalReqSCMH 1;
BA_ "GenSigSendType" SG_ 1811 TesterPhysicalReqSCMH 3;
BA_ "U_CD764_MY2022_Rx" SG_ 1810 TesterPhysicalReqSCMG 1;
BA_ "U_U55X_MY2022_Rx" SG_ 1810 TesterPhysicalReqSCMG 1;
BA_ "U_P702_MY2021_Rx" SG_ 1810 TesterPhysicalReqSCMG 1;
BA_ "GenSigSendType" SG_ 1810 TesterPhysicalReqSCMG 3;
BA_ "U_CD764_MY2022_Tx" SG_ 1310 GWM_Network_Mgmt_MS1 1;
BA_ "ECGUsedTxSignal" SG_ 1310 GWM_Network_Mgmt_MS1 1;
BA_ "U_P702_MY2021_Rx" SG_ 1310 GWM_Network_Mgmt_MS1 1;
BA_ "GenSigSendType" SG_ 1310 GWM_Network_Mgmt_MS1 3;
BA_ "U_CD764_MY2022_Rx" SG_ 1066 BattULo_U_Actl_UB 1;
BA_ "U_U55X_MY2022_Rx" SG_ 1066 BattULo_U_Actl_UB 1;
BA_ "U_CD542_MY2021_Rx" SG_ 1066 BattULo_U_Actl_UB 1;
BA_ "U_T6_MCA_MY2020_Rx" SG_ 1066 BattULo_U_Actl_UB 1;
BA_ "U_P702_MY2021_Rx" SG_ 1066 BattULo_U_Actl_UB 1;
BA_ "U_CX727_MY2021_Rx" SG_ 1066 BattULo_U_Actl_UB 1;
BA_ "U_CD764_MY2022_Rx" SG_ 1066 BattULo_U_Actl 1;
BA_ "U_U55X_MY2022_Rx" SG_ 1066 BattULo_U_Actl 1;
BA_ "U_CD542_MY2021_Rx" SG_ 1066 BattULo_U_Actl 1;
BA_ "U_T6_MCA_MY2020_Rx" SG_ 1066 BattULo_U_Actl 1;
BA_ "U_P702_MY2021_Rx" SG_ 1066 BattULo_U_Actl 1;
BA_ "U_CX727_MY2021_Rx" SG_ 1066 BattULo_U_Actl 1;
BA_ "GenSigStartValue" SG_ 1066 BattULo_U_Actl 255;
BA_ "GenSigStartValueInteger" SG_ 1066 BattULo_U_Actl 255;
BA_ "U_CD764_MY2022_Rx" SG_ 1066 PwSrcULo_I_Mx 1;
BA_ "U_U55X_MY2022_Rx" SG_ 1066 PwSrcULo_I_Mx 1;
BA_ "U_CD542_MY2021_Rx" SG_ 1066 PwSrcULo_I_Mx 1;
BA_ "U_T6_MCA_MY2020_Rx" SG_ 1066 PwSrcULo_I_Mx 1;
BA_ "U_P702_MY2021_Rx" SG_ 1066 PwSrcULo_I_Mx 1;
BA_ "U_CX727_MY2021_Rx" SG_ 1066 PwSrcULo_I_Mx 1;
BA_ "U_CD764_MY2022_Rx" SG_ 1066 PwSrcULo_I_Actl 1;
BA_ "U_U55X_MY2022_Rx" SG_ 1066 PwSrcULo_I_Actl 1;
BA_ "U_CD542_MY2021_Rx" SG_ 1066 PwSrcULo_I_Actl 1;
BA_ "U_T6_MCA_MY2020_Rx" SG_ 1066 PwSrcULo_I_Actl 1;
BA_ "U_P702_MY2021_Rx" SG_ 1066 PwSrcULo_I_Actl 1;
BA_ "U_CX727_MY2021_Rx" SG_ 1066 PwSrcULo_I_Actl 1;
BA_ "U_CD764_MY2022_Rx" SG_ 1066 PwSrcULo_I_Mx_UB 1;
BA_ "U_U55X_MY2022_Rx" SG_ 1066 PwSrcULo_I_Mx_UB 1;
BA_ "U_CD542_MY2021_Rx" SG_ 1066 PwSrcULo_I_Mx_UB 1;
BA_ "U_T6_MCA_MY2020_Rx" SG_ 1066 PwSrcULo_I_Mx_UB 1;
BA_ "U_P702_MY2021_Rx" SG_ 1066 PwSrcULo_I_Mx_UB 1;
BA_ "U_CX727_MY2021_Rx" SG_ 1066 PwSrcULo_I_Mx_UB 1;
BA_ "U_CD764_MY2022_Rx" SG_ 1066 PwSrcULo_I_Actl_UB 1;
BA_ "U_U55X_MY2022_Rx" SG_ 1066 PwSrcULo_I_Actl_UB 1;
BA_ "U_CD542_MY2021_Rx" SG_ 1066 PwSrcULo_I_Actl_UB 1;
BA_ "U_T6_MCA_MY2020_Rx" SG_ 1066 PwSrcULo_I_Actl_UB 1;
BA_ "U_P702_MY2021_Rx" SG_ 1066 PwSrcULo_I_Actl_UB 1;
BA_ "U_CX727_MY2021_Rx" SG_ 1066 PwSrcULo_I_Actl_UB 1;
BA_ "WakeupSignal" SG_ 994 Pers4OptIn_B_Stats 1;
BA_ "WakeupSignal" SG_ 994 Pers3OptIn_B_Stats 1;
BA_ "WakeupSignal" SG_ 994 Pers2OptIn_B_Stats 1;
BA_ "WakeupSignal" SG_ 994 Pers1OptIn_B_Stats 1;
BA_ "U_CD542_MY2021_Rx" SG_ 994 CtrStkPersIndex_D_Actl 1;
BA_ "U_T6_MCA_MY2020_Rx" SG_ 994 CtrStkPersIndex_D_Actl 1;
BA_ "U_CX727_MY2021_Rx" SG_ 994 CtrStkPersIndex_D_Actl 1;
BA_ "U_CD764_MY2022_Rx" SG_ 994 CtrStkPersIndex_D_Actl 1;
BA_ "U_U55X_MY2022_Rx" SG_ 994 CtrStkPersIndex_D_Actl 1;
BA_ "U_P702_MY2021_Rx" SG_ 994 CtrStkPersIndex_D_Actl 1;
BA_ "GenSigStartValue" SG_ 994 CtrStkPersIndex_D_Actl 4;
BA_ "GenSigStartValueInteger" SG_ 994 CtrStkPersIndex_D_Actl 4;
BA_ "U_CD764_MY2022_Rx" SG_ 994 CtrStkFeatNoActl 1;
BA_ "U_U55X_MY2022_Rx" SG_ 994 CtrStkFeatNoActl 1;
BA_ "U_CD542_MY2021_Rx" SG_ 994 CtrStkFeatNoActl 1;
BA_ "U_T6_MCA_MY2020_Rx" SG_ 994 CtrStkFeatNoActl 1;
BA_ "U_P702_MY2021_Rx" SG_ 994 CtrStkFeatNoActl 1;
BA_ "U_CX727_MY2021_Rx" SG_ 994 CtrStkFeatNoActl 1;
BA_ "U_CD764_MY2022_Rx" SG_ 994 CtrStkFeatConfigActl 1;
BA_ "U_U55X_MY2022_Rx" SG_ 994 CtrStkFeatConfigActl 1;
BA_ "U_CD542_MY2021_Rx" SG_ 994 CtrStkFeatConfigActl 1;
BA_ "U_T6_MCA_MY2020_Rx" SG_ 994 CtrStkFeatConfigActl 1;
BA_ "U_P702_MY2021_Rx" SG_ 994 CtrStkFeatConfigActl 1;
BA_ "U_CX727_MY2021_Rx" SG_ 994 CtrStkFeatConfigActl 1;
BA_ "U_CD542_MY2021_Rx" SG_ 994 CtrStkDsplyOp_D_Rq 1;
BA_ "U_T6_MCA_MY2020_Rx" SG_ 994 CtrStkDsplyOp_D_Rq 1;
BA_ "U_CX727_MY2021_Rx" SG_ 994 CtrStkDsplyOp_D_Rq 1;
BA_ "U_CD764_MY2022_Rx" SG_ 994 CtrStkDsplyOp_D_Rq 1;
BA_ "U_U55X_MY2022_Rx" SG_ 994 CtrStkDsplyOp_D_Rq 1;
BA_ "U_P702_MY2021_Rx" SG_ 994 CtrStkDsplyOp_D_Rq 1;
BA_ "U_CD764_MY2022_Rx" SG_ 994 PersStore_D_Rq 1;
BA_ "U_CD542_MY2021_Rx" SG_ 994 PersStore_D_Rq 1;
BA_ "U_T6_MCA_MY2020_Rx" SG_ 994 PersStore_D_Rq 1;
BA_ "U_P702_MY2021_Rx" SG_ 994 PersStore_D_Rq 1;
BA_ "U_CX727_MY2021_Rx" SG_ 994 PersStore_D_Rq 1;
BA_ "ContentDependant" SG_ 376 EngAout_Aa_Actl 1;
BA_ "U_CD764_MY2022_Rx" SG_ 376 HvacHtrCore2_Te_Actl 1;
BA_ "U_U55X_MY2022_Rx" SG_ 376 HvacHtrCore2_Te_Actl 1;
BA_ "U_CD542_MY2021_Rx" SG_ 376 HvacHtrCore2_Te_Actl 1;
BA_ "U_P702_MY2021_Rx" SG_ 376 HvacHtrCore2_Te_Actl 1;
BA_ "U_CX727_MY2021_Rx" SG_ 376 HvacHtrCore2_Te_Actl 1;
BA_ "GenSigStartValueInteger" SG_ 376 HvacHtrCore2_Te_Actl 200;
BA_ "U_CD764_MY2022_Rx" SG_ 376 AirAmbTe_D_Qf 1;
BA_ "U_U55X_MY2022_Rx" SG_ 376 AirAmbTe_D_Qf 1;
BA_ "U_CD542_MY2021_Rx" SG_ 376 AirAmbTe_D_Qf 1;
BA_ "U_T6_MCA_MY2020_Rx" SG_ 376 AirAmbTe_D_Qf 1;
BA_ "U_P702_MY2021_Rx" SG_ 376 AirAmbTe_D_Qf 1;
BA_ "U_CX727_MY2021_Rx" SG_ 376 AirAmbTe_D_Qf 1;
BA_ "GenSigStartValue" SG_ 376 AirAmbTe_D_Qf 1;
BA_ "MetaData" SG_ 376 AirAmbTe_D_Qf 1;
BA_ "GenSigStartValueInteger" SG_ 376 AirAmbTe_D_Qf 1;
BA_ "U_CD764_MY2022_Rx" SG_ 376 AirAmb_Te_ActlFilt 1;
BA_ "U_CD542_MY2021_Rx" SG_ 376 AirAmb_Te_ActlFilt 1;
BA_ "U_T6_MCA_MY2020_Rx" SG_ 376 AirAmb_Te_ActlFilt 1;
BA_ "U_P702_MY2021_Rx" SG_ 376 AirAmb_Te_ActlFilt 1;
BA_ "U_CX727_MY2021_Rx" SG_ 376 AirAmb_Te_ActlFilt 1;
BA_ "U_U55X_MY2022_Rx" SG_ 376 AirAmb_Te_ActlFilt 1;
BA_ "GenSigStartValueInteger" SG_ 376 AirAmb_Te_ActlFilt 512;
BA_ "U_CD764_MY2022_Rx" SG_ 376 AirAmb_Te_Actl 1;
BA_ "U_U55X_MY2022_Rx" SG_ 376 AirAmb_Te_Actl 1;
BA_ "U_CD542_MY2021_Rx" SG_ 376 AirAmb_Te_Actl 1;
BA_ "U_T6_MCA_MY2020_Rx" SG_ 376 AirAmb_Te_Actl 1;
BA_ "U_P702_MY2021_Rx" SG_ 376 AirAmb_Te_Actl 1;
BA_ "U_CX727_MY2021_Rx" SG_ 376 AirAmb_Te_Actl 1;
BA_ "GenSigStartValueInteger" SG_ 376 AirAmb_Te_Actl 512;
BA_ "U_U55X_MY2022_Rx" SG_ 951 TirePress_Info_MaxInd 1;
BA_ "U_T6_MCA_MY2020_Rx" SG_ 951 TirePress_Info_MaxInd 1;
BA_ "U_P702_MY2021_Rx" SG_ 951 TirePress_Info_MaxInd 1;
BA_ "U_CX727_MY2021_Rx" SG_ 951 TirePress_Info_MaxInd 1;
BA_ "U_U55X_MY2022_Rx" SG_ 951 TirePress_Info_Index 1;
BA_ "U_T6_MCA_MY2020_Rx" SG_ 951 TirePress_Info_Index 1;
BA_ "U_P702_MY2021_Rx" SG_ 951 TirePress_Info_Index 1;
BA_ "U_CX727_MY2021_Rx" SG_ 951 TirePress_Info_Index 1;
BA_ "U_U55X_MY2022_Rx" SG_ 951 TirePress_Info_ID 1;
BA_ "U_T6_MCA_MY2020_Rx" SG_ 951 TirePress_Info_ID 1;
BA_ "U_P702_MY2021_Rx" SG_ 951 TirePress_Info_ID 1;
BA_ "U_CX727_MY2021_Rx" SG_ 951 TirePress_Info_ID 1;
BA_ "U_CD764_MY2022_Rx" SG_ 1068 HvacAirFullOut_B_Rq_UB 1;
BA_ "U_U55X_MY2022_Rx" SG_ 1068 HvacAirFullOut_B_Rq_UB 1;
BA_ "U_CD542_MY2021_Rx" SG_ 1068 HvacAirFullOut_B_Rq_UB 1;
BA_ "U_T6_MCA_MY2020_Rx" SG_ 1068 HvacAirFullOut_B_Rq_UB 1;
BA_ "U_P702_MY2021_Rx" SG_ 1068 HvacAirFullOut_B_Rq_UB 1;
BA_ "U_CD764_MY2022_Rx" SG_ 1068 HvacAirFullOut_B_Rq 1;
BA_ "U_U55X_MY2022_Rx" SG_ 1068 HvacAirFullOut_B_Rq 1;
BA_ "U_CD542_MY2021_Rx" SG_ 1068 HvacAirFullOut_B_Rq 1;
BA_ "U_T6_MCA_MY2020_Rx" SG_ 1068 HvacAirFullOut_B_Rq 1;
BA_ "U_P702_MY2021_Rx" SG_ 1068 HvacAirFullOut_B_Rq 1;
BA_ "U_CD764_MY2022_Rx" SG_ 1068 HvacCmprLim_D_Stat_UB 1;
BA_ "U_U55X_MY2022_Rx" SG_ 1068 HvacCmprLim_D_Stat_UB 1;
BA_ "U_CD542_MY2021_Rx" SG_ 1068 HvacCmprLim_D_Stat_UB 1;
BA_ "U_T6_MCA_MY2020_Rx" SG_ 1068 HvacCmprLim_D_Stat_UB 1;
BA_ "U_CD764_MY2022_Rx" SG_ 1068 HvacCmprLim_D_Stat 1;
BA_ "U_U55X_MY2022_Rx" SG_ 1068 HvacCmprLim_D_Stat 1;
BA_ "U_CD542_MY2021_Rx" SG_ 1068 HvacCmprLim_D_Stat 1;
BA_ "U_T6_MCA_MY2020_Rx" SG_ 1068 HvacCmprLim_D_Stat 1;
BA_ "U_CX727_MY2021_Rx" SG_ 1068 HvacAirFlw_B_RqBatt_UB 1;
BA_ "U_CX727_MY2021_Rx" SG_ 1068 HvacAirFlw_B_RqBatt 1;
BA_ "WakeupSignal" SG_ 1068 HvacAirFlw_B_RqBatt 1;
BA_ "U_CD764_MY2022_Rx" SG_ 1068 HvacRec_D_RqMxBatt_UB 1;
BA_ "U_U55X_MY2022_Rx" SG_ 1068 HvacRec_D_RqMxBatt_UB 1;
BA_ "U_CD542_MY2021_Rx" SG_ 1068 HvacRec_D_RqMxBatt_UB 1;
BA_ "U_CX727_MY2021_Rx" SG_ 1068 HvacRec_D_RqMxBatt_UB 1;
BA_ "U_CD764_MY2022_Rx" SG_ 1068 HvacRec_D_RqMxBatt 1;
BA_ "U_U55X_MY2022_Rx" SG_ 1068 HvacRec_D_RqMxBatt 1;
BA_ "U_CD542_MY2021_Rx" SG_ 1068 HvacRec_D_RqMxBatt 1;
BA_ "U_CX727_MY2021_Rx" SG_ 1068 HvacRec_D_RqMxBatt 1;
BA_ "GenSigStartValue" SG_ 1068 HvacRec_D_RqMxBatt 10;
BA_ "GenSigStartValueInteger" SG_ 1068 HvacRec_D_RqMxBatt 10;
BA_ "U_CD764_MY2022_Rx" SG_ 1068 Batt_Lo_SoC_B_UB 1;
BA_ "U_U55X_MY2022_Rx" SG_ 1068 Batt_Lo_SoC_B_UB 1;
BA_ "U_CX727_MY2021_Rx" SG_ 1068 Batt_Lo_SoC_B_UB 1;
BA_ "U_CD542_MY2021_Rx" SG_ 1068 Batt_Lo_SoC_B_UB 1;
BA_ "U_T6_MCA_MY2020_Rx" SG_ 1068 Batt_Lo_SoC_B_UB 1;
BA_ "U_P702_MY2021_Rx" SG_ 1068 Batt_Lo_SoC_B_UB 1;
BA_ "U_CD764_MY2022_Rx" SG_ 1068 Batt_Lo_SoC_B 1;
BA_ "U_U55X_MY2022_Rx" SG_ 1068 Batt_Lo_SoC_B 1;
BA_ "U_CX727_MY2021_Rx" SG_ 1068 Batt_Lo_SoC_B 1;
BA_ "U_CD542_MY2021_Rx" SG_ 1068 Batt_Lo_SoC_B 1;
BA_ "U_T6_MCA_MY2020_Rx" SG_ 1068 Batt_Lo_SoC_B 1;
BA_ "U_P702_MY2021_Rx" SG_ 1068 Batt_Lo_SoC_B 1;
BA_ "U_CD764_MY2022_Rx" SG_ 1068 Batt_Crit_SoC_B_UB 1;
BA_ "U_U55X_MY2022_Rx" SG_ 1068 Batt_Crit_SoC_B_UB 1;
BA_ "U_CX727_MY2021_Rx" SG_ 1068 Batt_Crit_SoC_B_UB 1;
BA_ "U_CD542_MY2021_Rx" SG_ 1068 Batt_Crit_SoC_B_UB 1;
BA_ "U_T6_MCA_MY2020_Rx" SG_ 1068 Batt_Crit_SoC_B_UB 1;
BA_ "U_P702_MY2021_Rx" SG_ 1068 Batt_Crit_SoC_B_UB 1;
BA_ "U_CD764_MY2022_Rx" SG_ 1068 Batt_Crit_SoC_B 1;
BA_ "U_U55X_MY2022_Rx" SG_ 1068 Batt_Crit_SoC_B 1;
BA_ "U_CX727_MY2021_Rx" SG_ 1068 Batt_Crit_SoC_B 1;
BA_ "U_CD542_MY2021_Rx" SG_ 1068 Batt_Crit_SoC_B 1;
BA_ "U_T6_MCA_MY2020_Rx" SG_ 1068 Batt_Crit_SoC_B 1;
BA_ "U_P702_MY2021_Rx" SG_ 1068 Batt_Crit_SoC_B 1;
BA_ "U_CD764_MY2022_Rx" SG_ 1068 Shed_T_Eng_Off_B_UB 1;
BA_ "U_CX727_MY2021_Rx" SG_ 1068 Shed_T_Eng_Off_B_UB 1;
BA_ "U_U55X_MY2022_Rx" SG_ 1068 Shed_T_Eng_Off_B_UB 1;
BA_ "U_CD542_MY2021_Rx" SG_ 1068 Shed_T_Eng_Off_B_UB 1;
BA_ "U_T6_MCA_MY2020_Rx" SG_ 1068 Shed_T_Eng_Off_B_UB 1;
BA_ "U_P702_MY2021_Rx" SG_ 1068 Shed_T_Eng_Off_B_UB 1;
BA_ "U_CD764_MY2022_Rx" SG_ 1068 Shed_T_Eng_Off_B 1;
BA_ "U_CX727_MY2021_Rx" SG_ 1068 Shed_T_Eng_Off_B 1;
BA_ "U_U55X_MY2022_Rx" SG_ 1068 Shed_T_Eng_Off_B 1;
BA_ "U_CD542_MY2021_Rx" SG_ 1068 Shed_T_Eng_Off_B 1;
BA_ "U_T6_MCA_MY2020_Rx" SG_ 1068 Shed_T_Eng_Off_B 1;
BA_ "U_P702_MY2021_Rx" SG_ 1068 Shed_T_Eng_Off_B 1;
BA_ "U_CX727_MY2021_Rx" SG_ 1068 Shed_Level_Req_UB 1;
BA_ "U_CD764_MY2022_Rx" SG_ 1068 Shed_Level_Req_UB 1;
BA_ "U_U55X_MY2022_Rx" SG_ 1068 Shed_Level_Req_UB 1;
BA_ "U_CD542_MY2021_Rx" SG_ 1068 Shed_Level_Req_UB 1;
BA_ "U_T6_MCA_MY2020_Rx" SG_ 1068 Shed_Level_Req_UB 1;
BA_ "U_P702_MY2021_Rx" SG_ 1068 Shed_Level_Req_UB 1;
BA_ "U_CX727_MY2021_Rx" SG_ 1068 Shed_Level_Req 1;
BA_ "U_CD764_MY2022_Rx" SG_ 1068 Shed_Level_Req 1;
BA_ "U_U55X_MY2022_Rx" SG_ 1068 Shed_Level_Req 1;
BA_ "U_CD542_MY2021_Rx" SG_ 1068 Shed_Level_Req 1;
BA_ "U_T6_MCA_MY2020_Rx" SG_ 1068 Shed_Level_Req 1;
BA_ "U_P702_MY2021_Rx" SG_ 1068 Shed_Level_Req 1;
BA_ "WakeupSignal" SG_ 1068 Shed_Level_Req 1;
BA_ "U_CD764_MY2022_Rx" SG_ 1068 Shed_Feature_Group_ID_UB 1;
BA_ "U_CX727_MY2021_Rx" SG_ 1068 Shed_Feature_Group_ID_UB 1;
BA_ "U_U55X_MY2022_Rx" SG_ 1068 Shed_Feature_Group_ID_UB 1;
BA_ "U_CD542_MY2021_Rx" SG_ 1068 Shed_Feature_Group_ID_UB 1;
BA_ "U_T6_MCA_MY2020_Rx" SG_ 1068 Shed_Feature_Group_ID_UB 1;
BA_ "U_P702_MY2021_Rx" SG_ 1068 Shed_Feature_Group_ID_UB 1;
BA_ "U_CD764_MY2022_Rx" SG_ 1068 Shed_Feature_Group_ID 1;
BA_ "U_CX727_MY2021_Rx" SG_ 1068 Shed_Feature_Group_ID 1;
BA_ "U_U55X_MY2022_Rx" SG_ 1068 Shed_Feature_Group_ID 1;
BA_ "U_CD542_MY2021_Rx" SG_ 1068 Shed_Feature_Group_ID 1;
BA_ "U_T6_MCA_MY2020_Rx" SG_ 1068 Shed_Feature_Group_ID 1;
BA_ "U_P702_MY2021_Rx" SG_ 1068 Shed_Feature_Group_ID 1;
BA_ "WakeupSignal" SG_ 1068 Shed_Feature_Group_ID 1;
BA_ "U_CD764_MY2022_Rx" SG_ 1068 Shed_Drain_Eng_Off_B_UB 1;
BA_ "U_CX727_MY2021_Rx" SG_ 1068 Shed_Drain_Eng_Off_B_UB 1;
BA_ "U_U55X_MY2022_Rx" SG_ 1068 Shed_Drain_Eng_Off_B_UB 1;
BA_ "U_CD542_MY2021_Rx" SG_ 1068 Shed_Drain_Eng_Off_B_UB 1;
BA_ "U_T6_MCA_MY2020_Rx" SG_ 1068 Shed_Drain_Eng_Off_B_UB 1;
BA_ "U_P702_MY2021_Rx" SG_ 1068 Shed_Drain_Eng_Off_B_UB 1;
BA_ "U_CD764_MY2022_Rx" SG_ 1068 Shed_Drain_Eng_Off_B 1;
BA_ "U_CX727_MY2021_Rx" SG_ 1068 Shed_Drain_Eng_Off_B 1;
BA_ "U_U55X_MY2022_Rx" SG_ 1068 Shed_Drain_Eng_Off_B 1;
BA_ "U_CD542_MY2021_Rx" SG_ 1068 Shed_Drain_Eng_Off_B 1;
BA_ "U_T6_MCA_MY2020_Rx" SG_ 1068 Shed_Drain_Eng_Off_B 1;
BA_ "U_P702_MY2021_Rx" SG_ 1068 Shed_Drain_Eng_Off_B 1;
BA_ "U_CX727_MY2021_Rx" SG_ 1068 HvacAir_Flw_EstBatt_UB 1;
BA_ "U_CX727_MY2021_Rx" SG_ 1068 HvacAir_Flw_EstBatt 1;
BA_ "U_CD764_MY2022_Rx" SG_ 1068 AirCondRec_B_Rq_UB 1;
BA_ "U_U55X_MY2022_Rx" SG_ 1068 AirCondRec_B_Rq_UB 1;
BA_ "U_CD542_MY2021_Rx" SG_ 1068 AirCondRec_B_Rq_UB 1;
BA_ "U_T6_MCA_MY2020_Rx" SG_ 1068 AirCondRec_B_Rq_UB 1;
BA_ "U_P702_MY2021_Rx" SG_ 1068 AirCondRec_B_Rq_UB 1;
BA_ "U_CX727_MY2021_Rx" SG_ 1068 AirCondRec_B_Rq_UB 1;
BA_ "U_CD764_MY2022_Rx" SG_ 1068 AirCondFluidHi_P_Actl_UB 1;
BA_ "U_U55X_MY2022_Rx" SG_ 1068 AirCondFluidHi_P_Actl_UB 1;
BA_ "U_CD542_MY2021_Rx" SG_ 1068 AirCondFluidHi_P_Actl_UB 1;
BA_ "U_T6_MCA_MY2020_Rx" SG_ 1068 AirCondFluidHi_P_Actl_UB 1;
BA_ "U_P702_MY2021_Rx" SG_ 1068 AirCondFluidHi_P_Actl_UB 1;
BA_ "U_CX727_MY2021_Rx" SG_ 1068 AirCondFluidHi_P_Actl_UB 1;
BA_ "U_CD764_MY2022_Rx" SG_ 1068 AirCondClutch_B_Stats_UB 1;
BA_ "U_U55X_MY2022_Rx" SG_ 1068 AirCondClutch_B_Stats_UB 1;
BA_ "U_CD542_MY2021_Rx" SG_ 1068 AirCondClutch_B_Stats_UB 1;
BA_ "U_T6_MCA_MY2020_Rx" SG_ 1068 AirCondClutch_B_Stats_UB 1;
BA_ "U_P702_MY2021_Rx" SG_ 1068 AirCondClutch_B_Stats_UB 1;
BA_ "U_CX727_MY2021_Rx" SG_ 1068 AirCondClutch_B_Stats_UB 1;
BA_ "U_CD764_MY2022_Rx" SG_ 1068 AirCondRec_B_Rq 1;
BA_ "U_U55X_MY2022_Rx" SG_ 1068 AirCondRec_B_Rq 1;
BA_ "U_CD542_MY2021_Rx" SG_ 1068 AirCondRec_B_Rq 1;
BA_ "U_T6_MCA_MY2020_Rx" SG_ 1068 AirCondRec_B_Rq 1;
BA_ "U_P702_MY2021_Rx" SG_ 1068 AirCondRec_B_Rq 1;
BA_ "U_CX727_MY2021_Rx" SG_ 1068 AirCondRec_B_Rq 1;
BA_ "ContentDependant" SG_ 1068 AirCondRec_B_Rq 1;
BA_ "U_CD764_MY2022_Rx" SG_ 1068 AirCondFluidHi_P_Actl 1;
BA_ "U_U55X_MY2022_Rx" SG_ 1068 AirCondFluidHi_P_Actl 1;
BA_ "U_CD542_MY2021_Rx" SG_ 1068 AirCondFluidHi_P_Actl 1;
BA_ "U_T6_MCA_MY2020_Rx" SG_ 1068 AirCondFluidHi_P_Actl 1;
BA_ "U_P702_MY2021_Rx" SG_ 1068 AirCondFluidHi_P_Actl 1;
BA_ "U_CX727_MY2021_Rx" SG_ 1068 AirCondFluidHi_P_Actl 1;
BA_ "U_CD764_MY2022_Rx" SG_ 1068 AirCondClutch_B_Stats 1;
BA_ "U_U55X_MY2022_Rx" SG_ 1068 AirCondClutch_B_Stats 1;
BA_ "U_CD542_MY2021_Rx" SG_ 1068 AirCondClutch_B_Stats 1;
BA_ "U_T6_MCA_MY2020_Rx" SG_ 1068 AirCondClutch_B_Stats 1;
BA_ "U_P702_MY2021_Rx" SG_ 1068 AirCondClutch_B_Stats 1;
BA_ "U_CX727_MY2021_Rx" SG_ 1068 AirCondClutch_B_Stats 1;
BA_ "ContentDependant" SG_ 1068 AirCondClutch_B_Stats 1;
BA_ "WakeupSignal" SG_ 963 ImpactEvntFdbck_D_Stat 1;
BA_ "U_CD764_MY2022_Rx" SG_ 963 PudLampPsngr_D_Rq 1;
BA_ "U_CD542_MY2021_Rx" SG_ 963 PudLampPsngr_D_Rq 1;
BA_ "U_T6_MCA_MY2020_Rx" SG_ 963 PudLampPsngr_D_Rq 1;
BA_ "U_P702_MY2021_Rx" SG_ 963 PudLampPsngr_D_Rq 1;
BA_ "U_U55X_MY2022_Rx" SG_ 963 PudLampPsngr_D_Rq 1;
BA_ "WakeupSignal" SG_ 963 HomeSafeLtChime_B_Rq 1;
BA_ "U_U55X_MY2022_Rx" SG_ 963 StopLghtOn_B_Stat 1;
BA_ "U_CX727_MY2021_Rx" SG_ 963 StopLghtOn_B_Stat 1;
BA_ "U_CD542_MY2021_Rx" SG_ 963 StopLghtOn_B_Stat 1;
BA_ "U_T6_MCA_MY2020_Rx" SG_ 963 StopLghtOn_B_Stat 1;
BA_ "U_P702_MY2021_Rx" SG_ 963 StopLghtOn_B_Stat 1;
BA_ "WakeupSignal" SG_ 963 StopLghtOn_B_Stat 1;
BA_ "U_CD542_MY2021_Rx" SG_ 963 RvrseLghtOn_B_Stat 1;
BA_ "U_T6_MCA_MY2020_Rx" SG_ 963 RvrseLghtOn_B_Stat 1;
BA_ "U_P702_MY2021_Rx" SG_ 963 RvrseLghtOn_B_Stat 1;
BA_ "U_CD542_MY2021_Rx" SG_ 963 PrkLght_D_Stat 1;
BA_ "U_T6_MCA_MY2020_Rx" SG_ 963 PrkLght_D_Stat 1;
BA_ "U_P702_MY2021_Rx" SG_ 963 PrkLght_D_Stat 1;
BA_ "WakeupSignal" SG_ 963 PrkLght_D_Stat 1;
BA_ "GenSigStartValue" SG_ 963 HeadLghtSwtch_D_Stat 2;
BA_ "GenSigStartValueInteger" SG_ 963 HeadLghtSwtch_D_Stat 2;
BA_ "WakeupSignal" SG_ 963 HeadLghtSwtch_D_Stat 1;
BA_ "WakeupSignal" SG_ 963 KeyInIgnWarn_B_Cmd 1;
BA_ "GenSigStartValue" SG_ 963 HeadLampLoFrOn_B_Stat 1;
BA_ "GenSigStartValueInteger" SG_ 963 HeadLampLoFrOn_B_Stat 1;
BA_ "GenSigStartValue" SG_ 963 HeadLampLoFlOn_B_Stat 1;
BA_ "GenSigStartValueInteger" SG_ 963 HeadLampLoFlOn_B_Stat 1;
BA_ "WakeupSignal" SG_ 963 Headlamp_On_Wrning_Cmd 1;
BA_ "GenSigStartValue" SG_ 963 HeadLampLoActv_B_Stat 1;
BA_ "GenSigStartValueInteger" SG_ 963 HeadLampLoActv_B_Stat 1;
BA_ "WakeupSignal" SG_ 963 HeadLghtHiOn_B_Stat 1;
BA_ "U_CX727_MY2021_Rx" SG_ 963 Courtesy_BSave_Stat 1;
BA_ "U_CD764_MY2022_Rx" SG_ 963 Courtesy_BSave_Stat 1;
BA_ "U_U55X_MY2022_Rx" SG_ 963 Courtesy_BSave_Stat 1;
BA_ "U_CD542_MY2021_Rx" SG_ 963 Courtesy_BSave_Stat 1;
BA_ "U_T6_MCA_MY2020_Rx" SG_ 963 Courtesy_BSave_Stat 1;
BA_ "U_P702_MY2021_Rx" SG_ 963 Courtesy_BSave_Stat 1;
BA_ "GenSigStartValue" SG_ 963 Courtesy_BSave_Stat 1;
BA_ "GenSigStartValueInteger" SG_ 963 Courtesy_BSave_Stat 1;
BA_ "WakeupSignal" SG_ 963 Courtesy_BSave_Stat 1;
BA_ "WakeupSignal" SG_ 963 PerimeterAlarmChimeRq 1;
BA_ "U_CD764_MY2022_Rx" SG_ 963 PudLampDrv_D_Rq 1;
BA_ "U_CX727_MY2021_Rx" SG_ 963 PudLampDrv_D_Rq 1;
BA_ "U_CD542_MY2021_Rx" SG_ 963 PudLampDrv_D_Rq 1;
BA_ "U_T6_MCA_MY2020_Rx" SG_ 963 PudLampDrv_D_Rq 1;
BA_ "U_P702_MY2021_Rx" SG_ 963 PudLampDrv_D_Rq 1;
BA_ "U_U55X_MY2022_Rx" SG_ 963 PudLampDrv_D_Rq 1;
BA_ "U_U55X_MY2022_Rx" SG_ 963 Perimeter_Alarm_Status 1;
BA_ "U_P702_MY2021_Rx" SG_ 963 Perimeter_Alarm_Status 1;
BA_ "U_CX727_MY2021_Rx" SG_ 963 Perimeter_Alarm_Status 1;
BA_ "U_T6_MCA_MY2020_Rx" SG_ 963 Perimeter_Alarm_Status 1;
BA_ "WakeupSignal" SG_ 963 Perimeter_Alarm_Status 1;
BA_ "U_CX727_MY2021_Rx" SG_ 963 WndwGlbl_D_Cmd 1;
BA_ "U_CD764_MY2022_Rx" SG_ 963 WndwGlbl_D_Cmd 1;
BA_ "U_U55X_MY2022_Rx" SG_ 963 WndwGlbl_D_Cmd 1;
BA_ "U_CD542_MY2021_Rx" SG_ 963 WndwGlbl_D_Cmd 1;
BA_ "U_T6_MCA_MY2020_Rx" SG_ 963 WndwGlbl_D_Cmd 1;
BA_ "U_P702_MY2021_Rx" SG_ 963 WndwGlbl_D_Cmd 1;
BA_ "WakeupSignal" SG_ 963 WndwGlbl_D_Cmd 1;
BA_ "U_CX727_MY2021_Rx" SG_ 963 PudLamp_D_Rq 1;
BA_ "U_CD764_MY2022_Rx" SG_ 963 PudLamp_D_Rq 1;
BA_ "U_U55X_MY2022_Rx" SG_ 963 PudLamp_D_Rq 1;
BA_ "U_CD542_MY2021_Rx" SG_ 963 PudLamp_D_Rq 1;
BA_ "U_T6_MCA_MY2020_Rx" SG_ 963 PudLamp_D_Rq 1;
BA_ "U_P702_MY2021_Rx" SG_ 963 PudLamp_D_Rq 1;
BA_ "WakeupSignal" SG_ 963 PudLamp_D_Rq 1;
BA_ "GenSigSendType" SG_ 964 FohEng_D_Rq 3;
BA_ "GenSigStartValue" SG_ 964 FohEng_D_Rq 2;
BA_ "ContentDependant" SG_ 964 FohEng_D_Rq 1;
BA_ "GenSigStartValueInteger" SG_ 964 FohEng_D_Rq 2;
BA_ "U_U55X_MY2022_Rx" SG_ 964 EcoMode_B_Stat_UB 1;
BA_ "U_T6_MCA_MY2020_Rx" SG_ 964 EcoMode_B_Stat_UB 1;
BA_ "U_T6_MCA_MY2020_Rx" SG_ 964 Cta_D_Rq_UB 1;
BA_ "U_CX727_MY2021_Rx" SG_ 964 Cta_D_Rq_UB 1;
BA_ "U_T6_MCA_MY2020_Rx" SG_ 964 Cta_D_Rq 1;
BA_ "U_CX727_MY2021_Rx" SG_ 964 Cta_D_Rq 1;
BA_ "GenSigSendType" SG_ 964 Cta_D_Rq 3;
BA_ "GenSigStartValue" SG_ 964 Cta_D_Rq 1;
BA_ "GenSigStartValueInteger" SG_ 964 Cta_D_Rq 1;
BA_ "U_CD764_MY2022_Rx" SG_ 964 GearRvrse_D_Actl_UB 1;
BA_ "U_U55X_MY2022_Rx" SG_ 964 GearRvrse_D_Actl_UB 1;
BA_ "U_CD542_MY2021_Rx" SG_ 964 GearRvrse_D_Actl_UB 1;
BA_ "U_T6_MCA_MY2020_Rx" SG_ 964 GearRvrse_D_Actl_UB 1;
BA_ "U_P702_MY2021_Rx" SG_ 964 GearRvrse_D_Actl_UB 1;
BA_ "U_CX727_MY2021_Rx" SG_ 964 GearRvrse_D_Actl_UB 1;
BA_ "U_CD764_MY2022_Rx" SG_ 964 GearRvrse_D_Actl 1;
BA_ "U_U55X_MY2022_Rx" SG_ 964 GearRvrse_D_Actl 1;
BA_ "U_CD542_MY2021_Rx" SG_ 964 GearRvrse_D_Actl 1;
BA_ "U_T6_MCA_MY2020_Rx" SG_ 964 GearRvrse_D_Actl 1;
BA_ "U_P702_MY2021_Rx" SG_ 964 GearRvrse_D_Actl 1;
BA_ "U_CX727_MY2021_Rx" SG_ 964 GearRvrse_D_Actl 1;
BA_ "GenSigSendType" SG_ 964 GearRvrse_D_Actl 3;
BA_ "GenSigStartValue" SG_ 964 GearRvrse_D_Actl 7;
BA_ "GenSigStartValueInteger" SG_ 964 GearRvrse_D_Actl 7;
BA_ "U_T6_MCA_MY2020_Rx" SG_ 964 TurnLghtSwtch_D_Stat_UB 1;
BA_ "U_CX727_MY2021_Rx" SG_ 964 TurnLghtSwtch_D_Stat_UB 1;
BA_ "U_T6_MCA_MY2020_Rx" SG_ 964 TurnLghtSwtch_D_Stat 1;
BA_ "U_CX727_MY2021_Rx" SG_ 964 TurnLghtSwtch_D_Stat 1;
BA_ "GenSigSendType" SG_ 964 TurnLghtSwtch_D_Stat 3;
BA_ "WakeupSignal" SG_ 964 TurnLghtSwtch_D_Stat 1;
BA_ "U_U55X_MY2022_Rx" SG_ 964 Power_Liftgate_Mode_Cmd_UB 1;
BA_ "U_CD542_MY2021_Rx" SG_ 964 Power_Liftgate_Mode_Cmd_UB 1;
BA_ "U_T6_MCA_MY2020_Rx" SG_ 964 Power_Liftgate_Mode_Cmd_UB 1;
BA_ "U_CX727_MY2021_Rx" SG_ 964 Power_Liftgate_Mode_Cmd_UB 1;
BA_ "U_U55X_MY2022_Rx" SG_ 964 Power_Liftgate_Mode_Cmd 1;
BA_ "U_CD542_MY2021_Rx" SG_ 964 Power_Liftgate_Mode_Cmd 1;
BA_ "U_T6_MCA_MY2020_Rx" SG_ 964 Power_Liftgate_Mode_Cmd 1;
BA_ "U_CX727_MY2021_Rx" SG_ 964 Power_Liftgate_Mode_Cmd 1;
BA_ "GenSigSendType" SG_ 964 Power_Liftgate_Mode_Cmd 3;
BA_ "WakeupSignal" SG_ 964 Power_Liftgate_Mode_Cmd 1;
BA_ "U_U55X_MY2022_Rx" SG_ 964 EcoMode_B_Stat 1;
BA_ "U_T6_MCA_MY2020_Rx" SG_ 964 EcoMode_B_Stat 1;
BA_ "GenSigSendType" SG_ 964 EcoMode_B_Stat 3;
BA_ "U_CD764_MY2022_Rx" SG_ 964 MetricActvTe_B_Actl_UB 1;
BA_ "U_U55X_MY2022_Rx" SG_ 964 MetricActvTe_B_Actl_UB 1;
BA_ "U_CD542_MY2021_Rx" SG_ 964 MetricActvTe_B_Actl_UB 1;
BA_ "U_T6_MCA_MY2020_Rx" SG_ 964 MetricActvTe_B_Actl_UB 1;
BA_ "U_P702_MY2021_Rx" SG_ 964 MetricActvTe_B_Actl_UB 1;
BA_ "U_CX727_MY2021_Rx" SG_ 964 MetricActvTe_B_Actl_UB 1;
BA_ "U_CD764_MY2022_Rx" SG_ 964 MetricActvTe_B_Actl 1;
BA_ "U_U55X_MY2022_Rx" SG_ 964 MetricActvTe_B_Actl 1;
BA_ "U_CD542_MY2021_Rx" SG_ 964 MetricActvTe_B_Actl 1;
BA_ "U_T6_MCA_MY2020_Rx" SG_ 964 MetricActvTe_B_Actl 1;
BA_ "U_P702_MY2021_Rx" SG_ 964 MetricActvTe_B_Actl 1;
BA_ "U_CX727_MY2021_Rx" SG_ 964 MetricActvTe_B_Actl 1;
BA_ "GenSigSendType" SG_ 964 MetricActvTe_B_Actl 3;
BA_ "U_CD764_MY2022_Rx" SG_ 964 EngClntTe_D_Qf 1;
BA_ "U_U55X_MY2022_Rx" SG_ 964 EngClntTe_D_Qf 1;
BA_ "U_CD542_MY2021_Rx" SG_ 964 EngClntTe_D_Qf 1;
BA_ "U_T6_MCA_MY2020_Rx" SG_ 964 EngClntTe_D_Qf 1;
BA_ "U_P702_MY2021_Rx" SG_ 964 EngClntTe_D_Qf 1;
BA_ "U_CX727_MY2021_Rx" SG_ 964 EngClntTe_D_Qf 1;
BA_ "GenSigSendType" SG_ 964 EngClntTe_D_Qf 3;
BA_ "MetaData" SG_ 964 EngClntTe_D_Qf 1;
BA_ "U_T6_MCA_MY2020_Rx" SG_ 964 Sod_D_Rq 1;
BA_ "U_CX727_MY2021_Rx" SG_ 964 Sod_D_Rq 1;
BA_ "GenSigSendType" SG_ 964 Sod_D_Rq 3;
BA_ "GenSigStartValue" SG_ 964 Sod_D_Rq 2;
BA_ "GenSigStartValueInteger" SG_ 964 Sod_D_Rq 2;
BA_ "U_CD764_MY2022_Rx" SG_ 964 MetricActv_B_Actl 1;
BA_ "U_U55X_MY2022_Rx" SG_ 964 MetricActv_B_Actl 1;
BA_ "U_CD542_MY2021_Rx" SG_ 964 MetricActv_B_Actl 1;
BA_ "U_T6_MCA_MY2020_Rx" SG_ 964 MetricActv_B_Actl 1;
BA_ "U_P702_MY2021_Rx" SG_ 964 MetricActv_B_Actl 1;
BA_ "U_CX727_MY2021_Rx" SG_ 964 MetricActv_B_Actl 1;
BA_ "GenSigSendType" SG_ 964 MetricActv_B_Actl 3;
BA_ "U_CD764_MY2022_Rx" SG_ 964 EngClnt_Te_Actl 1;
BA_ "U_U55X_MY2022_Rx" SG_ 964 EngClnt_Te_Actl 1;
BA_ "U_CD542_MY2021_Rx" SG_ 964 EngClnt_Te_Actl 1;
BA_ "U_T6_MCA_MY2020_Rx" SG_ 964 EngClnt_Te_Actl 1;
BA_ "U_P702_MY2021_Rx" SG_ 964 EngClnt_Te_Actl 1;
BA_ "U_CX727_MY2021_Rx" SG_ 964 EngClnt_Te_Actl 1;
BA_ "GenSigSendType" SG_ 964 EngClnt_Te_Actl 3;
BA_ "U_CD764_MY2022_Rx" SG_ 964 MetricActv_B_Actl_UB 1;
BA_ "U_U55X_MY2022_Rx" SG_ 964 MetricActv_B_Actl_UB 1;
BA_ "U_CD542_MY2021_Rx" SG_ 964 MetricActv_B_Actl_UB 1;
BA_ "U_T6_MCA_MY2020_Rx" SG_ 964 MetricActv_B_Actl_UB 1;
BA_ "U_P702_MY2021_Rx" SG_ 964 MetricActv_B_Actl_UB 1;
BA_ "U_CX727_MY2021_Rx" SG_ 964 MetricActv_B_Actl_UB 1;
BA_ "U_CD764_MY2022_Rx" SG_ 964 EngClnt_Te_Actl_UB 1;
BA_ "U_U55X_MY2022_Rx" SG_ 964 EngClnt_Te_Actl_UB 1;
BA_ "U_CD542_MY2021_Rx" SG_ 964 EngClnt_Te_Actl_UB 1;
BA_ "U_T6_MCA_MY2020_Rx" SG_ 964 EngClnt_Te_Actl_UB 1;
BA_ "U_P702_MY2021_Rx" SG_ 964 EngClnt_Te_Actl_UB 1;
BA_ "U_CX727_MY2021_Rx" SG_ 964 EngClnt_Te_Actl_UB 1;
BA_ "U_CD542_MY2021_Rx" SG_ 964 OCSSensrDataUpperLim_UB 1;
BA_ "U_T6_MCA_MY2020_Rx" SG_ 964 OCSSensrDataUpperLim_UB 1;
BA_ "U_CX727_MY2021_Rx" SG_ 964 OCSSensrDataUpperLim_UB 1;
BA_ "U_CD764_MY2022_Rx" SG_ 964 OCSSensrDataUpperLim_UB 1;
BA_ "U_U55X_MY2022_Rx" SG_ 964 OCSSensrDataUpperLim_UB 1;
BA_ "U_P702_MY2021_Rx" SG_ 964 OCSSensrDataUpperLim_UB 1;
BA_ "U_CD542_MY2021_Rx" SG_ 964 OCSSensrDataUpperLim 1;
BA_ "U_T6_MCA_MY2020_Rx" SG_ 964 OCSSensrDataUpperLim 1;
BA_ "U_CX727_MY2021_Rx" SG_ 964 OCSSensrDataUpperLim 1;
BA_ "U_CD764_MY2022_Rx" SG_ 964 OCSSensrDataUpperLim 1;
BA_ "U_U55X_MY2022_Rx" SG_ 964 OCSSensrDataUpperLim 1;
BA_ "U_P702_MY2021_Rx" SG_ 964 OCSSensrDataUpperLim 1;
BA_ "GenSigSendType" SG_ 964 OCSSensrDataUpperLim 3;
BA_ "U_CD542_MY2021_Rx" SG_ 964 OCSSensrDataLowerLim_UB 1;
BA_ "U_T6_MCA_MY2020_Rx" SG_ 964 OCSSensrDataLowerLim_UB 1;
BA_ "U_CX727_MY2021_Rx" SG_ 964 OCSSensrDataLowerLim_UB 1;
BA_ "U_CD764_MY2022_Rx" SG_ 964 OCSSensrDataLowerLim_UB 1;
BA_ "U_U55X_MY2022_Rx" SG_ 964 OCSSensrDataLowerLim_UB 1;
BA_ "U_P702_MY2021_Rx" SG_ 964 OCSSensrDataLowerLim_UB 1;
BA_ "GenSigSendType" SG_ 964 PrkAid_D_Falt 3;
BA_ "U_CD542_MY2021_Rx" SG_ 964 OCSSensrDataLowerLim 1;
BA_ "U_T6_MCA_MY2020_Rx" SG_ 964 OCSSensrDataLowerLim 1;
BA_ "U_CX727_MY2021_Rx" SG_ 964 OCSSensrDataLowerLim 1;
BA_ "U_CD764_MY2022_Rx" SG_ 964 OCSSensrDataLowerLim 1;
BA_ "U_U55X_MY2022_Rx" SG_ 964 OCSSensrDataLowerLim 1;
BA_ "U_P702_MY2021_Rx" SG_ 964 OCSSensrDataLowerLim 1;
BA_ "GenSigSendType" SG_ 964 OCSSensrDataLowerLim 3;
BA_ "U_CD764_MY2022_Rx" SG_ 964 WiprFront_D_Stat_UB 1;
BA_ "U_U55X_MY2022_Rx" SG_ 964 WiprFront_D_Stat_UB 1;
BA_ "U_CD542_MY2021_Rx" SG_ 964 WiprFront_D_Stat_UB 1;
BA_ "U_P702_MY2021_Rx" SG_ 964 WiprFront_D_Stat_UB 1;
BA_ "U_T6_MCA_MY2020_Rx" SG_ 964 WiprFront_D_Stat_UB 1;
BA_ "U_CX727_MY2021_Rx" SG_ 964 WiprFront_D_Stat_UB 1;
BA_ "U_CD764_MY2022_Rx" SG_ 964 WiprFront_D_Stat 1;
BA_ "U_U55X_MY2022_Rx" SG_ 964 WiprFront_D_Stat 1;
BA_ "U_CD542_MY2021_Rx" SG_ 964 WiprFront_D_Stat 1;
BA_ "U_P702_MY2021_Rx" SG_ 964 WiprFront_D_Stat 1;
BA_ "U_T6_MCA_MY2020_Rx" SG_ 964 WiprFront_D_Stat 1;
BA_ "U_CX727_MY2021_Rx" SG_ 964 WiprFront_D_Stat 1;
BA_ "GenSigSendType" SG_ 964 WiprFront_D_Stat 3;
BA_ "GenSigStartValue" SG_ 964 WiprFront_D_Stat 15;
BA_ "GenSigStartValueInteger" SG_ 964 WiprFront_D_Stat 15;
BA_ "U_CD764_MY2022_Rx" SG_ 964 CamraDefog_B_Req_UB 1;
BA_ "U_U55X_MY2022_Rx" SG_ 964 CamraDefog_B_Req_UB 1;
BA_ "U_CD542_MY2021_Rx" SG_ 964 CamraDefog_B_Req_UB 1;
BA_ "U_CX727_MY2021_Rx" SG_ 964 CamraDefog_B_Req_UB 1;
BA_ "U_T6_MCA_MY2020_Rx" SG_ 964 Sod_D_Rq_UB 1;
BA_ "U_CX727_MY2021_Rx" SG_ 964 Sod_D_Rq_UB 1;
BA_ "U_CD764_MY2022_Rx" SG_ 964 CamraDefog_B_Req 1;
BA_ "U_U55X_MY2022_Rx" SG_ 964 CamraDefog_B_Req 1;
BA_ "U_CD542_MY2021_Rx" SG_ 964 CamraDefog_B_Req 1;
BA_ "U_CX727_MY2021_Rx" SG_ 964 CamraDefog_B_Req 1;
BA_ "GenSigSendType" SG_ 964 CamraDefog_B_Req 3;
BA_ "U_CD764_MY2022_Rx" SG_ 1843 TesterPhysicalReqHVAC_RCCM 1;
BA_ "U_U55X_MY2022_Rx" SG_ 1843 TesterPhysicalReqHVAC_RCCM 1;
BA_ "U_CD542_MY2021_Rx" SG_ 1843 TesterPhysicalReqHVAC_RCCM 1;
BA_ "U_T6_MCA_MY2020_Rx" SG_ 1843 TesterPhysicalReqHVAC_RCCM 1;
BA_ "U_P702_MY2021_Rx" SG_ 1843 TesterPhysicalReqHVAC_RCCM 1;
BA_ "U_CX727_MY2021_Rx" SG_ 1843 TesterPhysicalReqHVAC_RCCM 1;
BA_ "GenSigSendType" SG_ 1843 TesterPhysicalReqHVAC_RCCM 3;
BA_ "U_CD764_MY2022_Tx" SG_ 1851 TesterPhysicalResHVAC_RCCM 1;
BA_ "U_U55X_MY2022_Tx" SG_ 1851 TesterPhysicalResHVAC_RCCM 1;
BA_ "U_CD542_MY2021_Tx" SG_ 1851 TesterPhysicalResHVAC_RCCM 1;
BA_ "U_T6_MCA_MY2020_Tx" SG_ 1851 TesterPhysicalResHVAC_RCCM 1;
BA_ "U_P702_MY2021_Tx" SG_ 1851 TesterPhysicalResHVAC_RCCM 1;
BA_ "U_CX727_MY2021_Tx" SG_ 1851 TesterPhysicalResHVAC_RCCM 1;
BA_ "GenSigSendType" SG_ 1851 TesterPhysicalResHVAC_RCCM 3;
BA_ "U_CD764_MY2022_Tx" SG_ 1411 HVAC_GWOnBoardTester 1;
BA_ "U_U55X_MY2022_Tx" SG_ 1411 HVAC_GWOnBoardTester 1;
BA_ "U_CD542_MY2021_Tx" SG_ 1411 HVAC_GWOnBoardTester 1;
BA_ "U_T6_MCA_MY2020_Tx" SG_ 1411 HVAC_GWOnBoardTester 1;
BA_ "U_P702_MY2021_Tx" SG_ 1411 HVAC_GWOnBoardTester 1;
BA_ "U_CX727_MY2021_Tx" SG_ 1411 HVAC_GWOnBoardTester 1;
BA_ "GenSigStartValue" SG_ 1411 HVAC_GWOnBoardTester 255;
BA_ "ContentDependant" SG_ 1411 HVAC_GWOnBoardTester 1;
BA_ "GenSigStartValueInteger" SG_ 1411 HVAC_GWOnBoardTester 255;
BA_ "U_CD764_MY2022_Tx" SG_ 1411 HVAC_GWNMProxy 1;
BA_ "U_U55X_MY2022_Tx" SG_ 1411 HVAC_GWNMProxy 1;
BA_ "U_CD542_MY2021_Tx" SG_ 1411 HVAC_GWNMProxy 1;
BA_ "U_T6_MCA_MY2020_Tx" SG_ 1411 HVAC_GWNMProxy 1;
BA_ "U_P702_MY2021_Tx" SG_ 1411 HVAC_GWNMProxy 1;
BA_ "U_CX727_MY2021_Tx" SG_ 1411 HVAC_GWNMProxy 1;
BA_ "GenSigStartValue" SG_ 1411 HVAC_GWNMProxy 255;
BA_ "ContentDependant" SG_ 1411 HVAC_GWNMProxy 1;
BA_ "GenSigStartValueInteger" SG_ 1411 HVAC_GWNMProxy 255;
BA_ "U_CD764_MY2022_Tx" SG_ 1411 HVAC_AutoSarNMReserved4 1;
BA_ "U_U55X_MY2022_Tx" SG_ 1411 HVAC_AutoSarNMReserved4 1;
BA_ "U_CD542_MY2021_Tx" SG_ 1411 HVAC_AutoSarNMReserved4 1;
BA_ "U_T6_MCA_MY2020_Tx" SG_ 1411 HVAC_AutoSarNMReserved4 1;
BA_ "U_P702_MY2021_Tx" SG_ 1411 HVAC_AutoSarNMReserved4 1;
BA_ "U_CX727_MY2021_Tx" SG_ 1411 HVAC_AutoSarNMReserved4 1;
BA_ "GenSigStartValue" SG_ 1411 HVAC_AutoSarNMReserved4 255;
BA_ "ContentDependant" SG_ 1411 HVAC_AutoSarNMReserved4 1;
BA_ "GenSigStartValueInteger" SG_ 1411 HVAC_AutoSarNMReserved4 255;
BA_ "U_CD764_MY2022_Tx" SG_ 1411 HVAC_AutoSarNMReserved3 1;
BA_ "U_U55X_MY2022_Tx" SG_ 1411 HVAC_AutoSarNMReserved3 1;
BA_ "U_CD542_MY2021_Tx" SG_ 1411 HVAC_AutoSarNMReserved3 1;
BA_ "U_T6_MCA_MY2020_Tx" SG_ 1411 HVAC_AutoSarNMReserved3 1;
BA_ "U_P702_MY2021_Tx" SG_ 1411 HVAC_AutoSarNMReserved3 1;
BA_ "U_CX727_MY2021_Tx" SG_ 1411 HVAC_AutoSarNMReserved3 1;
BA_ "GenSigStartValue" SG_ 1411 HVAC_AutoSarNMReserved3 255;
BA_ "ContentDependant" SG_ 1411 HVAC_AutoSarNMReserved3 1;
BA_ "GenSigStartValueInteger" SG_ 1411 HVAC_AutoSarNMReserved3 255;
BA_ "U_CD764_MY2022_Tx" SG_ 1411 HVAC_AutoSarNMReserved2 1;
BA_ "U_U55X_MY2022_Tx" SG_ 1411 HVAC_AutoSarNMReserved2 1;
BA_ "U_CD542_MY2021_Tx" SG_ 1411 HVAC_AutoSarNMReserved2 1;
BA_ "U_T6_MCA_MY2020_Tx" SG_ 1411 HVAC_AutoSarNMReserved2 1;
BA_ "U_P702_MY2021_Tx" SG_ 1411 HVAC_AutoSarNMReserved2 1;
BA_ "U_CX727_MY2021_Tx" SG_ 1411 HVAC_AutoSarNMReserved2 1;
BA_ "GenSigStartValue" SG_ 1411 HVAC_AutoSarNMReserved2 255;
BA_ "ContentDependant" SG_ 1411 HVAC_AutoSarNMReserved2 1;
BA_ "GenSigStartValueInteger" SG_ 1411 HVAC_AutoSarNMReserved2 255;
BA_ "U_CD764_MY2022_Tx" SG_ 1411 HVAC_AutoSarNMReserved 1;
BA_ "U_U55X_MY2022_Tx" SG_ 1411 HVAC_AutoSarNMReserved 1;
BA_ "U_CD542_MY2021_Tx" SG_ 1411 HVAC_AutoSarNMReserved 1;
BA_ "U_T6_MCA_MY2020_Tx" SG_ 1411 HVAC_AutoSarNMReserved 1;
BA_ "U_P702_MY2021_Tx" SG_ 1411 HVAC_AutoSarNMReserved 1;
BA_ "U_CX727_MY2021_Tx" SG_ 1411 HVAC_AutoSarNMReserved 1;
BA_ "GenSigStartValue" SG_ 1411 HVAC_AutoSarNMReserved 255;
BA_ "ContentDependant" SG_ 1411 HVAC_AutoSarNMReserved 1;
BA_ "GenSigStartValueInteger" SG_ 1411 HVAC_AutoSarNMReserved 255;
BA_ "U_CD764_MY2022_Tx" SG_ 1411 HVAC_AutoSarNMNodeId 1;
BA_ "U_U55X_MY2022_Tx" SG_ 1411 HVAC_AutoSarNMNodeId 1;
BA_ "U_CD542_MY2021_Tx" SG_ 1411 HVAC_AutoSarNMNodeId 1;
BA_ "U_T6_MCA_MY2020_Tx" SG_ 1411 HVAC_AutoSarNMNodeId 1;
BA_ "U_P702_MY2021_Tx" SG_ 1411 HVAC_AutoSarNMNodeId 1;
BA_ "U_CX727_MY2021_Tx" SG_ 1411 HVAC_AutoSarNMNodeId 1;
BA_ "GenSigStartValue" SG_ 1411 HVAC_AutoSarNMNodeId 131;
BA_ "ContentDependant" SG_ 1411 HVAC_AutoSarNMNodeId 1;
BA_ "GenSigStartValueInteger" SG_ 1411 HVAC_AutoSarNMNodeId 83;
BA_ "U_CD764_MY2022_Tx" SG_ 1411 HVAC_AutoSarNMControl 1;
BA_ "U_U55X_MY2022_Tx" SG_ 1411 HVAC_AutoSarNMControl 1;
BA_ "U_CD542_MY2021_Tx" SG_ 1411 HVAC_AutoSarNMControl 1;
BA_ "U_T6_MCA_MY2020_Tx" SG_ 1411 HVAC_AutoSarNMControl 1;
BA_ "U_P702_MY2021_Tx" SG_ 1411 HVAC_AutoSarNMControl 1;
BA_ "U_CX727_MY2021_Tx" SG_ 1411 HVAC_AutoSarNMControl 1;
BA_ "ContentDependant" SG_ 1411 HVAC_AutoSarNMControl 1;
BA_ "U_CD764_MY2022_Tx" SG_ 993 StmsScrnDrvOn_B_Rq 1;
BA_ "GenSigSendType" SG_ 993 StmsScrnDrvOn_B_Rq 3;
BA_ "U_CD764_MY2022_Tx" SG_ 993 EmButtn_D_Stat 1;
BA_ "U_U55X_MY2022_Tx" SG_ 993 EmButtn_D_Stat 1;
BA_ "U_CD542_MY2021_Tx" SG_ 993 EmButtn_D_Stat 1;
BA_ "U_T6_MCA_MY2020_Tx" SG_ 993 EmButtn_D_Stat 1;
BA_ "U_P702_MY2021_Tx" SG_ 993 EmButtn_D_Stat 1;
BA_ "U_CX727_MY2021_Tx" SG_ 993 EmButtn_D_Stat 1;
BA_ "GenSigSendType" SG_ 993 EmButtn_D_Stat 3;
BA_ "U_CD542_MY2021_Tx" SG_ 993 MemStoreMsgTxt_D_Rq 1;
BA_ "U_T6_MCA_MY2020_Tx" SG_ 993 MemStoreMsgTxt_D_Rq 1;
BA_ "GenSigSendType" SG_ 993 MemStoreMsgTxt_D_Rq 3;
BA_ "GenSigSendType" SG_ 993 MemSetButtnMsgTxt_D_Rq 3;
BA_ "U_CD764_MY2022_Tx" SG_ 993 PersStore_D_Actl 1;
BA_ "U_U55X_MY2022_Tx" SG_ 993 PersStore_D_Actl 1;
BA_ "U_CD542_MY2021_Tx" SG_ 993 PersStore_D_Actl 1;
BA_ "U_T6_MCA_MY2020_Tx" SG_ 993 PersStore_D_Actl 1;
BA_ "U_P702_MY2021_Tx" SG_ 993 PersStore_D_Actl 1;
BA_ "U_CX727_MY2021_Tx" SG_ 993 PersStore_D_Actl 1;
BA_ "GenSigSendType" SG_ 993 PersStore_D_Actl 3;
BA_ "U_CD764_MY2022_Tx" SG_ 993 MemSwtch_D_RqRecall 1;
BA_ "U_U55X_MY2022_Tx" SG_ 993 MemSwtch_D_RqRecall 1;
BA_ "U_CD542_MY2021_Tx" SG_ 993 MemSwtch_D_RqRecall 1;
BA_ "U_T6_MCA_MY2020_Tx" SG_ 993 MemSwtch_D_RqRecall 1;
BA_ "U_P702_MY2021_Tx" SG_ 993 MemSwtch_D_RqRecall 1;
BA_ "U_CX727_MY2021_Tx" SG_ 993 MemSwtch_D_RqRecall 1;
BA_ "U_U55X_MY2022_Rx" SG_ 993 MemSwtch_D_RqRecall 1;
BA_ "GenSigSendType" SG_ 993 MemSwtch_D_RqRecall 3;
BA_ "WakeupSignal" SG_ 993 MemSwtch_D_RqRecall 1;
BA_ "U_CD764_MY2022_Tx" SG_ 993 MemSwtch_D_RqAssoc 1;
BA_ "U_U55X_MY2022_Tx" SG_ 993 MemSwtch_D_RqAssoc 1;
BA_ "U_CD542_MY2021_Tx" SG_ 993 MemSwtch_D_RqAssoc 1;
BA_ "U_T6_MCA_MY2020_Tx" SG_ 993 MemSwtch_D_RqAssoc 1;
BA_ "U_P702_MY2021_Tx" SG_ 993 MemSwtch_D_RqAssoc 1;
BA_ "U_CX727_MY2021_Tx" SG_ 993 MemSwtch_D_RqAssoc 1;
BA_ "GenSigSendType" SG_ 993 MemSwtch_D_RqAssoc 3;
BA_ "WakeupSignal" SG_ 993 MemSwtch_D_RqAssoc 1;
BA_ "U_CD764_MY2022_Tx" SG_ 993 PersIndexDsm_D_Actl 1;
BA_ "U_U55X_MY2022_Tx" SG_ 993 PersIndexDsm_D_Actl 1;
BA_ "U_CD542_MY2021_Tx" SG_ 993 PersIndexDsm_D_Actl 1;
BA_ "U_T6_MCA_MY2020_Tx" SG_ 993 PersIndexDsm_D_Actl 1;
BA_ "U_P702_MY2021_Tx" SG_ 993 PersIndexDsm_D_Actl 1;
BA_ "U_CX727_MY2021_Tx" SG_ 993 PersIndexDsm_D_Actl 1;
BA_ "GenSigSendType" SG_ 993 PersIndexDsm_D_Actl 3;
BA_ "GenSigStartValue" SG_ 993 PersIndexDsm_D_Actl 4;
BA_ "GenSigStartValueInteger" SG_ 993 PersIndexDsm_D_Actl 4;
BA_ "U_CD764_MY2022_Tx" SG_ 993 FeatNoDsmActl 1;
BA_ "U_U55X_MY2022_Tx" SG_ 993 FeatNoDsmActl 1;
BA_ "U_CD542_MY2021_Tx" SG_ 993 FeatNoDsmActl 1;
BA_ "U_T6_MCA_MY2020_Tx" SG_ 993 FeatNoDsmActl 1;
BA_ "U_P702_MY2021_Tx" SG_ 993 FeatNoDsmActl 1;
BA_ "U_CX727_MY2021_Tx" SG_ 993 FeatNoDsmActl 1;
BA_ "GenSigSendType" SG_ 993 FeatNoDsmActl 3;
BA_ "U_CD764_MY2022_Tx" SG_ 993 FeatConfigDsmActl 1;
BA_ "U_U55X_MY2022_Tx" SG_ 993 FeatConfigDsmActl 1;
BA_ "U_CD542_MY2021_Tx" SG_ 993 FeatConfigDsmActl 1;
BA_ "U_T6_MCA_MY2020_Tx" SG_ 993 FeatConfigDsmActl 1;
BA_ "U_P702_MY2021_Tx" SG_ 993 FeatConfigDsmActl 1;
BA_ "U_CX727_MY2021_Tx" SG_ 993 FeatConfigDsmActl 1;
BA_ "GenSigSendType" SG_ 993 FeatConfigDsmActl 3;
BA_ "U_U55X_MY2022_Tx" SG_ 1881 TesterPhysicalResRTM 1;
BA_ "U_T6_MCA_MY2020_Tx" SG_ 1881 TesterPhysicalResRTM 1;
BA_ "U_P702_MY2021_Tx" SG_ 1881 TesterPhysicalResRTM 1;
BA_ "U_CX727_MY2021_Tx" SG_ 1881 TesterPhysicalResRTM 1;
BA_ "GenSigSendType" SG_ 1881 TesterPhysicalResRTM 3;
BA_ "U_U55X_MY2022_Rx" SG_ 1873 TesterPhysicalReqRTM 1;
BA_ "U_T6_MCA_MY2020_Rx" SG_ 1873 TesterPhysicalReqRTM 1;
BA_ "U_P702_MY2021_Rx" SG_ 1873 TesterPhysicalReqRTM 1;
BA_ "U_CX727_MY2021_Rx" SG_ 1873 TesterPhysicalReqRTM 1;
BA_ "GenSigSendType" SG_ 1873 TesterPhysicalReqRTM 3;
VAL_ 839 FohStop_B_Stat 3 "Unknown" 2 "NotUsed" 1 "Enable" 0 "Disable" ;
VAL_ 839 FohMsgTxt_D_Rq 4 "BatteryNotFullyCharged" 3 "Exceed7DaysFromLastEngRun" 2 "AmbientTemperatureTooHigh" 1 "LowFuel" 0 "NoMessage" ;
VAL_ 839 FohKeyOff_B_Rq 1 "Enable" 0 "Disable" ;
VAL_ 839 FohEnbl_B_Rq 1 "Enable" 0 "Disable" ;
VAL_ 839 FohTAllEnable_B_Stat 3 "Unknown" 2 "NotUsed" 1 "Enable" 0 "Disable" ;
VAL_ 839 FohT2Enable_B_Stat 1 "Enable" 0 "Disable" ;
VAL_ 839 FohT1Enable_B_Stat 1 "Enable" 0 "Disable" ;
VAL_ 839 FohStrtEnable_B_Stat 1 "Enable" 0 "Disable" ;
VAL_ 839 FohContOn_B_Stat 3 "Unknown" 2 "NotUsed" 1 "Enable" 0 "Disable" ;
VAL_ 839 FohStrtDay_T_Stat 7 "Sunday" 6 "Saturday" 5 "Friday" 4 "Thursday" 3 "Wednesday" 2 "Tuesday" 1 "Monday" 0 "NotUsed" ;
VAL_ 839 FohT2Wednesday_T_Stat 1 "Enable" 0 "Disable" ;
VAL_ 839 FohT2Tuesday_T_Stat 1 "Enable" 0 "Disable" ;
VAL_ 839 FohT2Thursday_T_Stat 1 "Enable" 0 "Disable" ;
VAL_ 839 FohT2Sunday_T_Stat 1 "Enable" 0 "Disable" ;
VAL_ 839 FohT2Saturday_T_Stat 1 "Enable" 0 "Disable" ;
VAL_ 839 FohT2Monday_T_Stat 1 "Enable" 0 "Disable" ;
VAL_ 839 FohT2Friday_T_Stat 1 "Enable" 0 "Disable" ;
VAL_ 839 FohT1Wednesday_T_Stat 1 "Enable" 0 "Disable" ;
VAL_ 839 FohT1Tuesday_T_Stat 1 "Enable" 0 "Disable" ;
VAL_ 839 FohT1Thursday_T_Stat 1 "Enable" 0 "Disable" ;
VAL_ 839 FohT1Sunday_T_Stat 1 "Enable" 0 "Disable" ;
VAL_ 839 FohT1Saturday_T_Stat 1 "Enable" 0 "Disable" ;
VAL_ 839 FohT1Monday_T_Stat 1 "Enable" 0 "Disable" ;
VAL_ 839 FohT1Friday_T_Stat 1 "Enable" 0 "Disable" ;
VAL_ 838 FohStrtDay_T_Rq 7 "Sunday" 6 "Saturday" 5 "Friday" 4 "Thursday" 3 "Wednesday" 2 "Tuesday" 1 "Monday" 0 "NotUsed" ;
VAL_ 838 FohStop_B_Rq 3 "Unknown" 2 "NotUsed" 1 "Enable" 0 "Disable" ;
VAL_ 838 FohTAllEnable_B_Rq 3 "Unknown" 2 "NotUsed" 1 "Enable" 0 "Disable" ;
VAL_ 838 FohT2Enable_B_Rq 1 "Enable" 0 "Disable" ;
VAL_ 838 FohT1Enable_B_Rq 1 "Enable" 0 "Disable" ;
VAL_ 838 FohStrtEnable_B_Rq 1 "Enable" 0 "Disable" ;
VAL_ 838 FohContOn_B_Rq 3 "Unknown" 2 "NotUsed" 1 "Enable" 0 "Disable" ;
VAL_ 850 SeatCshnPsgrRR_Pc_Actl 127 "Null" ;
VAL_ 850 SeatCshnPsgrRL_Pc_Actl 127 "Null" ;
VAL_ 850 SeatCshnPsgrFR_Pc_Actl 127 "Null" ;
VAL_ 850 SeatCshnPsgrFL_Pc_Actl 127 "Null" ;
VAL_ 850 SeatBlLoPsgr_Pc_Actl2 127 "Null" ;
VAL_ 849 SeatCshnDrvRR_Pc_Actl 127 "Null" ;
VAL_ 849 SeatCshnDrvRL_Pc_Actl 127 "Null" ;
VAL_ 849 SeatCshnDrvFR_Pc_Actl 127 "Null" ;
VAL_ 849 SeatCshnDrvFL_Pc_Actl 127 "Null" ;
VAL_ 846 SeatMasgDrv_D_Rq 15 "NotUsed_10" 14 "NotUsed_9" 13 "NotUsed_8" 12 "NotUsed_7" 11 "NotUsed_6" 10 "Pattern10" 9 "Pattern9" 8 "Pattern8" 7 "Pattern7" 6 "Pattern6" 5 "Pattern5" 4 "Pattern4" 3 "Pattern3" 2 "Pattern2" 1 "Pattern1" 0 "Null" ;
VAL_ 846 SeatMasgPsngr_D_Rq 15 "NotUsed_10" 14 "NotUsed_9" 13 "NotUsed_8" 12 "NotUsed_7" 11 "NotUsed_6" 10 "Pattern10" 9 "Pattern9" 8 "Pattern8" 7 "Pattern7" 6 "Pattern6" 5 "Pattern5" 4 "Pattern4" 3 "Pattern3" 2 "Pattern2" 1 "Pattern1" 0 "Null" ;
VAL_ 846 SeatLmbr_D_Rq 15 "NotUsed_7" 14 "NotUsed_6" 13 "NotUsed_5" 12 "NotUsed_4" 11 "NotUsed_3" 10 "NotUsed_2" 9 "NotUsed_1" 8 "PassengerDown" 7 "PassengerUp" 6 "PassengerAft" 5 "PassengerFore" 4 "DriverDown" 3 "DriverUp" 2 "DriverAft" 1 "DriverFore" 0 "Null" ;
VAL_ 846 SeatFnChngPsgr2_D_Rq 15 "Faulty" 14 "NotUsed9" 13 "NotUsed8" 12 "NotUsed7" 11 "NotUsed6" 10 "High_2" 9 "Med_2" 8 "Low_2" 7 "Off_2" 6 "High" 5 "Low" 4 "Off" 3 "Decrease" 2 "Increase" 1 "NotUsed1" 0 "Inactive" ;
VAL_ 846 SeatFnChngDrv2_D_Rq 15 "Faulty" 14 "NotUsed9" 13 "NotUsed8" 12 "NotUsed7" 11 "NotUsed6" 10 "High_2" 9 "Med_2" 8 "Low_2" 7 "Off_2" 6 "High" 5 "Low" 4 "Off" 3 "Decrease" 2 "Increase" 1 "NotUsed1" 0 "Inactive" ;
VAL_ 846 SeatFnPsgr_D_Rq 7 "CushionMassage" 6 "LumbarMassage" 5 "UpperBolster" 4 "LowerBolster" 3 "UpperLumbar" 2 "MiddleLumbar" 1 "LowerLumbar" 0 "Inactive" ;
VAL_ 846 SeatFnDrv_D_Rq 7 "CushionMassage" 6 "LumbarMassage" 5 "UpperBolster" 4 "LowerBolster" 3 "UpperLumbar" 2 "MiddleLumbar" 1 "LowerLumbar" 0 "Inactive" ;
VAL_ 846 SeatFnDfaltPsgr_B_Rq 1 "Active" 0 "Inactive" ;
VAL_ 846 SeatFnDfaltDrv_B_Rq 1 "Active" 0 "Inactive" ;
VAL_ 846 SeatFnChngPsgr_D_Rq 2 "Decrease" 1 "Increase" 0 "Inactive" ;
VAL_ 846 SeatFnChngDrv_D_Rq 2 "Decrease" 1 "Increase" 0 "Inactive" ;
VAL_ 846 PsgrMemory_Rq 8 "Recall_4" 7 "Recall_3" 6 "Recall_2" 5 "Recall_1" 4 "Store_4" 3 "Store_3" 2 "Store_2" 1 "Store_1" 0 "Inactive" ;
VAL_ 868 E_Frt_Btn_Status_2nd 63 "NotUsed_10" 62 "NotUsed_9" 61 "NotUsed_8" 60 "NotUsed_7" 59 "NotUsed_6" 58 "NotUsed_5" 57 "NotUsed_4" 56 "NotUsed_3" 55 "NotUsed_2" 54 "NotUsed_1" 53 "RHS_Cld_Seat3_Pressed" 52 "RHS_Cld_Seat2_Pressed" 51 "RHS_Cld_Seat1_Pressed" 50 "LHS_Cld_Seat3_Pressed" 49 "LHS_Cld_Seat2_Pressed" 48 "LHS_Cld_Seat1_Pressed" 47 "RHS_Auto_Seat_Pressed" 46 "RHS_Htd_Seat3_Pressed" 45 "RHS_Htd_Seat2_Pressed" 44 "RHS_Htd_Seat1_Pressed" 43 "RHS_Seat_Off_Pressed" 42 "LHS_Auto_Seat_Pressed" 41 "LHS_Htd_Seat3_Pressed" 40 "LHS_Htd_Seat2_Pressed" 39 "LHS_Htd_Seat1_Pressed" 38 "LHS_Seat_Off_Pressed" 37 "DrvrFcsdMde_Pressed" 36 "MdeMnu_Pressed" 35 "AAR_Pressed" 34 "Heat_Pressed" 33 "RearMnu_Pressed" 32 "FrontMnu_Pressed" 31 "Defrost_Pressed" 30 "Htg_Strg_Whl_Pressed" 29 "RHS_Cld_Seat_Pressed" 28 "LHS_Cld_Seat_Pressed" 27 "RHS_Htd_Seat_Pressed" 26 "LHS_Htd_Seat_Pressed" 25 "Max_Defrost_Pressed" 24 "My_Temp_Pressed" 23 "Front_Power_Pressed" 22 "Rear_Defrost_Pressed" 21 "Pnl_Flr_Ws_Pressed" 20 "Pnl_Ws_Pressed" 19 "Windscreen_Pressed" 18 "Htd_Frt_Wsh_Pressed" 17 "Auto_Recirc_Pressed" 16 "Outside_Pressed" 15 "Recirc_Pressed" 14 "Max_AC_Pressed" 13 "Auto_Pressed" 12 "Blwr_Dec_Pressed" 11 "Blwr_Inc_Pressed" 10 "RHS_Temp_Dec_Pressed" 9 "RHS_Temp_Inc_Pressed" 8 "LHS_Temp_Dec_Pressed" 7 "LHS_Temp_Inc_Pressed" 6 "Dual_Pressed" 5 "AC_Pressed" 4 "Floor_Ws_Pressed" 3 "Floor_Pressed" 2 "Panel_Floor_Pressed" 1 "Panel_Pressed" 0 "None_Pressed" ;
VAL_ 868 E_Frt_Btn_Status_1st 63 "NotUsed_10" 62 "NotUsed_9" 61 "NotUsed_8" 60 "NotUsed_7" 59 "NotUsed_6" 58 "NotUsed_5" 57 "NotUsed_4" 56 "NotUsed_3" 55 "NotUsed_2" 54 "NotUsed_1" 53 "RHS_Cld_Seat3_Pressed" 52 "RHS_Cld_Seat2_Pressed" 51 "RHS_Cld_Seat1_Pressed" 50 "LHS_Cld_Seat3_Pressed" 49 "LHS_Cld_Seat2_Pressed" 48 "LHS_Cld_Seat1_Pressed" 47 "RHS_Auto_Seat_Pressed" 46 "RHS_Htd_Seat3_Pressed" 45 "RHS_Htd_Seat2_Pressed" 44 "RHS_Htd_Seat1_Pressed" 43 "RHS_Seat_Off_Pressed" 42 "LHS_Auto_Seat_Pressed" 41 "LHS_Htd_Seat3_Pressed" 40 "LHS_Htd_Seat2_Pressed" 39 "LHS_Htd_Seat1_Pressed" 38 "LHS_Seat_Off_Pressed" 37 "DrvrFcsdMde_Pressed" 36 "MdeMnu_Pressed" 35 "AAR_Pressed" 34 "Heat_Pressed" 33 "RearMnu_Pressed" 32 "FrontMnu_Pressed" 31 "Defrost_Pressed" 30 "Htg_Strg_Whl_Pressed" 29 "RHS_Cld_Seat_Pressed" 28 "LHS_Cld_Seat_Pressed" 27 "RHS_Htd_Seat_Pressed" 26 "LHS_Htd_Seat_Pressed" 25 "Max_Defrost_Pressed" 24 "My_Temp_Pressed" 23 "Front_Power_Pressed" 22 "Rear_Defrost_Pressed" 21 "Pnl_Flr_Ws_Pressed" 20 "Pnl_Ws_Pressed" 19 "Windscreen_Pressed" 18 "Htd_Frt_Wsh_Pressed" 17 "Auto_Recirc_Pressed" 16 "Outside_Pressed" 15 "Recirc_Pressed" 14 "Max_AC_Pressed" 13 "Auto_Pressed" 12 "Blwr_Dec_Pressed" 11 "Blwr_Inc_Pressed" 10 "RHS_Temp_Dec_Pressed" 9 "RHS_Temp_Inc_Pressed" 8 "LHS_Temp_Dec_Pressed" 7 "LHS_Temp_Inc_Pressed" 6 "Dual_Pressed" 5 "AC_Pressed" 4 "Floor_Ws_Pressed" 3 "Floor_Pressed" 2 "Panel_Floor_Pressed" 1 "Panel_Pressed" 0 "None_Pressed" ;
VAL_ 868 Rr_Blower_Indicate_Stat 15 "Display_Blank" 14 "14_Indicators_On" 13 "13_Indicators_On" 12 "12_Indicators_On" 11 "11_Indicators_On" 10 "10_Indicators_On" 9 "9_Indicators_On" 8 "8_Indicators_On" 7 "7_Indicators_On" 6 "6_Indicators_On" 5 "5_Indicators_On" 4 "4_Indicators_On" 3 "3_Indicators_On" 2 "2_Indicators_On" 1 "1_Indicator_On" 0 "Indicators_Off" ;
VAL_ 845 SeatMasgPsngr_D_Stat 15 "NotUsed_10" 14 "NotUsed_9" 13 "NotUsed_8" 12 "NotUsed_7" 11 "NotUsed_6" 10 "Pattern10" 9 "Pattern9" 8 "Pattern8" 7 "Pattern7" 6 "Pattern6" 5 "Pattern5" 4 "Pattern4" 3 "Pattern3" 2 "Pattern2" 1 "Pattern1" 0 "Null" ;
VAL_ 845 SeatIntnsPsngr_D_Stat 7 "NotUsed_3" 6 "NotUsed_2" 5 "NotUsed_1" 4 "High" 3 "Medium" 2 "Low" 1 "Off" 0 "Null" ;
VAL_ 845 StmsLmbrPsgr_D_Stat 3 "High" 2 "Low" 1 "Off" 0 "Null" ;
VAL_ 845 StmsCshnPsgr_D_Stat 3 "High" 2 "Low" 1 "Off" 0 "Null" ;
VAL_ 845 SeatSwtchPsgr_B_Stat 1 "On" 0 "Off" ;
VAL_ 845 SeatPPsgr_B_Stat 1 "Updating" 0 "NotUpdating" ;
VAL_ 845 SeatFnPsgr_D_Stat 7 "CushionMassage" 6 "LumbarMassage" 5 "UpperBolster" 4 "LowerBolster" 3 "UpperLumbar" 2 "MiddleLumbar" 1 "LowerLumbar" 0 "Null" ;
VAL_ 845 PsgrMemFeedback_Rsp 8 "Recall_4" 7 "Recall_3" 6 "Recall_2" 5 "Recall_1" 4 "Store_4" 3 "Store_3" 2 "Store_2" 1 "Store_1" 0 "Inactive" ;
VAL_ 844 SeatMasgDrv_D_Stat 15 "NotUsed_10" 14 "NotUsed_9" 13 "NotUsed_8" 12 "NotUsed_7" 11 "NotUsed_6" 10 "Pattern10" 9 "Pattern9" 8 "Pattern8" 7 "Pattern7" 6 "Pattern6" 5 "Pattern5" 4 "Pattern4" 3 "Pattern3" 2 "Pattern2" 1 "Pattern1" 0 "Null" ;
VAL_ 844 SeatIntnsDrv_D_Stat 7 "NotUsed_3" 6 "NotUsed_2" 5 "NotUsed_1" 4 "High" 3 "Medium" 2 "Low" 1 "Off" 0 "Null" ;
VAL_ 844 StmsLmbrDrv_D_Stat 3 "High" 2 "Low" 1 "Off" 0 "Null" ;
VAL_ 844 StmsCshnDrv_D_Stat 3 "High" 2 "Low" 1 "Off" 0 "Null" ;
VAL_ 844 SeatSwtchDrv_B_Stat 1 "On" 0 "Off" ;
VAL_ 844 SeatFnDrv_D_Stat 7 "CushionMassage" 6 "LumbarMassage" 5 "UpperBolster" 4 "LowerBolster" 3 "UpperLumbar" 2 "MiddleLumbar" 1 "LowerLumbar" 0 "Null" ;
VAL_ 844 SeatPDrv_B_Stat 1 "Updating" 0 "NotUpdating" ;
VAL_ 843 SeatBlUpPsgr_Pc_Actl 127 "Null" ;
VAL_ 843 SeatBlLoPsgr_Pc_Actl 127 "Null" ;
VAL_ 842 SeatBlUpDrv_Pc_Actl 127 "Null" ;
VAL_ 842 SeatBlLoDrv_Pc_Actl 127 "Null" ;
VAL_ 958 ElCmprOverTe_D_Stat 3 "OverTempStop" 2 "OverTempWarning" 1 "Normal" 0 "Undefined" ;
VAL_ 958 ElCmprOverTe_D_Stat_UB 1 "Fresh_data" 0 "Unchanged_data" ;
VAL_ 958 EngOff_T_Actl 65535 "Invalid" ;
VAL_ 958 EngOff_T_Actl_UB 1 "Fresh_data" 0 "Unchanged_data" ;
VAL_ 958 StopStrtDrvMde_D_Indic_UB 1 "Fresh_data" 0 "Unchanged_data" ;
VAL_ 958 PrmtrAlrmEvnt_D_Stat 15 "Diag_Tamper" 14 "Trailer" 13 "Shock_Sensor" 12 "Post_Crash" 11 "Panic" 10 "Intrusion" 9 "Inclination" 8 "Ign_Tamper" 7 "LG_Door" 6 "Decklid" 5 "Hood" 4 "PR_Door" 3 "PF_Door" 2 "DR_Door" 1 "DF_Door" 0 "Null" ;
VAL_ 958 PrmtrAlrmEvnt_D_Stat_UB 1 "Fresh_data" 0 "Unchanged_data" ;
VAL_ 958 StopStrtDrvMde_D_Indic 3 "NotUsed" 2 "StartStop_IndirectDeselect" 1 "StopStart_Deselected" 0 "StopStart_Selected" ;
VAL_ 958 FuelLvl_Pc_Dsply_UB 1 "Fresh_data" 0 "Unchanged_data" ;
VAL_ 958 OdometerMasterValue_UB 1 "Fresh_data" 0 "Unchanged_data" ;
VAL_ 958 OdometerMasterValue 16777215 "Invalid" ;
VAL_ 827 LghtAmbIntns_D2_Sns 3 "Faulty" 2 "High" 1 "Medium" 0 "Low" ;
VAL_ 827 SteClmnSwtchTlt_D_Stat 3 "Unused" 2 "Down" 1 "Up" 0 "Null" ;
VAL_ 827 SteClmnSwtchTel_D_Stat 3 "Unused" 2 "Rearward" 1 "Forward" 0 "Null" ;
VAL_ 827 LghtAmbIntns_D_Sns 3 "Faulty" 2 "High" 1 "Low" 0 "Null" ;
VAL_ 902 Remote_Start_Req 3 "Not_Used" 2 "Remote_Cancel" 1 "Remote_Start" 0 "No_Request" ;
VAL_ 902 PrmtrAlrmWarn_B_Rq 1 "Active" 0 "Null" ;
VAL_ 902 PrmtrAlrmTrg_B_Rq 1 "Active" 0 "Null" ;
VAL_ 902 Panic_D_RqRsm 3 "NotUsed" 2 "On" 1 "Off" 0 "Null" ;
VAL_ 902 CellLock_D_RqRsm 7 "NotUsed3" 6 "NotUsed2" 5 "NotUsed1" 4 "TrunkRelPopGlassLgCargo" 3 "LockAllDoorsandTailgate" 2 "UnlockDriversDoor" 1 "UnlockAllDoorsandTailgate" 0 "NoRequest" ;
VAL_ 765 CcStat_D_Actl_UB 1 "Fresh_data" 0 "Unchanged_data" ;
VAL_ 765 CcStat_D_Actl 7 "Undefined_2" 6 "Undefined_1" 5 "Active" 4 "Active_Que_Assist" 3 "Standby" 2 "Standby_Denied" 1 "Denied" 0 "Off" ;
VAL_ 765 PrplTqMnSat_B_Actl_UB 1 "Fresh_data" 0 "Unchanged_data" ;
VAL_ 765 PrplTqMnSat_B_Actl 1 "Yes" 0 "No" ;
VAL_ 765 ClimtBlwrLim_B_Rq 1 "Request" 0 "NoRequest" ;
VAL_ 765 ClimtBlwrLim_B_Rq_UB 1 "Fresh_data" 0 "Unchanged_data" ;
VAL_ 765 TrlrBrkActCnnct_B_Actl_UB 1 "Fresh_data" 0 "Unchanged_data" ;
VAL_ 765 TrlrBrkActCnnct_B_Actl 1 "Yes" 0 "No" ;
VAL_ 765 EmPrflButtnAssoc_D_Rq 3 "NotUsed" 2 "ExitButtonAssociation" 1 "EnterButtonAssociation" 0 "Null" ;
VAL_ 765 EmPrflButtnAssoc_D_Rq_UB 1 "Fresh_data" 0 "Unchanged_data" ;
VAL_ 765 CamraFrntStat_D_Stat_UB 1 "Fresh_data" 0 "Unchanged_data" ;
VAL_ 765 CamraFrntStat_D_Stat 3 "No_Data_Present" 2 "NotUsed" 1 "On" 0 "Off" ;
VAL_ 765 AutoHoldSwMde_B_Ind_UB 1 "Fresh_data" 0 "Unchanged_data" ;
VAL_ 765 AutoHoldSwMde_B_Ind 1 "On" 0 "Off" ;
VAL_ 765 ValetMode_D_Stat_UB 1 "Fresh_data" 0 "Unchanged_data" ;
VAL_ 765 ValetMode_D_Stat 3 "NotUsed" 2 "On" 1 "Off" 0 "Null" ;
VAL_ 765 SteWhlHeat_D_Stat 15 "NotUsed6" 14 "NotUsed5" 13 "NotUsed4" 12 "NotUsed3" 11 "NotUsed2" 10 "NotUsed1" 9 "Reserved_3" 8 "Reserved_2" 7 "Reserved_1" 6 "Level_3_Heating" 5 "Level_3_Heating_LS" 4 "Level_2_Heating" 3 "Level_2_Heating_LS" 2 "Level_1_Heating" 1 "Level_1_Heating_LS" 0 "Off" ;
VAL_ 765 Running_Board_Cmd_UB 1 "Fresh_data" 0 "Unchanged_data" ;
VAL_ 765 Running_Board_Cmd 3 "Unused" 2 "Manually_Deployed" 1 "All_Enabled" 0 "All_Disabled" ;
VAL_ 765 Bezel_Beeps_Rq_UB 1 "Fresh_data" 0 "Unchanged_data" ;
VAL_ 765 Bezel_Beeps_Rq 0 "Inactive" 2 "Disable" 1 "Enable" ;
VAL_ 765 Diagnostic_Operation_Rq_UB 1 "Fresh_data" 0 "Unchanged_data" ;
VAL_ 765 Bezel_Diag_State_Rq_UB 1 "Fresh_data" 0 "Unchanged_data" ;
VAL_ 765 Bezel_Diag_Module_Rq_UB 1 "Fresh_data" 0 "Unchanged_data" ;
VAL_ 765 Diagnostic_Operation_Rq 7 "SignalStrength" 6 "SDARSESNNumber" 5 "SpeakerWalkAround" 4 "CalibrationPartNumber" 15 "Reserved" 3 "HardwarePartNumber" 2 "SoftwarePartNumber" 1 "GetAllBackgroundDiagRq" 0 "Inactive" ;
VAL_ 765 Bezel_Diag_State_Rq 1 "Active" 0 "Inactive" ;
VAL_ 765 Bezel_Diag_Module_Rq 15 "Reserved" 3 "EFP" 2 "DSP_AMP" 1 "AHU" 0 "Inactive" ;
VAL_ 765 HMI_HMIMode_St_UB 1 "Fresh_data" 0 "Unchanged_data" ;
VAL_ 765 HMI_HMIMode_St 7 "NotUsed2" 6 "NotUsed1" 5 "Load_Shed_Active" 0 "Invalid" 1 "OffMode" 2 "On" 3 "Phone" 4 "Climate" ;
VAL_ 765 Mc_VehUnitTempUsrSel_St_UB 1 "Fresh_data" 0 "Unchanged_data" ;
VAL_ 765 Mc_VehUnitTempUsrSel_St 0 "Temperature_deg_c" 1 "Temperature_deg_f" ;
VAL_ 765 PsngrFrntDetct_D_Actl_UB 1 "Fresh_data" 0 "Unchanged_data" ;
VAL_ 765 PsngrFrntDetct_D_Actl 3 "Unknown" 2 "Empty" 0 "Faulty" 1 "Occupied" ;
VAL_ 765 SteWhlHeat_D_Stat_UB 1 "Fresh_data" 0 "Unchanged_data" ;
VAL_ 765 PrkAidLamp_D_Rq 3 "Not_Used" 2 "Flash" 1 "On" 0 "Off" ;
VAL_ 765 PrkAidLamp_D_Rq_UB 1 "Fresh_data" 0 "Unchanged_data" ;
VAL_ 765 ParkDetect_Stat_UB 1 "Fresh_data" 0 "Unchanged_data" ;
VAL_ 765 ParkDetect_Stat 1 "Park" 0 "Not_Park" ;
VAL_ 765 Voice_Blower_Limit 1 "Request" 0 "NoRequest" ;
VAL_ 765 Voice_Blower_Limit_UB 1 "Fresh_data" 0 "Unchanged_data" ;
VAL_ 765 PwStep_D_DrvInhbt_UB 1 "Fresh_data" 0 "Unchanged_data" ;
VAL_ 765 PwStep_D_DrvInhbt 3 "NotUsed" 2 "DriveInhibitMalfunction" 1 "DriveInhibited" 0 "DriveNotInhibited" ;
VAL_ 556 Manual_Temp_Setting 31 "Full_Heat" 30 "Setting_30" 29 "Setting_29" 28 "Setting_28" 27 "Setting_27" 26 "Setting_26" 25 "Setting_25" 24 "Setting_24" 23 "Setting_23" 22 "Setting_22" 21 "Setting_21" 20 "Setting_20" 19 "Setting_19" 18 "Setting_18" 17 "Setting_17" 16 "Setting_16" 15 "Setting_15" 14 "Setting_14" 13 "Setting_13" 12 "Setting_12" 11 "Setting_11" 10 "Setting_10" 9 "Setting_9" 8 "Setting_8" 7 "Setting_7" 6 "Setting_6" 5 "Setting_5" 4 "Setting_4" 3 "Setting_3" 2 "Setting_2" 1 "Full_Cool" 0 "Off" ;
VAL_ 556 EFP_Bezel_Diag_St 15 "Reserved" 3 "CalibrationPartNumber" 2 "HardwarePartNumber" 1 "SoftwarePartNumber" 0 "Inactive_NOP" ;
VAL_ 556 Bezel_Beep_St 0 "Invalid" 2 "Disabled" 1 "Enabled" ;
VAL_ 556 Bezel_Beeps_Supported 2 "Not_Supported" 1 "Supported" 0 "Invalid" ;
VAL_ 556 PassRstrnInd_Stat 7 "Invalid" 6 "Unused_2" 5 "Unused_1" 4 "Both_Indicators_Faulted" 3 "AirbagOff_Indicator_fault" 2 "AirbagOn_Indicator_fault" 1 "Normal" 0 "Not_Supported" ;
VAL_ 359 PrplWhlRgenMn_Tq_Actl 8191 "Faulty" ;
VAL_ 359 ElPw_D_StatStrtStop 15 "NotUsed6" 14 "NotUsed5" 13 "NotUsed4" 12 "NotUsed3" 11 "NotUsed2" 10 "NotUsed1" 9 "Supported_Level_4" 8 "Supported_Level_3" 7 "Supported_Level_2" 6 "Supported_Level_1" 5 "Limited_Support" 4 "Fault_Limited" 3 "LV_Event_in_Progress" 2 "Not_Supported_Imminent" 1 "Supported_All" 0 "Not_Supported" ;
VAL_ 359 PrplWhlTot2_Tq_Actl 65535 "Fault" 65534 "NoDataExists" ;
VAL_ 359 LscmbbDeny_B_ActlPrpl 1 "Denied" 0 "Allowed" ;
VAL_ 359 LscmbbEngTqMn_B_Actl 1 "Engine_Braking_Activated" 0 "Engine_Braking_Off" ;
VAL_ 359 TrnAinTq_D_Qf 3 "OK" 2 "Not_Within_Specifications" 1 "No_Data_Exists" 0 "Faulty" ;
VAL_ 359 PwPckTq_D_Stat 3 "PwPckOn_TqAvailable" 2 "StartInPrgrss_TqNotAvail" 1 "PwPckOn_TqNotAvailable" 0 "PwPckOff_TqNotAvailable" ;
VAL_ 359 Eng_D_Stat 3 "NotUsed" 2 "EngAutoStopped" 1 "EngOn" 0 "EngOff" ;
VAL_ 359 PlgActvArb_B_Actl 1 "On" 0 "Off" ;
VAL_ 359 ElPw_D_Stat 7 "NotUsed_3" 6 "NotUsed_2" 5 "NotUsed_1" 4 "Fault_Limited" 3 "LV_Event_In_Progress" 2 "Not_Supported_Imminent" 1 "Supported" 0 "Not_Supported" ;
VAL_ 131 VehOnSrc_D_Stat_UB 1 "Fresh_data" 0 "Unchanged_data" ;
VAL_ 131 VehOnSrc_D_Stat 15 "NotUsed_11" 14 "NotUsed_10" 13 "NotUsed_9" 12 "NotUsed_8" 11 "NotUsed_7" 10 "NotUsed_6" 9 "EsclRssd" 8 "AutonomousVehicle" 7 "SecureIdle" 6 "FleetVehicleInhibit" 5 "StolenVehicleInhibit" 4 "OverTheAir" 3 "RemoteParkAssist" 2 "RemoteStart" 1 "Manual" 0 "Off" ;
VAL_ 131 StePinCompAnEst_D_Qf 3 "OK" 2 "Degraded" 1 "No_Data_Exists" 0 "Faulty" ;
VAL_ 131 StePinComp_An_Est_UB 1 "Fresh_data" 0 "Unchanged_data" ;
VAL_ 131 VehLongComp_A_Actl_UB 1 "Fresh_data" 0 "Unchanged_data" ;
VAL_ 131 VehLatComp_A_Actl_UB 1 "Fresh_data" 0 "Unchanged_data" ;
VAL_ 131 VehLongComp_A_Actl 1023 "Fault" 1022 "NoDataExists" ;
VAL_ 131 VehLatComp_A_Actl 1023 "Fault" 1022 "NoDataExists" ;
VAL_ 131 VehYaw_W_Actl_UB 1 "Fresh_data" 0 "Unchanged_data" ;
VAL_ 131 VehYaw_W_Actl 65535 "Faulty" 65534 "NoDataExists" ;
VAL_ 990 PersIndexDdm_D_Actl 7 "Unused_3" 6 "Unused_2" 5 "Unused_1" 4 "Vehicle" 3 "PERS_4" 2 "PERS_3" 1 "PERS_2" 0 "PERS_1" ;
VAL_ 1246 TrlrBrkCtl2_B_Falt 1 "True" 0 "False" ;
VAL_ 1003 TailLghtLoadMde_D_Stat 7 "Faulty" 6 "NotUsed_2" 5 "NotUsed_1" 4 "TailLightModeOverride" 3 "FalrModeActive" 2 "HitchLoadModeActive" 1 "PayloadModeActive" 0 "NoTailLightActive" ;
VAL_ 1003 Pers4Key_D_Stat 3 "NotUsed_1" 2 "KeyUnAssociated" 1 "KeyAssociated" 0 "Null" ;
VAL_ 1003 Pers3Key_D_Stat 3 "NotUsed_1" 2 "KeyUnAssociated" 1 "KeyAssociated" 0 "Null" ;
VAL_ 1003 Pers2Key_D_Stat 3 "NotUsed_1" 2 "KeyUnAssociated" 1 "KeyAssociated" 0 "Null" ;
VAL_ 1003 Pers1Key_D_Stat 3 "NotUsed_1" 2 "KeyUnAssociated" 1 "KeyAssociated" 0 "Null" ;
VAL_ 1003 EmPrflNo_D_Stat 7 "NotUsed_3" 6 "NotUsed_2" 5 "NotUsed_1" 4 "Pers4" 3 "Pers3" 2 "Pers2" 1 "Pers1" 0 "Null" ;
VAL_ 1003 EmPrflKeyAssoc_D_Stat 7 "WrongDevice" 6 "KeyAssociateFailed" 5 "KeyAssociateSuccess" 4 "KeyAlreadyInUse" 3 "KeyDisassociated" 2 "KeyAssociationExited" 1 "KeyAssociationEntered" 0 "Null" ;
VAL_ 1003 PersRecallSrc_D_Actl 7 "NotUsed_3" 6 "NotUsed_2" 5 "NotUsed_1" 4 "MemorySwitch" 3 "RemoteStart" 2 "KeyFob" 1 "CenterStack" 0 "Null" ;
VAL_ 1003 VehKeyActv_D_Stat 15 "NotUsed7" 14 "NotUsed6" 13 "NotUsed5" 12 "NotUsed4" 11 "NotUsed3" 10 "NotUsed2" 9 "NotUsed1" 8 "Key8Active" 7 "Key7Active" 6 "Key6Active" 5 "Key5Active" 4 "Key4Active" 3 "Key3Active" 2 "Key2Active" 1 "Key1Active" 0 "NoKeyActive" ;
VAL_ 1003 PersSetupRestr_D_Actl 3 "Non_Moveable_Person" 2 "Moveable_Person" 1 "Vehicle" 0 "Factory" ;
VAL_ 1003 PersSetupAccessCtrl 1 "Limited" 0 "Full" ;
VAL_ 1003 PersConflict_D_Actl 1 "Conflict" 0 "No_Conflict" ;
VAL_ 1003 AssocConfirm_D_Actl 0 "None" 7 "Associate" 6 "Keycode_Rejected" 5 "Keycode_Accepted" 4 "In_Progress" 3 "Erase" 2 "Duplicate" 1 "Disassociate" ;
VAL_ 1003 PersNo_D_Actl 7 "Unused_3" 6 "Unused_2" 5 "NotDetermined" 4 "Vehicle" 3 "PERS_4" 2 "PERS_3" 1 "PERS_2" 0 "PERS_1" ;
VAL_ 1003 PersNoPos_D_Actl 7 "Unused_3" 6 "Unused_2" 5 "Unused_1" 4 "Vehicle" 3 "PERS_4" 2 "PERS_3" 1 "PERS_2" 0 "PERS_1" ;
VAL_ 836 FohFalt_D_Stat 15 "NotUsed4" 14 "NotUsed3" 13 "NotUsed2" 12 "NotUsed1" 11 "FuelTypeDoesNotMatchFOH" 10 "Lifecycle_ModeNotSet" 9 "AuxElectricCoolantPumpInop" 8 "TimeDelayAvoidExcessCycl" 7 "Fuel_Level_OutofRange" 6 "External_Fault" 5 "Internal_Fault" 4 "Voltage_limitation" 3 "Impact_Event" 2 "CoolantTemp_OutofRange" 1 "AmbientTemp_OutofRange" 0 "No_Disable" ;
VAL_ 836 FohEnbl_B_RqDrv 1 "On" 0 "Off" ;
VAL_ 836 FohRqRun_B_Rq 1 "SubmitRequest_toRun" 0 "DoesNotSubmitRequest_toRun" ;
VAL_ 836 HvacPrecondMode_D_Rq 15 "NotUsed4" 14 "NotUsed3" 13 "NotUsed2" 12 "NotUsed1" 11 "Last_User_Settings" 10 "Auto" 9 "Max_Defrost" 8 "Windshield_Panel_Floor" 7 "Windshield_Panel" 6 "Windshield" 5 "Windshield_Floor" 4 "Floor" 3 "Panel_Floor" 2 "Panel" 1 "MAX_AC" 0 "Off" ;
VAL_ 836 HvacPrecondBlwr_D_Rq 15 "NotUsed6" 14 "NotUsed5" 13 "NotUsed4" 12 "NotUsed3" 11 "NotUsed2" 10 "NotUsed1" 9 "Last_User_Setting" 8 "Auto" 7 "Speed7" 6 "Speed6" 5 "Speed5" 4 "Speed4" 3 "Speed3" 2 "Speed2" 1 "Speed1" 0 "Off" ;
VAL_ 836 Foh_D_Stat 7 "Unused3" 6 "Unused2" 5 "Unused1" 4 "Stopping" 3 "Running" 2 "Starting" 1 "Prestart" 0 "Off" ;
VAL_ 836 EngClnt_Te_ActlFoh 255 "Fault" ;
VAL_ 819 WndwUpPsngrRear_D_Falt 3 "NotUsed" 2 "Fault" 1 "NoFault" 0 "Null" ;
VAL_ 819 WndwUpPsngrFront_D_Falt 3 "NotUsed" 2 "Fault" 1 "NoFault" 0 "Null" ;
VAL_ 819 DrPrsntPsngr_D_Stat 3 "Faulty" 2 "Present" 1 "NotPresent" 0 "NotDetermined" ;
VAL_ 819 DrPsngrMsgTxt_B_Rq 1 "Yes" 0 "No" ;
VAL_ 819 DrPrsntRearPsngr_D_Stat 3 "Faulty" 2 "Present" 1 "NotPresent" 0 "NotDetermined" ;
VAL_ 819 Memory_3_SwPsngr_Stat 1 "Pressed" 0 "Null" ;
VAL_ 819 Memory_2_SwPsngr_Stat 1 "Pressed" 0 "Null" ;
VAL_ 819 Memory_1_SwPsngr_Stat 1 "Pressed" 0 "Null" ;
VAL_ 819 BLISLEDStatPassSide 3 "Fault" 2 "Unused" 1 "On" 0 "Off" ;
VAL_ 819 WndwPsngrSide_D_Stat 3 "BothWindow_Operating" 2 "RearWindow_Operating" 1 "FrontWindow_Operating" 0 "NoWindows_Operating" ;
VAL_ 819 Pasngr_Lock_Sw_Stat 3 "Invalid" 2 "Unlock" 1 "Lock" 0 "Null" ;
VAL_ 819 ChildLckFdbckRp_B_Stat 1 "Locked" 0 "Unlock" ;
VAL_ 818 WndwUpDrvRear_D_Falt 3 "NotUsed" 2 "Fault" 1 "NoFault" 0 "Null" ;
VAL_ 818 WndwUpDrvFront_D_Falt 3 "NotUsed" 2 "Fault" 1 "NoFault" 0 "Null" ;
VAL_ 818 DrvSpotLight_B_Stat 1 "Active" 0 "Inactive" ;
VAL_ 818 DrPrsntDrv_D_Stat 3 "Faulty" 2 "Present" 1 "NotPresent" 0 "NotDetermined" ;
VAL_ 818 DrPrsntRearDrv_D_Stat 3 "Faulty" 2 "Present" 1 "NotPresent" 0 "NotDetermined" ;
VAL_ 818 DrDrvMsgTxt_B_Rq 1 "Yes" 0 "No" ;
VAL_ 818 BLISLEDStatDriverSide 3 "Fault" 2 "Unused" 1 "On" 0 "Off" ;
VAL_ 818 WndwDrvSide_D_Stat 3 "BothWindow_Operating" 2 "RearWindow_Operating" 1 "FrontWindow_Operating" 0 "NoWindows_Operating" ;
VAL_ 818 KeyCylSwDrvDr_D_Stat 3 "NotUsed" 2 "Unlock" 1 "Lock" 0 "Null" ;
VAL_ 818 Driver_Lock_Sw_Stat 3 "Invalid" 2 "Unlock" 1 "Lock" 0 "Null" ;
VAL_ 818 ChildLckPw_D_Rq 1 "Active" 0 "Null" ;
VAL_ 818 ChildLckFdbckRd_B_Stat 1 "Locked" 0 "Unlock" ;
VAL_ 818 RvrseMirrorChime_B_Rq 1 "Yes" 0 "No" ;
VAL_ 817 ChildLckMde_B_Stat 1 "Enable" 0 "Disable" ;
VAL_ 817 VehLckInd_D_Rq 3 "NotUsed" 2 "On_Day" 1 "On_Night" 0 "Off" ;
VAL_ 817 DrTgateOpen_B_Rq 1 "Open" 0 "Null" ;
VAL_ 817 DrTgateExtSwMde_B_Stat 1 "Enable" 0 "Disable" ;
VAL_ 817 Remote_Device_Feedback 7 "Unused3" 6 "Unused2" 5 "Unused1" 4 "Shutdown" 3 "Running" 2 "Starting" 1 "Acknowledge" 0 "Null" ;
VAL_ 817 R_Pwr_Sliding_Dr_Rqst 1 "Active" 0 "Null" ;
VAL_ 817 Power_Liftgate_Rqst 1 "Active" 0 "Null" ;
VAL_ 817 Power_Decklid_Rqst 1 "Active" 0 "Null" ;
VAL_ 817 L_Pwr_Sliding_Dr_Rqst 1 "Active" 0 "Null" ;
VAL_ 817 Veh_Lock_Requestor 31 "Walk_Away_Locking" 30 "Remote_Park_Assist" 29 "DoorsOffToOn_Smart_Unlock" 28 "Rgtm_Shutlock_Switch" 27 "Boundary_Alert" 26 "Transit_Vehicle_Relock" 25 "Transit_Cargo_Relock" 24 "Transit_Ajar_Lock" 23 "Diagnostics" 22 "Console_Lock" 21 "Child_Lock" 20 "Double_Lock" 19 "Passive_Pasenger" 18 "Passive_Driver" 17 "Slam_Lock_Protect" 16 "SYNC" 15 "Passport" 14 "Passive_Smart_Unlock" 13 "Autorelock" 12 "RemoteStart" 0 "Null" 1 "Autolock" 11 "Smart_Unlock" 10 "Sliding_Door" 9 "Passive" 8 "Remote" 7 "Programming" 6 "Powerslide" 5 "Keypad" 4 "Key_Cylinder" 3 "Interior" 2 "Auto_Unlock" ;
VAL_ 817 Veh_Lock_Sub_Id 15 "Unused7" 14 "Unused6" 13 "Unused5" 12 "Unused4" 11 "Unused3" 10 "Unused2" 9 "Unused1" 8 "Customer_8" 7 "Customer_7" 6 "Customer_6" 5 "Customer_5" 4 "Customer_4" 3 "Customer_3" 2 "Customer_2" 1 "Customer_1" 0 "Null" ;
VAL_ 817 ChildLck_D_Dsply 3 "NOT_SUPPORTED" 2 "ERROR" 1 "CHILD_UNLOCK" 0 "CHILD_LOCK" ;
VAL_ 817 WindowLockout_B_Stat 1 "Locked" 0 "Unlock" ;
VAL_ 817 Lockmsgtxt_D_Rq 7 "MSG7" 6 "MSG6" 5 "MSG5" 4 "MSG4" 3 "MSG3" 2 "MSG2" 1 "MSG1" 0 "NO_WARNING" ;
VAL_ 817 LockInhibit 1 "Inhibit" 0 "No_Inhibit" ;
VAL_ 817 Veh_Lock_Status 3 "UNLOCK_DRV" 2 "UNLOCK_ALL" 1 "LOCK_ALL" 0 "LOCK_DBL" ;
VAL_ 817 FobComm_D_Stat 3 "NotUsed" 2 "RemEngStartOK" 1 "RemEngStartFail" 0 "Null" ;
VAL_ 1091 CamraRearOn_D2_Stat2 7 "Faulty" 6 "NotUsed_3" 5 "NotUsed_2" 4 "NotUsed_1" 3 "Decommission" 2 "Activate" 1 "Deactivate" 0 "Null" ;
VAL_ 1091 PoliceAux4Lamp_B_Rq2 1 "On" 0 "Off" ;
VAL_ 1091 PoliceAux3Lamp_B_Rq2 1 "On" 0 "Off" ;
VAL_ 1091 PoliceAux2Lamp_B_Rq2 1 "On" 0 "Off" ;
VAL_ 1091 PoliceAux1Lamp_B_Rq2 1 "On" 0 "Off" ;
VAL_ 1091 WakeAlarm2_B_Typ 1 "CanAndEcuDriveCircuit" 0 "CanOnly" ;
VAL_ 1091 TrlrAlarmSpprt_D_Stat 3 "SupportedByBrakesAndLights" 2 "SupportedByLights" 1 "SupportedByBrakes" 0 "NotSupported" ;
VAL_ 1091 TowBarMsgTxt_D_Rq 7 "NotUsed3" 6 "NotUsed2" 5 "NotUsed1" 4 "TowBar_Ext_No_Trlr" 3 "Error_Dealer_Fix" 2 "Start_Engine_Swivel" 1 "Check_Tow_Bar" 0 "Null" ;
VAL_ 1091 ParkLampTrlrOut_B_Stat 1 "Out" 0 "Null" ;
VAL_ 1091 TrlrLampCtl_D_Stat 3 "NotUsed" 2 "TrlrLampCnnctDrvFailure" 1 "TrlrLampNotCnnctDrvFailure" 0 "Null" ;
VAL_ 1091 TrlrBattChrg_D_Stat 3 "Reverse" 2 "Normal" 1 "Low" 0 "Null" ;
VAL_ 1091 StopLampTrlrOut_B_Stat 1 "Out" 0 "Null" ;
VAL_ 1091 TurnLampTrlrRr_B_Stat 1 "Out" 0 "Null" ;
VAL_ 1091 TurnLampTrlrRl_B_Stat 1 "Out" 0 "Null" ;
VAL_ 1091 TrlrLampCnnct_B_Actl 1 "Yes" 0 "No" ;
VAL_ 1066 BattULo_U_Actl_UB 1 "Fresh_data" 0 "Unchanged_data" ;
VAL_ 1066 BattULo_U_Actl 255 "Fault" ;
VAL_ 1066 PwSrcULo_I_Mx 255 "Fault" ;
VAL_ 1066 PwSrcULo_I_Actl 255 "Fault" ;
VAL_ 1066 PwSrcULo_I_Mx_UB 1 "Fresh_data" 0 "Unchanged_data" ;
VAL_ 1066 PwSrcULo_I_Actl_UB 1 "Fresh_data" 0 "Unchanged_data" ;
VAL_ 994 PersCtaSplitView_D_Rq 3 "EnabledFull" 2 "Enabled_180SwitchOnly" 1 "Disabled" 0 "Null" ;
VAL_ 994 Pers4OptIn_B_Stats 1 "OPTED_IN" 0 "NOT_OPTED_IN" ;
VAL_ 994 Pers3OptIn_B_Stats 1 "OPTED_IN" 0 "NOT_OPTED_IN" ;
VAL_ 994 Pers2OptIn_B_Stats 1 "OPTED_IN" 0 "NOT_OPTED_IN" ;
VAL_ 994 Pers1OptIn_B_Stats 1 "OPTED_IN" 0 "NOT_OPTED_IN" ;
VAL_ 994 CtrStkPersIndex_D_Actl 7 "Unused_3" 6 "Unused_2" 5 "Unused_1" 4 "Vehicle" 3 "PERS_4" 2 "PERS_3" 1 "PERS_2" 0 "PERS_1" ;
VAL_ 994 CtrStkDsplyOp_D_Rq 7 "Unused_2" 6 "Unused_1" 5 "Copy" 4 "Restore" 3 "Upload" 2 "Set" 1 "Query" 0 "Null" ;
VAL_ 994 PersStore_D_Rq 7 "Unused_2" 6 "Unused_1" 5 "Vehicle" 4 "PERS_4" 3 "PERS_3" 2 "PERS_2" 1 "PERS_1" 0 "Null" ;
VAL_ 376 GasPrtc_D_RqDsply 7 "NotUsed_5" 6 "NotUsed_4" 5 "NotUsed_3" 4 "NotUsed_2" 3 "NotUsed_1" 2 "GpfOverLimit" 1 "GpfAtLimit" 0 "NormalOperation" ;
VAL_ 376 AslIconDsply_D_Rq 3 "On_Passive_Overridden" 2 "On_Active" 1 "On_Passive" 0 "Off" ;
VAL_ 376 AslChime_B_Rq 1 "Yes" 0 "No" ;
VAL_ 376 PtcHtr_D_Cmd 3 "TurnOn" 2 "AutoMode" 1 "TurnOff" 0 "NoDecision_Initializing" ;
VAL_ 376 HvacHtrCore2_Te_Actl 1023 "Faulty" ;
VAL_ 376 LnchCtlSys_D_Stat 7 "NotUsed3" 6 "NotUsed2" 5 "NotUsed1" 4 "On_LC_Unavailable_TC_On" 3 "On_LC_Unavailable" 2 "On_LC_Available" 1 "On_LC_Active" 0 "LC_OFF" ;
VAL_ 376 EcssLamp_D_RqDsply 3 "Not_Used" 2 "Flash" 1 "On" 0 "Off" ;
VAL_ 376 AirAmbTe_D_Qf 3 "OK" 2 "Not_Within_Specifications" 1 "No_Data_Exists" 0 "Faulty" ;
VAL_ 376 DynoMde_B_Cmd 1 "DynomometerMode" 0 "NormalOperation" ;
VAL_ 376 AirAmb_P_Actl 63 "Fault" 62 "NoDataExists" ;
VAL_ 1068 HvacAirFullOut_B_Rq_UB 1 "Fresh_data" 0 "Unchanged_data" ;
VAL_ 1068 HvacAirFullOut_B_Rq 1 "Yes" 0 "No" ;
VAL_ 1068 HvacCmprLim_D_Stat_UB 1 "Fresh_data" 0 "Unchanged_data" ;
VAL_ 1068 HvacCmprLim_D_Stat 7 "NotUsed_2" 6 "NotUsed_1" 5 "CompressorHeadPressure" 4 "AvailableTorque" 3 "PedalPosition" 2 "RPM" 1 "ECT" 0 "NoLimit" ;
VAL_ 1068 HvacAirFlw_B_RqBatt_UB 1 "Fresh_data" 0 "Unchanged_data" ;
VAL_ 1068 HvacAirFlw_B_RqBatt 1 "Request" 0 "NoRequest" ;
VAL_ 1068 HvacRec_D_RqMxBatt_UB 1 "Fresh_data" 0 "Unchanged_data" ;
VAL_ 1068 HvacRec_D_RqMxBatt 15 "NotUsed5" 14 "NotUsed4" 13 "NotUsed3" 12 "NotUsed2" 11 "NotUsed1" 10 "No_Override" 9 "90Percent_RecircMax" 8 "80Percent_RecircMax" 7 "70Percent_RecircMax" 6 "60Percent_RecircMax" 5 "50Percent_RecircMax" 4 "40Percent_RecircMax" 3 "30Percent_RecircMax" 2 "20Percent_RecircMax" 1 "10Percent_RecircMax" 0 "0Percent_RecircFullOpen" ;
VAL_ 1068 Batt_Lo_SoC_B_UB 1 "Fresh_data" 0 "Unchanged_data" ;
VAL_ 1068 Batt_Lo_SoC_B 1 "Active" 0 "Inactive" ;
VAL_ 1068 Batt_Crit_SoC_B_UB 1 "Fresh_data" 0 "Unchanged_data" ;
VAL_ 1068 Batt_Crit_SoC_B 1 "Active" 0 "Inactive" ;
VAL_ 1068 Shed_T_Eng_Off_B_UB 1 "Fresh_data" 0 "Unchanged_data" ;
VAL_ 1068 Shed_T_Eng_Off_B 1 "Active" 0 "Inactive" ;
VAL_ 1068 Shed_Level_Req_UB 1 "Fresh_data" 0 "Unchanged_data" ;
VAL_ 1068 Shed_Level_Req 7 "SHED3" 6 "Loads_On" 5 "SHED_ENG_OFF" 4 "SOON_ENG_OFF" 3 "SHED2_CONTIN" 2 "SHED2_TRANS" 1 "SHED1" 0 "NO_SHED" ;
VAL_ 1068 Shed_Feature_Group_ID_UB 1 "Fresh_data" 0 "Unchanged_data" ;
VAL_ 1068 Shed_Feature_Group_ID 16 "PtcHeater" 30 "NotUsed_7" 29 "NotUsed_6" 28 "NotUsed_5" 27 "NotUsed_4" 26 "NotUsed_3" 25 "NotUsed_2" 24 "NotUsed_1" 23 "Dcac" 22 "UpFitter_6" 21 "UpFitter_5" 20 "UpFitter_4" 19 "UpFitter_3" 18 "UpFitter_2" 17 "UpFitter_1" 14 "HtdMirr" 13 "HvacRearBlwr_Third" 12 "HvacRearBlwr_Second" 11 "HvacRearBlwr_First" 31 "All LSHED1 Features" 10 "Htd_Windscrn" 9 "SpltHtdBcklight_HtdMirr" 8 "HtdBcklight_HtdMirr" 7 "HtdCoolSeat_FrtDriver" 6 "HtdCoolSeat_FrtPass" 5 "HtdCoolSeat_RearPass" 4 "HtdCoolSeat_RearDriver" 3 "SmartTrlrTowBattCharge" 2 "Htd_StrWhl" 1 "Htd_Washer_Fluid" 0 "No_LSHED1_Features" 15 "Engine_Coolant_Fan" ;
VAL_ 1068 Shed_Drain_Eng_Off_B_UB 1 "Fresh_data" 0 "Unchanged_data" ;
VAL_ 1068 Shed_Drain_Eng_Off_B 1 "Active" 0 "Inactive" ;
VAL_ 1068 HvacAir_Flw_EstBatt_UB 1 "Fresh_data" 0 "Unchanged_data" ;
VAL_ 1068 HvacAir_Flw_EstBatt 255 "Invalid" ;
VAL_ 1068 AirCondRec_B_Rq_UB 1 "Fresh_data" 0 "Unchanged_data" ;
VAL_ 1068 AirCondFluidHi_P_Actl_UB 1 "Fresh_data" 0 "Unchanged_data" ;
VAL_ 1068 AirCondClutch_B_Stats_UB 1 "Fresh_data" 0 "Unchanged_data" ;
VAL_ 1068 AirCondRec_B_Rq 1 "Yes" 0 "No" ;
VAL_ 1068 AirCondFluidHi_P_Actl 255 "Fault" 254 "Unknown" ;
VAL_ 1068 AirCondClutch_B_Stats 1 "Yes" 0 "No" ;
VAL_ 963 Illuminated_Entry_Stat 3 "Invalid" 2 "Unknown" 1 "On" 0 "Off" ;
VAL_ 963 Dr_Courtesy_Light_Stat 3 "Invalid" 2 "Unknown" 1 "On" 0 "Off" ;
VAL_ 963 ImpactEvntFdbck_D_Stat 3 "NotUsed" 2 "EventComplete" 1 "EventInProgress" 0 "Normal" ;
VAL_ 963 DrTgateLck_D_Stat 3 "NotUsed" 2 "Unlock" 1 "Lock" 0 "Null" ;
VAL_ 963 PudLampPsngr_D_Rq 3 "Ramp_Down" 2 "Ramp_Up" 1 "On" 0 "Off" ;
VAL_ 963 HeadLampLoOut_B_Stat 1 "Out" 0 "Null" ;
VAL_ 963 HeadLghtHiFdbck_D_Stat 3 "NotUsed" 2 "Cancel" 1 "Hold" 0 "Allow_Change" ;
VAL_ 963 PrkLightChime_B_Rq 1 "On" 0 "Off" ;
VAL_ 963 TrnNotInPrkChime_B_Rq 1 "On" 0 "Off" ;
VAL_ 963 HomeSafeLtChime_B_Rq 1 "On" 0 "Off" ;
VAL_ 963 StopLghtOn_B_Stat 1 "On" 0 "Off" ;
VAL_ 963 RvrseLghtOn_B_Stat 1 "On" 0 "Off" ;
VAL_ 963 PrkLght_D_Stat 3 "Park_Both" 2 "Park_Right" 1 "Park_Left" 0 "Off" ;
VAL_ 963 HeadLghtSwtch_D_Stat 3 "Autolamp" 2 "Headlamp" 1 "Parklamp" 0 "Off" ;
VAL_ 963 KeyInIgnWarn_B_Cmd 1 "On" 0 "Off" ;
VAL_ 963 HeadLampLoFrOn_B_Stat 1 "Low" 0 "Not_Low" ;
VAL_ 963 HeadLampLoFlOn_B_Stat 1 "Low" 0 "Not_Low" ;
VAL_ 963 Headlamp_On_Wrning_Cmd 1 "On" 0 "Off" ;
VAL_ 963 HeadLampLoActv_B_Stat 1 "On" 0 "Off" ;
VAL_ 963 HeadLghtHiOn_B_Stat 1 "On" 0 "Off" ;
VAL_ 963 Park_Brake_Chime_Rqst 1 "On" 0 "Off" ;
VAL_ 963 BrkWarnInd_B_Rq 1 "On" 0 "Off" ;
VAL_ 963 Brk_Fluid_Lvl_Low 3 "Invalid" 2 "Unknown" 1 "Low" 0 "OK" ;
VAL_ 963 ReducedGuard_D_Stat 3 "NotUsed" 2 "Alarm_On" 1 "Alarm_Off_Previously_On" 0 "Alarm_Off" ;
VAL_ 963 Courtesy_BSave_Stat 3 "Invalid" 2 "Unknown" 1 "No_Effect" 0 "Off" ;
VAL_ 963 DayRnngLampOn_B_Stat 1 "On" 0 "Off" ;
VAL_ 963 PerimeterAlarmChimeRq 1 "On" 0 "Off" ;
VAL_ 963 PudLampDrv_D_Rq 3 "Ramp_Down" 2 "Ramp_Up" 1 "On" 0 "Off" ;
VAL_ 963 Courtesy_Delay_Status 3 "Invalid" 2 "Unknown" 1 "On" 0 "Off" ;
VAL_ 963 Perimeter_Alarm_Status 3 "Activated" 2 "Armed" 1 "Prearmed" 0 "Disarmed" ;
VAL_ 963 WndwGlbl_D_Cmd 7 "NotUsed3" 6 "NotUsed2" 5 "NotUsed1" 4 "GLEARN" 3 "GCLOSE" 2 "GOPEN" 1 "GSTOP" 0 "Null" ;
VAL_ 963 PudLamp_D_Rq 3 "RAMP_DOWN" 2 "RAMP_UP" 1 "ON" 0 "OFF" ;
VAL_ 964 FohEng_D_Rq_UB 1 "Fresh_data" 0 "Unchanged_data" ;
VAL_ 964 FohEng_D_Rq 3 "AutoEnable_ParkEnable" 2 "AutoDisable_ParkEnable" 1 "AutoEnable_ParkDisable" 0 "Disable_Stop" ;
VAL_ 964 EcoMode_B_Stat_UB 1 "Fresh_data" 0 "Unchanged_data" ;
VAL_ 964 Cta_D_Rq_UB 1 "Fresh_data" 0 "Unchanged_data" ;
VAL_ 964 Cta_D_Rq 3 "Unused" 2 "NoDataExists" 1 "On" 0 "Off" ;
VAL_ 964 GearRvrse_D_Actl_UB 1 "Fresh_data" 0 "Unchanged_data" ;
VAL_ 964 GearRvrse_D_Actl 7 "Fault" 6 "NotUsed_3" 5 "NotUsed_2" 4 "NotUsed_1" 3 "Active_confirmed" 2 "Active_not_confirmed" 1 "Inactive_confirmed" 0 "Inactive_not_confirmed" ;
VAL_ 964 TurnLghtSwtch_D_Stat_UB 1 "Fresh_data" 0 "Unchanged_data" ;
VAL_ 964 TurnLghtSwtch_D_Stat 3 "Unused_Treat_As_Off" 2 "Right" 1 "Left" 0 "Off" ;
VAL_ 964 Power_Liftgate_Mode_Cmd_UB 1 "Fresh_data" 0 "Unchanged_data" ;
VAL_ 964 Power_Liftgate_Mode_Cmd 1 "Enable" 0 "Disable" ;
VAL_ 964 EcoMode_B_Stat 1 "On" 0 "Off" ;
VAL_ 964 MetricActvTe_B_Actl_UB 1 "Fresh_data" 0 "Unchanged_data" ;
VAL_ 964 MetricActvTe_B_Actl 1 "Active" 0 "Inactive" ;
VAL_ 964 EngClntTe_D_Qf 3 "OK" 2 "Not_Within_Specifications" 1 "No_Data_Exists" 0 "Faulty" ;
VAL_ 964 Sod_D_Rq 2 "BLIS_On_Second_Warning_ON" 1 "BLIS_On_Second_Warning_OFF" 0 "Off" ;
VAL_ 964 MetricActv_B_Actl 1 "Active" 0 "Inactive" ;
VAL_ 964 MetricActv_B_Actl_UB 1 "Fresh_data" 0 "Unchanged_data" ;
VAL_ 964 EngClnt_Te_Actl_UB 1 "Fresh_data" 0 "Unchanged_data" ;
VAL_ 964 OCSSensrDataUpperLim_UB 1 "Fresh_data" 0 "Unchanged_data" ;
VAL_ 964 OCSSensrDataUpperLim 255 "Invalid" ;
VAL_ 964 OCSSensrDataLowerLim_UB 1 "Fresh_data" 0 "Unchanged_data" ;
VAL_ 964 PrkAid_D_Falt 7 "NotUsed2" 6 "NotUsed1" 5 "Failure_Front_PSM_Sensors" 4 "No_Data_Exists" 3 "Failure_Rear_Sensors" 2 "Speaker_Fault" 1 "ECU_Fault" 0 "No_Fault" ;
VAL_ 964 OCSSensrDataLowerLim 255 "Invalid" ;
VAL_ 964 PrkAid_D_Falt_UB 1 "Fresh_data" 0 "Unchanged_data" ;
VAL_ 964 WiprFront_D_Stat_UB 1 "Fresh_data" 0 "Unchanged_data" ;
VAL_ 964 WiprFront_D_Stat 15 "NO_DATA_EXISTS" 14 "STALLED" 13 "RESERVED" 12 "AUTO_ADJUST" 11 "COURTESYWIPE" 10 "AUTO_HIGH" 9 "AUTO_LOW" 8 "WASH" 7 "MIST_FLICK" 6 "MAN_HIGH" 5 "MAN_LOW" 4 "MAN_INT_ON" 3 "MAN_INT_OFF" 2 "OFF_MOVING" 1 "AUTO_OFF" 0 "OFF" ;
VAL_ 964 CamraDefog_B_Req_UB 1 "Fresh_data" 0 "Unchanged_data" ;
VAL_ 964 Sod_D_Rq_UB 1 "Fresh_data" 0 "Unchanged_data" ;
VAL_ 964 CamraDefog_B_Req 1 "On" 0 "Off" ;
VAL_ 993 StmsScrnDrvOn_B_Rq 1 "On" 0 "Off" ;
VAL_ 993 EmButtn_D_Stat 7 "ButtonAssociationFailed" 6 "ButtonAssociationExited" 5 "ButtonAssociationEntered" 4 "Button4Pressed" 3 "Button3Pressed" 2 "Button2Pressed" 1 "Button1Pressed" 0 "Null" ;
VAL_ 993 MemStoreMsgTxt_D_Rq 10 "NotUsed_2" 9 "NotUsed_1" 8 "Mem4Saved_ShowLinkMsg" 7 "Mem3Saved_ShowLinkMsg" 6 "Mem2Saved_ShowLinkMsg" 5 "Mem1Saved_ShowLinkMsg" 4 "Mem4Saved_DoNotShowLinkMsg" 3 "Mem3Saved_DoNotShowLinkMsg" 2 "Mem2Saved_DoNotShowLinkMsg" 1 "Mem1Saved_DoNotShowLinkMsg" 0 "Null" ;
VAL_ 993 MemSetButtnMsgTxt_D_Rq 3 "NotUsed" 2 "Press1or2or3" 1 "Press1or2" 0 "Null" ;
VAL_ 993 PersStore_D_Actl 3 "Unused" 2 "Null" 1 "InProgress" 0 "Complete" ;
VAL_ 993 MemSwtch_D_RqRecall 7 "Unused_3" 6 "Unused_2" 5 "Unused_1" 4 "PERS_4" 3 "PERS_3" 2 "PERS_2" 1 "PERS_1" 0 "Null" ;
VAL_ 993 MemSwtch_D_RqAssoc 7 "Unused_3" 6 "Unused_2" 5 "Unused_1" 4 "PERS_4" 3 "PERS_3" 2 "PERS_2" 1 "PERS_1" 0 "Null" ;
VAL_ 993 PersIndexDsm_D_Actl 7 "Unused_3" 6 "Unused_2" 5 "Unused_1" 4 "Vehicle" 3 "PERS_4" 2 "PERS_3" 1 "PERS_2" 0 "PERS_1" ;
